VERSION ""

NS_ :

BS_:

BU_:

BO_ 2619670270 TIM21: 16 Vector__XXX
 SG_ RequestCounterAuxValve32 m32 : 8|4@1+ (1,0) [0|0] "" Vector__XXX
 SG_ RequestCounterAuxValve31 m31 : 8|4@1+ (1,0) [0|0] "" Vector__XXX
 SG_ RequestCounterAuxValve30 m30 : 8|4@1+ (1,0) [0|0] "" Vector__XXX
 SG_ RequestCounterAuxValve29 m29 : 8|4@1+ (1,0) [0|0] "" Vector__XXX
 SG_ RequestCounterAuxValve28 m28 : 8|4@1+ (1,0) [0|0] "" Vector__XXX
 SG_ RequestCounterAuxValve27 m27 : 8|4@1+ (1,0) [0|0] "" Vector__XXX
 SG_ RequestCounterAuxValve26 m26 : 8|4@1+ (1,0) [0|0] "" Vector__XXX
 SG_ RequestCounterAuxValve25 m25 : 8|4@1+ (1,0) [0|0] "" Vector__XXX
 SG_ RequestCounterAuxValve24 m24 : 8|4@1+ (1,0) [0|0] "" Vector__XXX
 SG_ RequestCounterAuxValve23 m23 : 8|4@1+ (1,0) [0|0] "" Vector__XXX
 SG_ RequestCounterAuxValve22 m22 : 8|4@1+ (1,0) [0|0] "" Vector__XXX
 SG_ RequestCounterAuxValve21 m21 : 8|4@1+ (1,0) [0|0] "" Vector__XXX
 SG_ RequestCounterAuxValve20 m20 : 8|4@1+ (1,0) [0|0] "" Vector__XXX
 SG_ RequestCounterAuxValve19 m19 : 8|4@1+ (1,0) [0|0] "" Vector__XXX
 SG_ RequestCounterAuxValve18 m18 : 8|4@1+ (1,0) [0|0] "" Vector__XXX
 SG_ RequestCounterAuxValve17 m17 : 8|4@1+ (1,0) [0|0] "" Vector__XXX
 SG_ RequestCounterAuxValve16 m16 : 8|4@1+ (1,0) [0|0] "" Vector__XXX
 SG_ RequestCounterAuxValve15 m15 : 8|4@1+ (1,0) [0|0] "" Vector__XXX
 SG_ RequestCounterAuxValve14 m14 : 8|4@1+ (1,0) [0|0] "" Vector__XXX
 SG_ RequestCounterAuxValve13 m13 : 8|4@1+ (1,0) [0|0] "" Vector__XXX
 SG_ RequestCounterAuxValve12 m12 : 8|4@1+ (1,0) [0|0] "" Vector__XXX
 SG_ RequestCounterAuxValve11 m11 : 8|4@1+ (1,0) [0|0] "" Vector__XXX
 SG_ RequestCounterAuxValve10 m10 : 8|4@1+ (1,0) [0|0] "" Vector__XXX
 SG_ RequestCounterAuxValve09 m9 : 8|4@1+ (1,0) [0|0] "" Vector__XXX
 SG_ RequestCounterAuxValve08 m8 : 8|4@1+ (1,0) [0|0] "" Vector__XXX
 SG_ RequestCounterAuxValve07 m7 : 8|4@1+ (1,0) [0|0] "" Vector__XXX
 SG_ RequestCounterAuxValve06 m6 : 8|4@1+ (1,0) [0|0] "" Vector__XXX
 SG_ RequestCounterAuxValve05 m5 : 8|4@1+ (1,0) [0|0] "" Vector__XXX
 SG_ RequestCounterAuxValve04 m4 : 8|4@1+ (1,0) [0|0] "" Vector__XXX
 SG_ RequestCounterAuxValve03 m3 : 8|4@1+ (1,0) [0|0] "" Vector__XXX
 SG_ RequestCounterAuxValve02 m2 : 8|4@1+ (1,0) [0|0] "" Vector__XXX
 SG_ RequestCounterAuxValve01 m1 : 8|4@1+ (1,0) [0|0] "" Vector__XXX
 SG_ RequestCounterVehicleSpeed m68 : 8|4@1+ (1,0) [0|0] "" Vector__XXX
 SG_ RequestCounterRearHitch m67 : 8|4@1+ (1,0) [0|0] "" Vector__XXX
 SG_ RequestCounterFrontHitch m66 : 8|4@1+ (1,0) [0|0] "" Vector__XXX
 SG_ RequestCounterRearPTO m65 : 8|4@1+ (1,0) [0|0] "" Vector__XXX
 SG_ RequestCounterFrontPTO m64 : 8|4@1+ (1,0) [0|0] "" Vector__XXX
 SG_ RequestCounterExternalGuidance m70 : 8|4@1+ (1,0) [0|0] "" Vector__XXX
 SG_ FlowRequest_AV32 m32 : 32|16@1+ (0.004,-128.512) [0|0] "%" Vector__XXX
 SG_ FlowRequest_AV31 m31 : 32|16@1+ (0.004,-128.512) [0|0] "%" Vector__XXX
 SG_ FlowRequest_AV30 m30 : 32|16@1+ (0.004,-128.512) [0|0] "%" Vector__XXX
 SG_ FlowRequest_AV29 m29 : 32|16@1+ (0.004,-128.512) [0|0] "%" Vector__XXX
 SG_ FlowRequest_AV28 m28 : 32|16@1+ (0.004,-128.512) [0|0] "%" Vector__XXX
 SG_ FlowRequest_AV27 m27 : 32|16@1+ (0.004,-128.512) [0|0] "%" Vector__XXX
 SG_ FlowRequest_AV26 m26 : 32|16@1+ (0.004,-128.512) [0|0] "%" Vector__XXX
 SG_ FlowRequest_AV25 m25 : 32|16@1+ (0.004,-128.512) [0|0] "%" Vector__XXX
 SG_ FlowRequest_AV24 m24 : 32|16@1+ (0.004,-128.512) [0|0] "%" Vector__XXX
 SG_ FlowRequest_AV23 m23 : 32|16@1+ (0.004,-128.512) [0|0] "%" Vector__XXX
 SG_ FlowRequest_AV22 m22 : 32|16@1+ (0.004,-128.512) [0|0] "%" Vector__XXX
 SG_ FlowRequest_AV21 m21 : 32|16@1+ (0.004,-128.512) [0|0] "%" Vector__XXX
 SG_ FlowRequest_AV20 m20 : 32|16@1+ (0.004,-128.512) [0|0] "%" Vector__XXX
 SG_ FlowRequest_AV19 m19 : 32|16@1+ (0.004,-128.512) [0|0] "%" Vector__XXX
 SG_ FlowRequest_AV18 m18 : 32|16@1+ (0.004,-128.512) [0|0] "%" Vector__XXX
 SG_ FlowRequest_AV17 m17 : 32|16@1+ (0.004,-128.512) [0|0] "%" Vector__XXX
 SG_ FlowRequest_AV16 m16 : 32|16@1+ (0.004,-128.512) [0|0] "%" Vector__XXX
 SG_ FlowRequest_AV15 m15 : 32|16@1+ (0.004,-128.512) [0|0] "%" Vector__XXX
 SG_ FlowRequest_AV14 m14 : 32|16@1+ (0.004,-128.512) [0|0] "%" Vector__XXX
 SG_ FlowRequest_AV13 m13 : 32|16@1+ (0.004,-128.512) [0|0] "%" Vector__XXX
 SG_ FlowRequest_AV12 m12 : 32|16@1+ (0.004,-128.512) [0|0] "%" Vector__XXX
 SG_ FlowRequest_AV11 m11 : 32|16@1+ (0.004,-128.512) [0|0] "%" Vector__XXX
 SG_ FlowRequest_AV10 m10 : 32|16@1+ (0.004,-128.512) [0|0] "%" Vector__XXX
 SG_ FlowRequest_AV09 m9 : 32|16@1+ (0.004,-128.512) [0|0] "%" Vector__XXX
 SG_ FlowRequest_AV08 m8 : 32|16@1+ (0.004,-128.512) [0|0] "%" Vector__XXX
 SG_ FlowRequest_AV07 m7 : 32|16@1+ (0.004,-128.512) [0|0] "%" Vector__XXX
 SG_ FlowRequest_AV06 m6 : 32|16@1+ (0.004,-128.512) [0|0] "%" Vector__XXX
 SG_ FlowRequest_AV05 m5 : 32|16@1+ (0.004,-128.512) [0|0] "%" Vector__XXX
 SG_ FlowRequest_AV04 m4 : 32|16@1+ (0.004,-128.512) [0|0] "%" Vector__XXX
 SG_ FlowRequest_AV03 m3 : 32|16@1+ (0.004,-128.512) [0|0] "%" Vector__XXX
 SG_ FlowRequest_AV02 m2 : 32|16@1+ (0.004,-128.512) [0|0] "%" Vector__XXX
 SG_ RearHitchPosRequest m67 : 32|16@1+ (0.01,0) [0|100] "%" Vector__XXX
 SG_ RearPTOSpeedRequest m65 : 32|16@1+ (0.125,-4016) [0|0] "1/min" Vector__XXX
 SG_ MinimumTIMVersion_Resp m247 : 24|8@1+ (1,0) [0|0] "" Vector__XXX
 SG_ ImplementedTIMVersion_Resp m247 : 16|8@1+ (1,0) [0|0] "" Vector__XXX
 SG_ CurvatureRequest m70 : 32|16@1+ (0.25,-8032) [-8032|8031.75] "1/km" Vector__XXX
 SG_ VehicleSpeedRequest m68 : 32|16@1+ (0.001,-32.128) [-32.127|32.127] "m/s" Vector__XXX
 SG_ FrontHitchPosRequest m66 : 32|16@1+ (0.01,0) [0|100] "%" Vector__XXX
 SG_ FrontPTOSpeedRequest m64 : 32|16@1+ (0.125,-4016) [0|0] "1/min" Vector__XXX
 SG_ FlowRequest_AV01 m1 : 32|16@1+ (0.004,-128.512) [0|0] "%" Vector__XXX
 SG_ TIMClientState m249 : 20|4@1+ (1,0) [0|0] "" Vector__XXX
 SG_ ClientHeartbeatCounter m249 : 8|8@1+ (1,0) [0|0] "" Vector__XXX
 SG_ TIMFunctionId_4 m245 : 64|8@1+ (1,0) [0|0] "" Vector__XXX
 SG_ TIMFunctionId_3 m245 : 48|8@1+ (1,0) [0|0] "" Vector__XXX
 SG_ TIMFunctionId_2 m245 : 32|8@1+ (1,0) [0|0] "" Vector__XXX
 SG_ TIMFunctionId_1 m245 : 16|8@1+ (1,0) [0|0] "" Vector__XXX
 SG_ NumOfTIMFunctions m245 : 8|8@1+ (1,0) [1|250] "" Vector__XXX
 SG_ RequestType_4 m245 : 77|3@1+ (1,0) [0|0] "" Vector__XXX
 SG_ RequestType_3 m245 : 61|3@1+ (1,0) [0|0] "" Vector__XXX
 SG_ RequestType_2 m245 : 45|3@1+ (1,0) [0|0] "" Vector__XXX
 SG_ RequestType_1 m245 : 29|3@1+ (1,0) [0|0] "" Vector__XXX
 SG_ MinimumTIMVersion_Req m246 : 24|8@1+ (1,0) [0|0] "" Vector__XXX
 SG_ ImplementedTIMVersion_Req m246 : 16|8@1+ (1,0) [0|0] "" Vector__XXX
 SG_ TIMMessageType m1 : 12|4@1+ (1,0) [0|0] "" Vector__XXX
 SG_ GroupFunctionValue M : 0|8@1+ (1,0) [0|0] "" Vector__XXX

BO_ 2619604734 TIM12: 16 Vector__XXX
 SG_ GroupFunctionValue M : 0|8@1+ (1,0) [0|0] "" Vector__XXX
 SG_ RearHitchPosition m67 : 32|16@1+ (0.01,0) [0|100] "%" Vector__XXX
 SG_ RearPTOSpeed m65 : 32|16@1+ (0.125,-4016) [0|0] "1/min" Vector__XXX
 SG_ FlowAuxValve32 m32 : 32|16@1+ (0.004,-128.512) [0|0] "%" Vector__XXX
 SG_ FlowAuxValve31 m31 : 32|16@1+ (0.004,-128.512) [0|0] "%" Vector__XXX
 SG_ FlowAuxValve30 m30 : 32|16@1+ (0.004,-128.512) [0|0] "%" Vector__XXX
 SG_ FlowAuxValve29 m29 : 32|16@1+ (0.004,-128.512) [0|0] "%" Vector__XXX
 SG_ FlowAuxValve28 m28 : 32|16@1+ (0.004,-128.512) [0|0] "%" Vector__XXX
 SG_ FlowAuxValve27 m27 : 32|16@1+ (0.004,-128.512) [0|0] "%" Vector__XXX
 SG_ FlowAuxValve26 m26 : 32|16@1+ (0.004,-128.512) [0|0] "%" Vector__XXX
 SG_ FlowAuxValve25 m25 : 32|16@1+ (0.004,-128.512) [0|0] "%" Vector__XXX
 SG_ FlowAuxValve24 m24 : 32|16@1+ (0.004,-128.512) [0|0] "%" Vector__XXX
 SG_ FlowAuxValve23 m23 : 32|16@1+ (0.004,-128.512) [0|0] "%" Vector__XXX
 SG_ FlowAuxValve22 m22 : 32|16@1+ (0.004,-128.512) [0|0] "%" Vector__XXX
 SG_ FlowAuxValve21 m21 : 32|16@1+ (0.004,-128.512) [0|0] "%" Vector__XXX
 SG_ FlowAuxValve20 m20 : 32|16@1+ (0.004,-128.512) [0|0] "%" Vector__XXX
 SG_ FlowAuxValve19 m19 : 32|16@1+ (0.004,-128.512) [0|0] "%" Vector__XXX
 SG_ FlowAuxValve18 m18 : 32|16@1+ (0.004,-128.512) [0|0] "%" Vector__XXX
 SG_ FlowAuxValve17 m17 : 32|16@1+ (0.004,-128.512) [0|0] "%" Vector__XXX
 SG_ FlowAuxValve16 m16 : 32|16@1+ (0.004,-128.512) [0|0] "%" Vector__XXX
 SG_ FlowAuxValve15 m15 : 32|16@1+ (0.004,-128.512) [0|0] "%" Vector__XXX
 SG_ FlowAuxValve14 m14 : 32|16@1+ (0.004,-128.512) [0|0] "%" Vector__XXX
 SG_ FlowAuxValve13 m13 : 32|16@1+ (0.004,-128.512) [0|0] "%" Vector__XXX
 SG_ FlowAuxValve12 m12 : 32|16@1+ (0.004,-128.512) [0|0] "%" Vector__XXX
 SG_ FlowAuxValve11 m11 : 32|16@1+ (0.004,-128.512) [0|0] "%" Vector__XXX
 SG_ FlowAuxValve10 m10 : 32|16@1+ (0.004,-128.512) [0|0] "%" Vector__XXX
 SG_ FlowAuxValve09 m9 : 32|16@1+ (0.004,-128.512) [0|0] "%" Vector__XXX
 SG_ FlowAuxValve08 m8 : 32|16@1+ (0.004,-128.512) [0|0] "%" Vector__XXX
 SG_ FlowAuxValve07 m7 : 32|16@1+ (0.004,-128.512) [0|0] "%" Vector__XXX
 SG_ FlowAuxValve06 m6 : 32|16@1+ (0.004,-128.512) [0|0] "%" Vector__XXX
 SG_ FlowAuxValve05 m5 : 32|16@1+ (0.004,-128.512) [0|0] "%" Vector__XXX
 SG_ FlowAuxValve04 m4 : 32|16@1+ (0.004,-128.512) [0|0] "%" Vector__XXX
 SG_ FlowAuxValve03 m3 : 32|16@1+ (0.004,-128.512) [0|0] "%" Vector__XXX
 SG_ FlowAuxValve02 m2 : 32|16@1+ (0.004,-128.512) [0|0] "%" Vector__XXX
 SG_ FlowTypeAuxValve32 m32 : 24|2@1+ (1,0) [0|0] "" Vector__XXX
 SG_ FlowTypeAuxValve31 m31 : 24|2@1+ (1,0) [0|0] "" Vector__XXX
 SG_ FlowTypeAuxValve30 m30 : 24|2@1+ (1,0) [0|0] "" Vector__XXX
 SG_ FlowTypeAuxValve29 m29 : 24|2@1+ (1,0) [0|0] "" Vector__XXX
 SG_ FlowTypeAuxValve28 m28 : 24|2@1+ (1,0) [0|0] "" Vector__XXX
 SG_ FlowTypeAuxValve27 m27 : 24|2@1+ (1,0) [0|0] "" Vector__XXX
 SG_ FlowTypeAuxValve26 m26 : 24|2@1+ (1,0) [0|0] "" Vector__XXX
 SG_ FlowTypeAuxValve25 m25 : 24|2@1+ (1,0) [0|0] "" Vector__XXX
 SG_ FlowTypeAuxValve24 m24 : 24|2@1+ (1,0) [0|0] "" Vector__XXX
 SG_ FlowTypeAuxValve23 m23 : 24|2@1+ (1,0) [0|0] "" Vector__XXX
 SG_ FlowTypeAuxValve22 m22 : 24|2@1+ (1,0) [0|0] "" Vector__XXX
 SG_ FlowTypeAuxValve21 m21 : 24|2@1+ (1,0) [0|0] "" Vector__XXX
 SG_ FlowTypeAuxValve20 m20 : 24|2@1+ (1,0) [0|0] "" Vector__XXX
 SG_ FlowTypeAuxValve19 m19 : 24|2@1+ (1,0) [0|0] "" Vector__XXX
 SG_ FlowTypeAuxValve18 m18 : 24|2@1+ (1,0) [0|0] "" Vector__XXX
 SG_ FlowTypeAuxValve17 m17 : 24|2@1+ (1,0) [0|0] "" Vector__XXX
 SG_ FlowTypeAuxValve16 m16 : 24|2@1+ (1,0) [0|0] "" Vector__XXX
 SG_ FlowTypeAuxValve15 m15 : 24|2@1+ (1,0) [0|0] "" Vector__XXX
 SG_ FlowTypeAuxValve14 m14 : 24|2@1+ (1,0) [0|0] "" Vector__XXX
 SG_ FlowTypeAuxValve13 m13 : 24|2@1+ (1,0) [0|0] "" Vector__XXX
 SG_ FlowTypeAuxValve12 m12 : 24|2@1+ (1,0) [0|0] "" Vector__XXX
 SG_ FlowTypeAuxValve11 m11 : 24|2@1+ (1,0) [0|0] "" Vector__XXX
 SG_ FlowTypeAuxValve10 m10 : 24|2@1+ (1,0) [0|0] "" Vector__XXX
 SG_ FlowTypeAuxValve09 m9 : 24|2@1+ (1,0) [0|0] "" Vector__XXX
 SG_ FlowTypeAuxValve08 m8 : 24|2@1+ (1,0) [0|0] "" Vector__XXX
 SG_ FlowTypeAuxValve07 m7 : 24|2@1+ (1,0) [0|0] "" Vector__XXX
 SG_ FlowTypeAuxValve06 m6 : 24|2@1+ (1,0) [0|0] "" Vector__XXX
 SG_ FlowTypeAuxValve05 m5 : 24|2@1+ (1,0) [0|0] "" Vector__XXX
 SG_ FlowTypeAuxValve04 m4 : 24|2@1+ (1,0) [0|0] "" Vector__XXX
 SG_ FlowTypeAuxValve03 m3 : 24|2@1+ (1,0) [0|0] "" Vector__XXX
 SG_ FlowTypeAuxValve02 m2 : 24|2@1+ (1,0) [0|0] "" Vector__XXX
 SG_ FlowTypeAuxValve01 m1 : 24|2@1+ (1,0) [0|0] "" Vector__XXX
 SG_ ExitReasonCodeRearPTO m65 : 27|5@1+ (1,0) [0|0] "" Vector__XXX
 SG_ ExitReasonCodeRearHitch m67 : 27|5@1+ (1,0) [0|0] "" Vector__XXX
 SG_ ExitReasonCodeAuxValve32 m32 : 27|5@1+ (1,0) [0|0] "" Vector__XXX
 SG_ ExitReasonCodeAuxValve31 m31 : 27|5@1+ (1,0) [0|0] "" Vector__XXX
 SG_ ExitReasonCodeAuxValve30 m30 : 27|5@1+ (1,0) [0|0] "" Vector__XXX
 SG_ ExitReasonCodeAuxValve29 m29 : 27|5@1+ (1,0) [0|0] "" Vector__XXX
 SG_ ExitReasonCodeAuxValve28 m28 : 27|5@1+ (1,0) [0|0] "" Vector__XXX
 SG_ ExitReasonCodeAuxValve27 m27 : 27|5@1+ (1,0) [0|0] "" Vector__XXX
 SG_ ExitReasonCodeAuxValve26 m26 : 27|5@1+ (1,0) [0|0] "" Vector__XXX
 SG_ ExitReasonCodeAuxValve25 m25 : 27|5@1+ (1,0) [0|0] "" Vector__XXX
 SG_ ExitReasonCodeAuxValve24 m24 : 27|5@1+ (1,0) [0|0] "" Vector__XXX
 SG_ ExitReasonCodeAuxValve23 m23 : 27|5@1+ (1,0) [0|0] "" Vector__XXX
 SG_ ExitReasonCodeAuxValve22 m22 : 27|5@1+ (1,0) [0|0] "" Vector__XXX
 SG_ ExitReasonCodeAuxValve21 m21 : 27|5@1+ (1,0) [0|0] "" Vector__XXX
 SG_ ExitReasonCodeAuxValve20 m20 : 27|5@1+ (1,0) [0|0] "" Vector__XXX
 SG_ ExitReasonCodeAuxValve19 m19 : 27|5@1+ (1,0) [0|0] "" Vector__XXX
 SG_ ExitReasonCodeAuxValve18 m18 : 27|5@1+ (1,0) [0|0] "" Vector__XXX
 SG_ ExitReasonCodeAuxValve17 m17 : 27|5@1+ (1,0) [0|0] "" Vector__XXX
 SG_ ExitReasonCodeAuxValve16 m16 : 27|5@1+ (1,0) [0|0] "" Vector__XXX
 SG_ ExitReasonCodeAuxValve15 m15 : 27|5@1+ (1,0) [0|0] "" Vector__XXX
 SG_ ExitReasonCodeAuxValve14 m14 : 27|5@1+ (1,0) [0|0] "" Vector__XXX
 SG_ ExitReasonCodeAuxValve13 m13 : 27|5@1+ (1,0) [0|0] "" Vector__XXX
 SG_ ExitReasonCodeAuxValve12 m12 : 27|5@1+ (1,0) [0|0] "" Vector__XXX
 SG_ ExitReasonCodeAuxValve11 m11 : 27|5@1+ (1,0) [0|0] "" Vector__XXX
 SG_ ExitReasonCodeAuxValve10 m10 : 27|5@1+ (1,0) [0|0] "" Vector__XXX
 SG_ ExitReasonCodeAuxValve09 m9 : 27|5@1+ (1,0) [0|0] "" Vector__XXX
 SG_ ExitReasonCodeAuxValve08 m8 : 27|5@1+ (1,0) [0|0] "" Vector__XXX
 SG_ ExitReasonCodeAuxValve07 m7 : 27|5@1+ (1,0) [0|0] "" Vector__XXX
 SG_ ExitReasonCodeAuxValve06 m6 : 27|5@1+ (1,0) [0|0] "" Vector__XXX
 SG_ ExitReasonCodeAuxValve05 m5 : 27|5@1+ (1,0) [0|0] "" Vector__XXX
 SG_ ExitReasonCodeAuxValve04 m4 : 27|5@1+ (1,0) [0|0] "" Vector__XXX
 SG_ ExitReasonCodeAuxValve03 m3 : 27|5@1+ (1,0) [0|0] "" Vector__XXX
 SG_ ExitReasonCodeAuxValve02 m2 : 27|5@1+ (1,0) [0|0] "" Vector__XXX
 SG_ AutomationStatusAuxValve04 m4 : 16|4@1+ (1,0) [0|0] "" Vector__XXX
 SG_ AutomationStatusAuxValve03 m3 : 16|4@1+ (1,0) [0|0] "" Vector__XXX
 SG_ AutomationStatusAuxValve02 m2 : 16|4@1+ (1,0) [0|0] "" Vector__XXX
 SG_ AutomationStatusAuxValve01 m1 : 16|4@1+ (1,0) [0|0] "" Vector__XXX
 SG_ AutomationStatusExternalGuidance m70 : 16|4@1+ (1,0) [0|0] "" Vector__XXX
 SG_ AutomationStatusVehicleSpeed m68 : 16|4@1+ (1,0) [0|0] "" Vector__XXX
 SG_ AutomationStatusRearHitch m67 : 16|4@1+ (1,0) [0|0] "" Vector__XXX
 SG_ AutomationStatusFrontHitch m66 : 16|4@1+ (1,0) [0|0] "" Vector__XXX
 SG_ AutomationStatusRearPTO m65 : 16|4@1+ (1,0) [0|0] "" Vector__XXX
 SG_ AutomationStatusFrontPTO m64 : 16|4@1+ (1,0) [0|0] "" Vector__XXX
 SG_ AutomationStatusAuxValve32 m32 : 16|4@1+ (1,0) [0|0] "" Vector__XXX
 SG_ AutomationStatusAuxValve31 m31 : 16|4@1+ (1,0) [0|0] "" Vector__XXX
 SG_ AutomationStatusAuxValve30 m30 : 16|4@1+ (1,0) [0|0] "" Vector__XXX
 SG_ AutomationStatusAuxValve29 m29 : 16|4@1+ (1,0) [0|0] "" Vector__XXX
 SG_ AutomationStatusAuxValve28 m28 : 16|4@1+ (1,0) [0|0] "" Vector__XXX
 SG_ AutomationStatusAuxValve27 m27 : 16|4@1+ (1,0) [0|0] "" Vector__XXX
 SG_ AutomationStatusAuxValve26 m26 : 16|4@1+ (1,0) [0|0] "" Vector__XXX
 SG_ AutomationStatusAuxValve25 m25 : 16|4@1+ (1,0) [0|0] "" Vector__XXX
 SG_ AutomationStatusAuxValve24 m24 : 16|4@1+ (1,0) [0|0] "" Vector__XXX
 SG_ AutomationStatusAuxValve23 m23 : 16|4@1+ (1,0) [0|0] "" Vector__XXX
 SG_ AutomationStatusAuxValve22 m22 : 16|4@1+ (1,0) [0|0] "" Vector__XXX
 SG_ AutomationStatusAuxValve21 m21 : 16|4@1+ (1,0) [0|0] "" Vector__XXX
 SG_ AutomationStatusAuxValve20 m20 : 16|4@1+ (1,0) [0|0] "" Vector__XXX
 SG_ AutomationStatusAuxValve19 m19 : 16|4@1+ (1,0) [0|0] "" Vector__XXX
 SG_ AutomationStatusAuxValve18 m18 : 16|4@1+ (1,0) [0|0] "" Vector__XXX
 SG_ AutomationStatusAuxValve17 m17 : 16|4@1+ (1,0) [0|0] "" Vector__XXX
 SG_ AutomationStatusAuxValve16 m16 : 16|4@1+ (1,0) [0|0] "" Vector__XXX
 SG_ AutomationStatusAuxValve15 m15 : 16|4@1+ (1,0) [0|0] "" Vector__XXX
 SG_ AutomationStatusAuxValve14 m14 : 16|4@1+ (1,0) [0|0] "" Vector__XXX
 SG_ AutomationStatusAuxValve13 m13 : 16|4@1+ (1,0) [0|0] "" Vector__XXX
 SG_ AutomationStatusAuxValve12 m12 : 16|4@1+ (1,0) [0|0] "" Vector__XXX
 SG_ AutomationStatusAuxValve11 m11 : 16|4@1+ (1,0) [0|0] "" Vector__XXX
 SG_ AutomationStatusAuxValve10 m10 : 16|4@1+ (1,0) [0|0] "" Vector__XXX
 SG_ AutomationStatusAuxValve09 m9 : 16|4@1+ (1,0) [0|0] "" Vector__XXX
 SG_ AutomationStatusAuxValve08 m8 : 16|4@1+ (1,0) [0|0] "" Vector__XXX
 SG_ AutomationStatusAuxValve07 m7 : 16|4@1+ (1,0) [0|0] "" Vector__XXX
 SG_ AutomationStatusAuxValve06 m6 : 16|4@1+ (1,0) [0|0] "" Vector__XXX
 SG_ AutomationStatusAuxValve05 m5 : 16|4@1+ (1,0) [0|0] "" Vector__XXX
 SG_ NumOfUnassignedServerFcts m243 : 8|8@1+ (1,0) [0|255] "" Vector__XXX
 SG_ Curvature m70 : 32|16@1+ (0.25,-8032) [-8032|8031.75] "1/km" Vector__XXX
 SG_ ExitReasonCodeExternalGuidance m70 : 27|5@1+ (1,0) [0|0] "" Vector__XXX
 SG_ VehicleSpeed m68 : 32|16@1+ (0.001,-32.128) [-32.127|32.127] "m/s" Vector__XXX
 SG_ ExitReasonCodeVehicleSpeed m68 : 27|5@1+ (1,0) [0|0] "" Vector__XXX
 SG_ FrontHitchPosition m66 : 32|16@1+ (0.01,0) [0|100] "%" Vector__XXX
 SG_ ExitReasonCodeFrontHitch m66 : 27|5@1+ (1,0) [0|0] "" Vector__XXX
 SG_ FrontPTOSpeed m64 : 32|16@1+ (0.125,-4016) [0|0] "1/min" Vector__XXX
 SG_ ExitReasonCodeFrontPTO m64 : 27|5@1+ (1,0) [0|0] "" Vector__XXX
 SG_ FlowAuxValve01 m1 : 32|16@1+ (0.004,-128.512) [0|0] "%" Vector__XXX
 SG_ ReflectedRequestCounter m1 : 8|4@1+ (1,0) [0|0] "" Vector__XXX
 SG_ ExitReasonCodeAuxValve01 m1 : 27|5@1+ (1,0) [0|0] "" Vector__XXX
 SG_ TIMSystemOperationState m250 : 24|4@1+ (1,0) [0|15] "" Vector__XXX
 SG_ TIMServerState m250 : 28|4@1+ (1,0) [0|0] "" Vector__XXX
 SG_ TIMSystemState m250 : 16|4@1+ (1,0) [0|0] "" Vector__XXX
 SG_ LeadTIMServerIndication m250 : 20|4@1+ (1,0) [0|0] "" Vector__XXX
 SG_ ServerHeartbeatCounter m250 : 8|8@1+ (1,0) [0|0] "" Vector__XXX
 SG_ AssignmentResult_4 m245 : 77|3@1+ (1,0) [0|0] "" Vector__XXX
 SG_ AssignmentResult_3 m245 : 61|3@1+ (1,0) [0|0] "" Vector__XXX
 SG_ AssignmentResult_2 m245 : 45|3@1+ (1,0) [0|0] "" Vector__XXX
 SG_ AssignmentErrorReason_4 m245 : 72|5@1+ (1,0) [0|0] "" Vector__XXX
 SG_ AssignmentErrorReason_3 m245 : 56|5@1+ (1,0) [0|0] "" Vector__XXX
 SG_ AssignmentErrorReason_2 m245 : 40|5@1+ (1,0) [0|0] "" Vector__XXX
 SG_ AssignmentErrorReason_1 m245 : 24|5@1+ (1,0) [0|0] "" Vector__XXX
 SG_ AssignmentResult_1 m245 : 29|3@1+ (1,0) [0|0] "" Vector__XXX
 SG_ TIMFunctionId_4 m245 : 64|8@1+ (1,0) [0|0] "" Vector__XXX
 SG_ TIMFunctionId_3 m245 : 48|8@1+ (1,0) [0|0] "" Vector__XXX
 SG_ TIMFunctionId_2 m245 : 32|8@1+ (1,0) [0|0] "" Vector__XXX
 SG_ TIMFunctionId_1 m245 : 16|8@1+ (1,0) [0|0] "" Vector__XXX
 SG_ NumOfTIMFunctions m245 : 8|8@1+ (1,0) [1|250] "" Vector__XXX
 SG_ NumOfSupportedTIMFunctions m244 : 8|8@1+ (1,0) [1|250] "" Vector__XXX
 SG_ TIMConnectionVersion m246 : 16|8@1+ (1,0) [0|0] "" Vector__XXX
 SG_ ErrorCode m246 : 8|8@1+ (1,0) [0|0] "" Vector__XXX
 SG_ MinimumTIMVersionNr m248 : 24|8@1+ (1,0) [0|0] "" Vector__XXX
 SG_ ImplementedTIMVersionNr m248 : 16|8@1+ (1,0) [0|0] "" Vector__XXX
 SG_ BootTime m248 : 8|8@1+ (1,0) [0|0] "" Vector__XXX
 SG_ TIMMessageType m1 : 12|4@1+ (1,0) [0|0] "" Vector__XXX

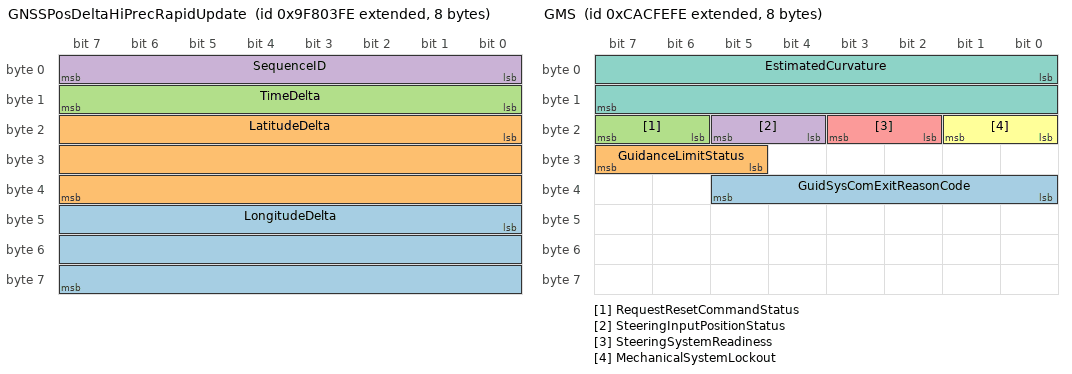
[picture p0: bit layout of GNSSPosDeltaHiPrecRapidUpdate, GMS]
BO_ 2314732542 GNSSPosDeltaHiPrecRapidUpdate: 8 Vector__XXX
 SG_ LongitudeDelta : 40|24@1- (10,0) [0|0] "µsec" Vector__XXX
 SG_ LatitudeDelta : 16|24@1- (10,0) [0|0] "µsec" Vector__XXX
 SG_ TimeDelta : 8|8@1+ (5,0) [0|0] "ms" Vector__XXX
 SG_ SequenceID : 0|8@1+ (1,0) [0|0] "" Vector__XXX

BO_ 2364597502 HRTBTM: 1 Vector__XXX
 SG_ HeartbeatSequenceNumber : 0|8@1+ (1,0) [0|0] "" Vector__XXX

BO_ 2360147710 GMS: 8 Vector__XXX
 SG_ GuidSysComExitReasonCode : 32|6@1+ (1,0) [0|63] "" Vector__XXX
 SG_ GuidanceLimitStatus : 29|3@1+ (1,0) [0|7] "" Vector__XXX
 SG_ RequestResetCommandStatus : 22|2@1+ (1,0) [0|3] "" Vector__XXX
 SG_ SteeringInputPositionStatus : 20|2@1+ (1,0) [0|3] "" Vector__XXX
 SG_ SteeringSystemReadiness : 18|2@1+ (1,0) [0|3] "" Vector__XXX
 SG_ MechanicalSystemLockout : 16|2@1+ (1,0) [0|3] "" Vector__XXX
 SG_ EstimatedCurvature : 0|16@1+ (0.25,-8032) [-8032|8031.75] "1/km" Vector__XXX

BO_ 2360213246 GSC: 8 Vector__XXX
 SG_ CurvatureCommandStatus : 16|2@1+ (1,0) [0|3] "" Vector__XXX
 SG_ CurvatureCommand : 0|16@1+ (0.25,-8032) [-8032|8031.75] "1/km" Vector__XXX

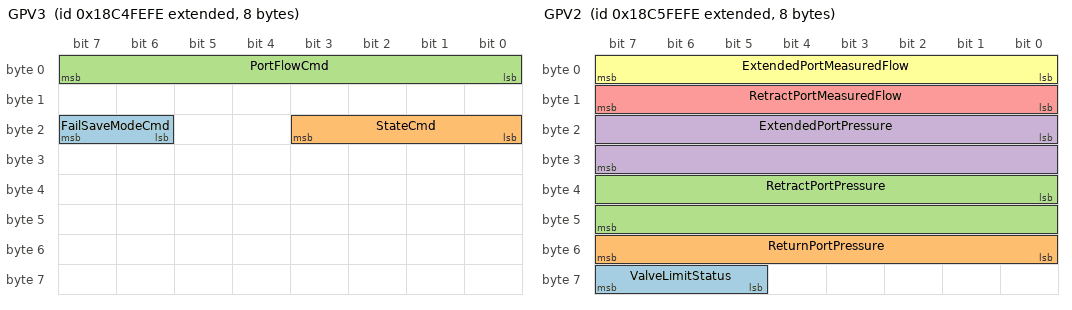
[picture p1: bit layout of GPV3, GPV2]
BO_ 2563047166 GPV3: 8 Vector__XXX
 SG_ FailSaveModeCmd : 22|2@1+ (1,0) [0|3] "" Vector__XXX
 SG_ StateCmd : 16|4@1+ (1,0) [0|15] "" Vector__XXX
 SG_ PortFlowCmd : 0|8@1+ (0.4,0) [0|100] "%" Vector__XXX

BO_ 2563112702 GPV2: 8 Vector__XXX
 SG_ ValveLimitStatus : 61|3@1+ (1,0) [0|7] "" Vector__XXX
 SG_ ReturnPortPressure : 48|8@1+ (16,0) [0|4000] "kPa" Vector__XXX
 SG_ RetractPortPressure : 32|16@1+ (5,0) [0|321275] "kPa" Vector__XXX
 SG_ ExtendedPortPressure : 16|16@1+ (5,0) [0|321275] "kPa" Vector__XXX
 SG_ RetractPortMeasuredFlow : 8|8@1+ (1,-125) [-125|125] "%" Vector__XXX
 SG_ ExtendedPortMeasuredFlow : 0|8@1+ (1,-125) [-125|125] "%" Vector__XXX

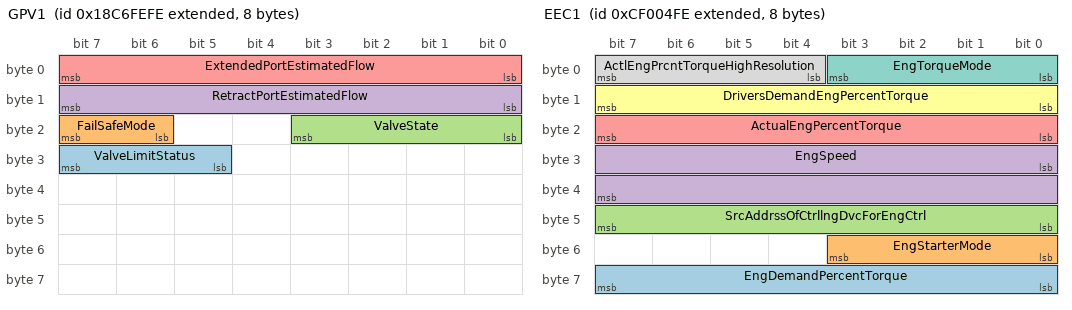
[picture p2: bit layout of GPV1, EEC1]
BO_ 2563178238 GPV1: 8 Vector__XXX
 SG_ ValveLimitStatus : 29|3@1+ (1,0) [0|7] "" Vector__XXX
 SG_ FailSafeMode : 22|2@1+ (1,0) [0|3] "" Vector__XXX
 SG_ ValveState : 16|4@1+ (1,0) [0|15] "" Vector__XXX
 SG_ RetractPortEstimatedFlow : 8|8@1+ (1,-125) [-125|125] "%" Vector__XXX
 SG_ ExtendedPortEstimatedFlow : 0|8@1+ (1,-125) [-125|125] "%" Vector__XXX

BO_ 2628452094 CFS: 9 Vector__XXX
 SG_ VI_VolumeName m64 : 56|16@1+ (1,0) [0|65535] "" Vector__XXX
 SG_ VI_Flag_OverwriteExisting m64 : 48|1@1+ (1,0) [0|1] "" Vector__XXX
 SG_ MF_DestinationPathNameLength m48 : 40|16@1+ (1,0) [0|65535] "" Vector__XXX
 SG_ RF_ReportHiddenFiles m34 : 40|8@1+ (1,0) [0|255] "" Vector__XXX
 SG_ SF_Offset m33 : 32|32@1- (1,0) [-2147483648|2147483647] "" Vector__XXX
 SG_ RF_Count m34 : 24|16@1+ (1,0) [0|65535] "" Vector__XXX
 SG_ SF_PositionMode m33 : 24|8@1+ (1,0) [0|255] "" Vector__XXX
 SG_ OF_PathName m32 : 24|16@1+ (1,0) [0|65535] "" Vector__XXX
 SG_ MF_SourcePathNameLength m48 : 24|16@1+ (1,0) [0|65535] "" Vector__XXX
 SG_ WF_Count m35 : 24|16@1+ (1,0) [0|65535] "" Vector__XXX
 SG_ DF_PathName m49 : 24|16@1+ (1,0) [0|65535] "" Vector__XXX
 SG_ SA_PathName m51 : 24|16@1+ (1,0) [0|65535] "" Vector__XXX
 SG_ VI_Space m64 : 16|32@1+ (1,0) [0|4294967295] "" Vector__XXX
 SG_ OF_FlagExclusiveAccess m32 : 20|1@1+ (1,0) [0|1] "" Vector__XXX
 SG_ OF_FlagAppend m32 : 19|1@1+ (1,0) [0|1] "" Vector__XXX
 SG_ SA_ATTR_Hidden m51 : 18|2@1+ (1,0) [0|3] "" Vector__XXX
 SG_ OF_FlagCreateNew m32 : 18|1@1+ (1,0) [0|1] "" Vector__XXX
 SG_ MF_MoveModeRecursive m48 : 18|1@1+ (1,0) [0|1] "" Vector__XXX
 SG_ DF_DeleteModeRecursive m49 : 18|1@1+ (1,0) [0|1] "" Vector__XXX
 SG_ MF_MoveModeForce m48 : 17|1@1+ (1,0) [0|1] "" Vector__XXX
 SG_ DF_DeleteModeForce m49 : 17|1@1+ (1,0) [0|1] "" Vector__XXX
 SG_ VI_Flag_UsingSpaceSpecified m64 : 49|1@1+ (1,0) [0|1] "" Vector__XXX
 SG_ SA_ATTR_ReadOnly m51 : 16|2@1+ (1,0) [0|3] "" Vector__XXX
 SG_ CF_Handle m36 : 16|8@1+ (1,0) [0|255] "" Vector__XXX
 SG_ WF_Handle m35 : 16|8@1+ (1,0) [0|255] "" Vector__XXX
 SG_ RF_Handle m34 : 16|8@1+ (1,0) [0|255] "" Vector__XXX
 SG_ SF_Handle m33 : 16|8@1+ (1,0) [0|255] "" Vector__XXX
 SG_ OF_FlagReadWrite m32 : 16|2@1+ (1,0) [0|3] "" Vector__XXX
 SG_ CCD_PathName m17 : 16|16@1+ (1,0) [0|65535] "" Vector__XXX
 SG_ MF_MoveModeCopy m48 : 16|1@1+ (1,0) [0|1] "" Vector__XXX
 SG_ DF_DeleteMode m49 : 16|1@1+ (1,0) [0|1] "" Vector__XXX
 SG_ GA_PathName m50 : 16|16@1+ (1,0) [0|65535] "" Vector__XXX
 SG_ FDT_PathName m52 : 16|16@1+ (1,0) [0|65535] "" Vector__XXX
 SG_ VS_VolumeName m2 : 16|16@1+ (1,0) [0|0] "" Vector__XXX
 SG_ VS_ReqVolumeToPrepareForRemoval m2 : 9|1@1- (1,0) [0|1] "" Vector__XXX
 SG_ CCD_TAN m17 : 8|8@1+ (1,0) [0|255] "" Vector__XXX
 SG_ GCD_TAN m16 : 8|8@1+ (1,0) [0|255] "" Vector__XXX
 SG_ FDT_TAN m52 : 8|8@1+ (1,0) [0|255] "" Vector__XXX
 SG_ SA_TAN m51 : 8|8@1+ (1,0) [0|255] "" Vector__XXX
 SG_ GA_TAN m50 : 8|8@1+ (1,0) [0|255] "" Vector__XXX
 SG_ RF_TAN m34 : 8|8@1+ (1,0) [0|255] "" Vector__XXX
 SG_ CF_TAN m36 : 8|8@1+ (1,0) [0|255] "" Vector__XXX
 SG_ WF_TAN m35 : 8|8@1+ (1,0) [0|255] "" Vector__XXX
 SG_ SF_TAN m33 : 8|8@1+ (1,0) [0|255] "" Vector__XXX
 SG_ OF_TAN m32 : 8|8@1+ (1,0) [0|255] "" Vector__XXX
 SG_ MF_TAN m48 : 8|8@1+ (1,0) [0|255] "" Vector__XXX
 SG_ DF_TAN m49 : 8|8@1+ (1,0) [0|255] "" Vector__XXX
 SG_ VI_TAN m64 : 8|8@1+ (1,0) [0|255] "" Vector__XXX
 SG_ VS_ReportVolumeUsedByClient m2 : 8|1@1+ (1,0) [0|1] "" Vector__XXX
 SG_ CM_VersionNumber m0 : 8|8@1+ (1,0) [0|255] "" Vector__XXX
 SG_ FSClientCommand M : 0|8@1+ (1,0) [0|255] "" Vector__XXX

BO_ 2628517630 FSC: 35 Vector__XXX
 SG_ OF_ATTR_VolumeSupportsHidden m32 : 34|1@1+ (1,0) [0|1] "" Vector__XXX
 SG_ GCD_PathName m16 : 88|16@1+ (1,0) [0|65535] "" Vector__XXX
 SG_ GCD_FreeSpace m16 : 56|32@1+ (512,0) [0|4294966744] "Bytes" Vector__XXX
 SG_ FDT_TimeHour m52 : 51|5@1+ (1,0) [0|23] "Hour" Vector__XXX
 SG_ FDT_TimeMinutes m52 : 45|6@1+ (1,0) [0|59] "Minutes" Vector__XXX
 SG_ FDT_TimeSeconds m52 : 40|5@1+ (2,0) [0|58] "Seconds" Vector__XXX
 SG_ OF_ATTR_VolumeIsCaseSensitive m32 : 39|1@1+ (1,0) [0|1] "" Vector__XXX
 SG_ OF_ATTR_VolumeIsRemovable m32 : 38|1@1+ (1,0) [0|1] "" Vector__XXX
 SG_ OF_ATTR_SupportsLongFilenames m32 : 37|1@1+ (1,0) [0|1] "" Vector__XXX
 SG_ OF_ATTR_IsDirectory m32 : 36|1@1+ (1,0) [0|1] "" Vector__XXX
 SG_ OF_ATTR_IsVolume m32 : 35|1@1+ (1,0) [0|1] "" Vector__XXX
 SG_ FDT_DateYear m52 : 33|7@1+ (1,1980) [1980|2107] "Year" Vector__XXX
 SG_ OF_ATTR_Hidden m32 : 33|1@1+ (1,0) [0|1] "" Vector__XXX
 SG_ SF_Position m33 : 32|32@1+ (1,0) [0|4294967295] "" Vector__XXX
 SG_ OF_ATTR_ReadOnly m32 : 32|1@1+ (1,0) [0|1] "" Vector__XXX
 SG_ GA_Size m50 : 32|32@1+ (1,0) [0|4294967295] "" Vector__XXX
 SG_ VS_VolumeName m2 : 32|16@1+ (1,0) [0|65535] "" Vector__XXX
 SG_ VI_VolumeIsCaseSensitive m64 : 31|1@1+ (1,0) [0|1] "" Vector__XXX
 SG_ GA_ATTR_VolumeIsCaseSensitive m50 : 31|1@1+ (1,0) [0|1] "" Vector__XXX
 SG_ VI_ATTR_VolumeRemovable m64 : 30|1@1+ (1,0) [0|1] "" Vector__XXX
 SG_ GA_ATTR_VolumeIsRemovable m50 : 30|1@1+ (1,0) [0|1] "" Vector__XXX
 SG_ VI_ATTR_SupportsLongFilenames m64 : 29|1@1+ (1,0) [0|1] "" Vector__XXX
 SG_ FDT_DateMonth m52 : 29|4@1+ (1,0) [0|12] "Month" Vector__XXX
 SG_ GA_ATTR_SupportsLongFilenames m50 : 29|1@1+ (1,0) [0|1] "" Vector__XXX
 SG_ GA_ATTR_IsDirectory m50 : 28|1@1+ (1,0) [0|1] "" Vector__XXX
 SG_ VI_ATTR_IsDirectory m64 : 28|1@1+ (1,0) [0|1] "" Vector__XXX
 SG_ VI_ATTR_IsVolume m64 : 27|1@1+ (1,0) [0|1] "" Vector__XXX
 SG_ GA_ATTR_IsVolume m50 : 27|1@1+ (1,0) [0|1] "" Vector__XXX
 SG_ VI_ATTR_VolumeSupportsHidden m64 : 26|1@1+ (1,0) [0|1] "" Vector__XXX
 SG_ GA_ATTR_VolumeSupportsHidden m50 : 26|1@1+ (1,0) [0|1] "" Vector__XXX
 SG_ VI_ATTR_Hidden m64 : 25|1@1+ (1,0) [0|1] "" Vector__XXX
 SG_ GA_ATTR_Hidden m50 : 25|1@1+ (1,0) [0|1] "" Vector__XXX
 SG_ VI_ATTR_ReadOnly m64 : 24|1@1+ (1,0) [0|1] "" Vector__XXX
 SG_ FDT_DateDay m52 : 24|5@1+ (1,0) [0|31] "Day" Vector__XXX
 SG_ GA_ATTR_ReadOnly m50 : 24|1@1+ (1,0) [0|1] "" Vector__XXX
 SG_ OF_Handle m32 : 24|8@1+ (1,0) [0|255] "" Vector__XXX
 SG_ GCD_TotalSpace m16 : 24|32@1+ (512,0) [0|4294966744] "Bytes" Vector__XXX
 SG_ RF_Count m34 : 24|16@1+ (1,0) [0|65535] "Bytes" Vector__XXX
 SG_ GSP_SupportMultipleVolumes m1 : 24|1@1+ (1,0) [0|255] "" Vector__XXX
 SG_ WF_Count m35 : 24|16@1+ (1,0) [0|65535] "" Vector__XXX
 SG_ VS_ErrorCode m2 : 24|8@1+ (1,0) [0|255] "" Vector__XXX
 SG_ FDT_ErrorCode m52 : 16|8@1+ (1,0) [0|255] "" Vector__XXX
 SG_ RF_ErrorCode m34 : 16|8@1+ (1,0) [0|255] "" Vector__XXX
 SG_ SF_ErrorCode m33 : 16|8@1+ (1,0) [0|255] "" Vector__XXX
 SG_ FSNumberOfOpenFiles m0 : 16|8@1- (1,0) [0|255] "" Vector__XXX
 SG_ OF_ErrorCode m32 : 16|8@1+ (1,0) [0|255] "" Vector__XXX
 SG_ WF_ErrorCode m35 : 16|8@1+ (1,0) [0|255] "" Vector__XXX
 SG_ CF_ErrorCode m36 : 16|8@1+ (1,0) [0|255] "" Vector__XXX
 SG_ MF_ErrorCode m48 : 16|8@1+ (1,0) [0|255] "" Vector__XXX
 SG_ GA_ErrorCode m50 : 16|8@1+ (1,0) [0|255] "" Vector__XXX
 SG_ SA_ErrorCode m51 : 16|8@1+ (1,0) [0|255] "" Vector__XXX
 SG_ GCD_ErrorCode m16 : 16|8@1+ (1,0) [0|255] "" Vector__XXX
 SG_ CCD_ErrorCode m17 : 16|8@1+ (1,0) [0|255] "" Vector__XXX
 SG_ GSP_MaxNrSimultaneousFilesOpen m1 : 16|8@1+ (1,0) [0|255] "" Vector__XXX
 SG_ DF_ErrorCode m49 : 16|8@1+ (1,0) [0|255] "" Vector__XXX
 SG_ VI_ErrorCode m64 : 16|8@1+ (1,0) [0|255] "" Vector__XXX
 SG_ VS_MaxTimeBeforeVolRemoval m2 : 16|8@1+ (1,0) [0|250] "min/bit" Vector__XXX
 SG_ FSBusyWriting m0 : 9|1@1+ (1,0) [0|1] "" Vector__XXX
 SG_ FSBusyReading m0 : 8|1@1+ (1,0) [0|1] "" Vector__XXX
 SG_ OF_TAN m32 : 8|8@1+ (1,0) [0|255] "" Vector__XXX
 SG_ SF_TAN m33 : 8|8@1+ (1,0) [0|255] "" Vector__XXX
 SG_ RF_TAN m34 : 8|8@1+ (1,0) [0|255] "" Vector__XXX
 SG_ WF_TAN m35 : 8|8@1+ (1,0) [0|255] "" Vector__XXX
 SG_ CF_TAN m36 : 8|8@1+ (1,0) [0|255] "" Vector__XXX
 SG_ MF_TAN m48 : 8|8@1+ (1,0) [0|255] "" Vector__XXX
 SG_ GA_TAN m50 : 8|8@1+ (1,0) [0|255] "" Vector__XXX
 SG_ SA_TAN m51 : 8|8@1+ (1,0) [0|255] "" Vector__XXX
 SG_ FDT_TAN m52 : 8|8@1+ (1,0) [0|255] "" Vector__XXX
 SG_ GCD_TAN m16 : 8|8@1+ (1,0) [0|255] "" Vector__XXX
 SG_ CCD_TAN m17 : 8|8@1+ (1,0) [0|255] "" Vector__XXX
 SG_ GSP_VersionNumber m1 : 8|8@1+ (1,0) [0|255] "" Vector__XXX
 SG_ DF_TAN m49 : 8|8@1+ (1,0) [0|255] "" Vector__XXX
 SG_ VI_TAN m64 : 8|8@1+ (1,0) [0|255] "" Vector__XXX
 SG_ VS_VolumeStatus m2 : 8|8@1+ (1,0) [0|3] "" Vector__XXX
 SG_ FSServerCommand M : 0|8@1+ (1,0) [0|255] "" Vector__XXX

BO_ 2364540158 EEC1: 8 Vector__XXX
 SG_ EngDemandPercentTorque : 56|8@1+ (1,-125) [-125|125] "%" Vector__XXX
 SG_ EngStarterMode : 48|4@1+ (1,0) [0|15] "" Vector__XXX
 SG_ SrcAddrssOfCtrllngDvcForEngCtrl : 40|8@1+ (1,0) [0|255] "" Vector__XXX
 SG_ EngSpeed : 24|16@1+ (0.125,0) [0|8031.875] "rpm" Vector__XXX
 SG_ ActualEngPercentTorque : 16|8@1+ (1,-125) [-125|125] "%" Vector__XXX
 SG_ DriversDemandEngPercentTorque : 8|8@1+ (1,-125) [-125|125] "%" Vector__XXX
 SG_ EngTorqueMode : 0|4@1+ (1,0) [0|15] "" Vector__XXX
 SG_ ActlEngPrcntTorqueHighResolution : 4|4@1+ (0.125,0) [0|0.875] "%" Vector__XXX

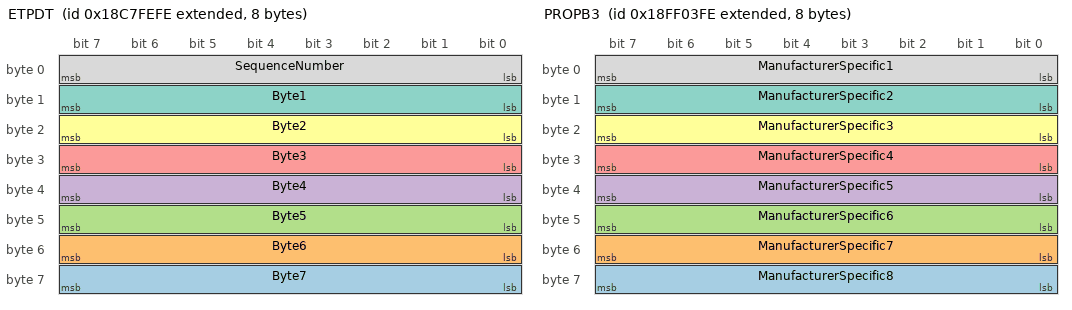
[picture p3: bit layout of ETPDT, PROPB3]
BO_ 2563243774 ETPDT: 8 Vector__XXX
 SG_ Byte7 : 56|8@1+ (1,0) [0|255] "" Vector__XXX
 SG_ Byte6 : 48|8@1+ (1,0) [0|255] "" Vector__XXX
 SG_ Byte5 : 40|8@1+ (1,0) [0|255] "" Vector__XXX
 SG_ Byte4 : 32|8@1+ (1,0) [0|255] "" Vector__XXX
 SG_ Byte3 : 24|8@1+ (1,0) [0|255] "" Vector__XXX
 SG_ Byte2 : 16|8@1+ (1,0) [0|255] "" Vector__XXX
 SG_ Byte1 : 8|8@1+ (1,0) [0|255] "" Vector__XXX
 SG_ SequenceNumber : 0|8@1+ (1,0) [1|255] "" Vector__XXX

BO_ 2563309310 ETPCM: 8 Vector__XXX
 SG_ PGNumber : 40|24@1+ (1,0) [0|16777200] "" Vector__XXX
 SG_ DataPacketOffset m22 : 16|24@1+ (1,0) [0|16777215] "" Vector__XXX
 SG_ NextPacketNumberToSend m21 : 16|24@1+ (1,0) [1|16777215] "" Vector__XXX
 SG_ NumberOfBytesTransfered m23 : 8|32@1+ (1,0) [1786|117440505] "" Vector__XXX
 SG_ NumberOfPacketsOffset m22 : 8|8@1+ (1,0) [1|255] "" Vector__XXX
 SG_ NumberOfPacketsToSend m21 : 8|8@1+ (1,0) [1|255] "" Vector__XXX
 SG_ NumberOfBytesToTransfer m20 : 8|32@1+ (1,0) [1786|117440505] "" Vector__XXX
 SG_ ControlByte M : 0|8@1+ (1,0) [0|255] "" Vector__XXX
 SG_ ConnectionAbortReason m255 : 8|8@1+ (1,0) [0|255] "" Vector__XXX

BO_ 2314732030 GNSSPositionRapidUpdate: 8 Vector__XXX
 SG_ Longitude : 32|32@1- (1E-07,0) [-180|180] "deg" Vector__XXX
 SG_ Latitude : 0|32@1- (1E-07,0) [-90|90] "deg" Vector__XXX

BO_ 2381841918 GNSSPositionData: 63 Vector__XXX
 SG_ Reserved : 258|6@1+ (1,0) [0|0] "" Vector__XXX
 SG_ RefrenceStationType5 : 472|4@1+ (1,0) [0|15] "" Vector__XXX
 SG_ ReferenceStationID5 : 476|12@1+ (1,0) [0|4095] "" Vector__XXX
 SG_ AgeOfDGNSSCorrections5 : 488|16@1+ (0.01,0) [0|655.32] "sec" Vector__XXX
 SG_ RefrenceStationType4 : 440|4@1+ (1,0) [0|15] "" Vector__XXX
 SG_ ReferenceStationID4 : 444|12@1+ (1,0) [0|4095] "" Vector__XXX
 SG_ AgeOfDGNSSCorrections4 : 456|16@1+ (0.01,0) [0|655.32] "sec" Vector__XXX
 SG_ RefrenceStationType3 : 408|4@1+ (1,0) [0|15] "" Vector__XXX
 SG_ ReferenceStationID3 : 412|12@1+ (1,0) [0|4095] "" Vector__XXX
 SG_ AgeOfDGNSSCorrections3 : 424|16@1+ (0.01,0) [0|655.32] "sec" Vector__XXX
 SG_ RefrenceStationType2 : 376|4@1+ (1,0) [0|15] "" Vector__XXX
 SG_ ReferenceStationID2 : 380|12@1+ (1,0) [0|4095] "" Vector__XXX
 SG_ AgeOfDGNSSCorrections2 : 392|16@1+ (0.01,0) [0|655.32] "sec" Vector__XXX
 SG_ AgeOfDGNSSCorrections1 : 360|16@1+ (0.01,0) [0|655.32] "sec" Vector__XXX
 SG_ ReferenceStationID1 : 348|12@1+ (1,0) [0|4095] "" Vector__XXX
 SG_ RefrenceStationType1 : 344|4@1+ (1,0) [0|15] "" Vector__XXX
 SG_ NumberOfReferenceStations : 336|8@1+ (1,0) [0|252] "" Vector__XXX
 SG_ GeoidalSeparation : 304|32@1- (0.01,0) [-21470000|21470000] "m" Vector__XXX
 SG_ PDOP : 288|16@1- (0.01,0) [-327.64|327.64] "" Vector__XXX
 SG_ HDOP : 272|16@1- (0.01,0) [-327.64|327.64] "" Vector__XXX
 SG_ NumberOfSVs : 264|8@1+ (1,0) [0|252] "" Vector__XXX
 SG_ GNSSIntegrity : 256|2@1+ (1,0) [0|3] "" Vector__XXX
 SG_ GNSSMethod : 252|4@1+ (1,0) [0|15] "" Vector__XXX
 SG_ TypeOfSystem : 248|4@1+ (1,0) [0|4] "" Vector__XXX
 SG_ Altitude : 184|64@1- (1E-06,0) [-9223372036854.78|9223372036854.78] "m" Vector__XXX
 SG_ Longitude : 120|64@1- (1E-16,0) [-180|180] "deg" Vector__XXX
 SG_ Latitude : 56|64@1- (1E-16,0) [-90|90] "deg" Vector__XXX
 SG_ PositionTime : 24|32@1+ (0.0001,0) [0|86401] "s" Vector__XXX
 SG_ PositionDate : 8|16@1+ (1,0) [0|65532] "day" Vector__XXX
 SG_ SequenceID : 0|8@1+ (1,0) [0|255] "" Vector__XXX

BO_ 2583299838 GNSSPseudoRangeNoiseStatistic: 15 Vector__XXX
 SG_ STDofAltError : 104|16@1+ (0.01,0) [0|655.32] "m" Vector__XXX
 SG_ STDofLonError : 88|16@1+ (0.01,0) [0|655.32] "m" Vector__XXX
 SG_ STDofLatError : 72|16@1+ (0.01,0) [0|655.32] "m" Vector__XXX
 SG_ OrientationOfMinorAxis : 56|16@1+ (0.0001,0) [0|6.2832] "rad" Vector__XXX
 SG_ STDofMinorAxis : 40|16@1+ (0.01,0) [0|655.32] "m" Vector__XXX
 SG_ STDofMajorAxis : 24|16@1+ (0.01,0) [0|655.32] "m" Vector__XXX
 SG_ RMSofPositionUncertainty : 8|16@1+ (0.01,0) [0|655.32] "m" Vector__XXX
 SG_ SequenceID : 0|8@1+ (1,0) [0|255] "" Vector__XXX

BO_ 2566849534 PROPB3: 8 Vector__XXX
 SG_ ManufacturerSpecific8 : 56|8@1+ (1,0) [0|255] "" Vector__XXX
 SG_ ManufacturerSpecific7 : 48|8@1+ (1,0) [0|255] "" Vector__XXX
 SG_ ManufacturerSpecific6 : 40|8@1+ (1,0) [0|255] "" Vector__XXX
 SG_ ManufacturerSpecific5 : 32|8@1+ (1,0) [0|255] "" Vector__XXX
 SG_ ManufacturerSpecific4 : 24|8@1+ (1,0) [0|255] "" Vector__XXX
 SG_ ManufacturerSpecific3 : 16|8@1+ (1,0) [0|255] "" Vector__XXX
 SG_ ManufacturerSpecific2 : 8|8@1+ (1,0) [0|255] "" Vector__XXX
 SG_ ManufacturerSpecific1 : 0|8@1+ (1,0) [0|255] "" Vector__XXX

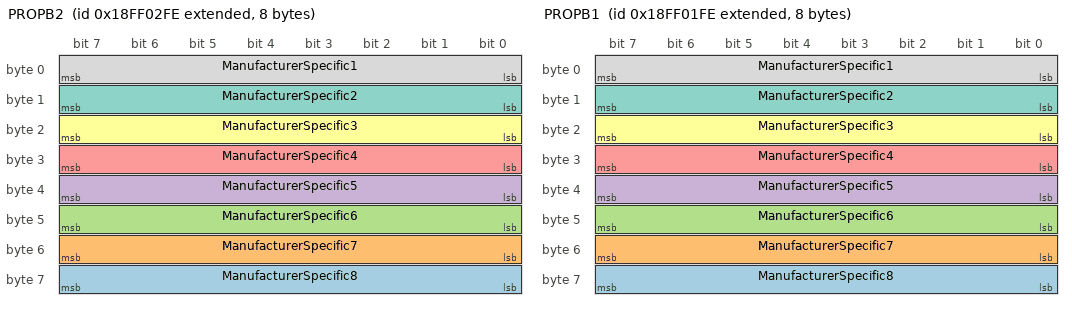
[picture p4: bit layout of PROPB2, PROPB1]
BO_ 2566849278 PROPB2: 8 Vector__XXX
 SG_ ManufacturerSpecific8 : 56|8@1+ (1,0) [0|255] "" Vector__XXX
 SG_ ManufacturerSpecific7 : 48|8@1+ (1,0) [0|255] "" Vector__XXX
 SG_ ManufacturerSpecific6 : 40|8@1+ (1,0) [0|255] "" Vector__XXX
 SG_ ManufacturerSpecific5 : 32|8@1+ (1,0) [0|255] "" Vector__XXX
 SG_ ManufacturerSpecific4 : 24|8@1+ (1,0) [0|255] "" Vector__XXX
 SG_ ManufacturerSpecific3 : 16|8@1+ (1,0) [0|255] "" Vector__XXX
 SG_ ManufacturerSpecific2 : 8|8@1+ (1,0) [0|255] "" Vector__XXX
 SG_ ManufacturerSpecific1 : 0|8@1+ (1,0) [0|255] "" Vector__XXX

BO_ 2566849022 PROPB1: 8 Vector__XXX
 SG_ ManufacturerSpecific8 : 56|8@1+ (1,0) [0|255] "" Vector__XXX
 SG_ ManufacturerSpecific7 : 48|8@1+ (1,0) [0|255] "" Vector__XXX
 SG_ ManufacturerSpecific6 : 40|8@1+ (1,0) [0|255] "" Vector__XXX
 SG_ ManufacturerSpecific5 : 32|8@1+ (1,0) [0|255] "" Vector__XXX
 SG_ ManufacturerSpecific4 : 24|8@1+ (1,0) [0|255] "" Vector__XXX
 SG_ ManufacturerSpecific3 : 16|8@1+ (1,0) [0|255] "" Vector__XXX
 SG_ ManufacturerSpecific2 : 8|8@1+ (1,0) [0|255] "" Vector__XXX
 SG_ ManufacturerSpecific1 : 0|8@1+ (1,0) [0|255] "" Vector__XXX

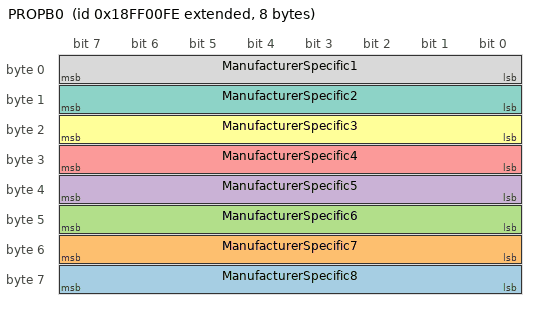
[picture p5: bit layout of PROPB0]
BO_ 2566848766 PROPB0: 8 Vector__XXX
 SG_ ManufacturerSpecific8 : 56|8@1+ (1,0) [0|255] "" Vector__XXX
 SG_ ManufacturerSpecific7 : 48|8@1+ (1,0) [0|255] "" Vector__XXX
 SG_ ManufacturerSpecific6 : 40|8@1+ (1,0) [0|255] "" Vector__XXX
 SG_ ManufacturerSpecific5 : 32|8@1+ (1,0) [0|255] "" Vector__XXX
 SG_ ManufacturerSpecific4 : 24|8@1+ (1,0) [0|255] "" Vector__XXX
 SG_ ManufacturerSpecific3 : 16|8@1+ (1,0) [0|255] "" Vector__XXX
 SG_ ManufacturerSpecific2 : 8|8@1+ (1,0) [0|255] "" Vector__XXX
 SG_ ManufacturerSpecific1 : 0|8@1+ (1,0) [0|255] "" Vector__XXX

CM_ BO_ 2619670270 "TIM message: TIM client to TIM server";
CM_ BO_ 2619604734 "TIM message: TIM server to TIM client";
CM_ BO_ 2314732542 "This PGN is intended for applications where very high precision and very fast update rates are needed for position data 
and only has meaning when it is associated (via the Sequence ID field) with another PGN.";
CM_ SG_ 2314732542 SequenceID "An upward counting number used to tie related information together between different PGNs.";
CM_ BO_ 2360147710 "Guidance Machine Status: It provides information and status from the steering control system to the guidance system.";
CM_ SG_ 2360147710 GuidSysComExitReasonCode "Parameter used to indicate why the guidance system cannot currently accept remote commands or has most 
recently stopped accepting remote commands. ";
CM_ SG_ 2360147710 GuidanceLimitStatus "Parameter used to report the Tractor ECU's present limit status associated with guidance commands that are 
persistent (i.e. not transient/temporary/one-shot). ";
CM_ SG_ 2360147710 RequestResetCommandStatus "The machine steering system request to the automatic guidance system to change Curvature Command Status state.";
CM_ SG_ 2360147710 SteeringInputPositionStatus "The machine steering system indicates if manual steering is in correct position for guidance to function.";
CM_ SG_ 2360147710 SteeringSystemReadiness "The machine steering system indicates that it is free from faults that would preclude guidance system operation.";
CM_ SG_ 2360147710 MechanicalSystemLockout "The state of a lockout switch that allows operators to disable automatic steering system functions.";
CM_ SG_ 2360147710 EstimatedCurvature "The machine steering system's estimate of the curvature of the current turn.";
CM_ BO_ 2360213246 "Guidance System Command";
CM_ SG_ 2360213246 CurvatureCommandStatus "This parameter indicates whether the guidance system is attempting to control steering with this command.";
CM_ SG_ 2360213246 CurvatureCommand "Desired course curvature over ground that a machine's steering system is required to achieve.";
CM_ BO_ 2563047166 "General Purpose valve command";
CM_ BO_ 2563112702 "General Purpose valve measured flow";
CM_ SG_ 2563112702 ValveLimitStatus "Parameter used to report the tractor ECUs present limit status associated with a parameter whose commands are persistent";
CM_ BO_ 2563178238 "General purpose valve estimated flow";
CM_ SG_ 2563178238 ValveLimitStatus "Parameter used to report the tractor ECUs present limit status associated with a parameter whose commands are persistent";
CM_ BO_ 2628452094 "Client (ECU) to File Server message";
CM_ SG_ 2628452094 VI_VolumeName "Length of path name string for Initailize Volume Request";
CM_ SG_ 2628452094 VI_Flag_OverwriteExisting "Create a new volume if not yet existing (fails if existing volume)";
CM_ SG_ 2628452094 MF_DestinationPathNameLength "Length of destination path name string for Move File";
CM_ SG_ 2628452094 RF_ReportHiddenFiles "Report Hidden Files";
CM_ SG_ 2628452094 SF_Offset "Offset for Seek File";
CM_ SG_ 2628452094 RF_Count "Number of bytes or number of directory entries to be read";
CM_ SG_ 2628452094 SF_PositionMode "Position Mode for Seek File";
CM_ SG_ 2628452094 OF_PathName "Length of path name string for Open File";
CM_ SG_ 2628452094 MF_SourcePathNameLength "Length of source path name string for Move File";
CM_ SG_ 2628452094 WF_Count "Byte count of data to be written to file";
CM_ SG_ 2628452094 DF_PathName "Length of path name string for Delete File";
CM_ SG_ 2628452094 SA_PathName "Length of path name string for Set File Attributes";
CM_ SG_ 2628452094 VI_Space "The space in units of 512";
CM_ SG_ 2628452094 OF_FlagExclusiveAccess "Open file with exclusive access (fails if already open)";
CM_ SG_ 2628452094 OF_FlagAppend "Open file for appending data to the end of the file";
CM_ SG_ 2628452094 SA_ATTR_Hidden "Attribute 'hidden'";
CM_ SG_ 2628452094 OF_FlagCreateNew "Create a new file if not yet existing";
CM_ SG_ 2628452094 MF_MoveModeRecursive "Recursive mode for Move File";
CM_ SG_ 2628452094 DF_DeleteModeRecursive "Recursive mode for Move File";
CM_ SG_ 2628452094 MF_MoveModeForce "Force mode for Move File";
CM_ SG_ 2628452094 DF_DeleteModeForce "Force mode for Move File";
CM_ SG_ 2628452094 VI_Flag_UsingSpaceSpecified "Create volume using space specified";
CM_ SG_ 2628452094 SA_ATTR_ReadOnly "Attribute 'read-only'";
CM_ SG_ 2628452094 CF_Handle "Handle for Close File";
CM_ SG_ 2628452094 WF_Handle "Handle for Write File";
CM_ SG_ 2628452094 RF_Handle "Handle for Read File";
CM_ SG_ 2628452094 SF_Handle "Handle for Seek File";
CM_ SG_ 2628452094 OF_FlagReadWrite "Read/Write/Both/Directory Flag for Open File";
CM_ SG_ 2628452094 CCD_PathName "Length of path name string for Change Current Directory";
CM_ SG_ 2628452094 MF_MoveModeCopy "Copy mode for Move File";
CM_ SG_ 2628452094 DF_DeleteMode "Copy mode for Move File";
CM_ SG_ 2628452094 GA_PathName "Length of path name string for Get File Attributes";
CM_ SG_ 2628452094 FDT_PathName "Length of path name string for Get File Date and Time";
CM_ SG_ 2628452094 CCD_TAN "Transaction Number for Change Default Directory";
CM_ SG_ 2628452094 GCD_TAN "Transaction Number for Get Default Directory";
CM_ SG_ 2628452094 FDT_TAN "Transaction Number for Get File Data & Time";
CM_ SG_ 2628452094 SA_TAN "Transaction Number for Set File Attribute";
CM_ SG_ 2628452094 GA_TAN "Transaction Number for Get File Attribute";
CM_ SG_ 2628452094 RF_TAN "Transaction Number for Read File";
CM_ SG_ 2628452094 CF_TAN "Transaction Number for Close File";
CM_ SG_ 2628452094 WF_TAN "Transaction Number for Write File";
CM_ SG_ 2628452094 SF_TAN "Transaction Number for Seek File";
CM_ SG_ 2628452094 OF_TAN "Transaction Number for Open File";
CM_ SG_ 2628452094 MF_TAN "Transaction Number for Move File";
CM_ SG_ 2628452094 DF_TAN "Transaction Number for Delete File";
CM_ SG_ 2628452094 VI_TAN "Transaction Number for Initailize Volume Request";
CM_ SG_ 2628452094 FSClientCommand "File Server - Client Command";
CM_ BO_ 2628517630 "File Server to Client (ECU) message";
CM_ SG_ 2628517630 GCD_PathName "Length of path name string for Get Current Directory";
CM_ SG_ 2628517630 GCD_FreeSpace "Free Volume Space for Get Current Directory";
CM_ SG_ 2628517630 FDT_TimeHour "Hour of File Time";
CM_ SG_ 2628517630 FDT_TimeMinutes "Minutes of File Time";
CM_ SG_ 2628517630 FDT_TimeSeconds "Day of File Time";
CM_ SG_ 2628517630 FDT_DateYear "Year of File Date";
CM_ SG_ 2628517630 SF_Position "Position of Seek File response";
CM_ SG_ 2628517630 GA_Size "The number of bytes in a file.";
CM_ SG_ 2628517630 GA_ATTR_VolumeIsCaseSensitive "GetFileAttribute attribute 'Volume is case-sensitive'";
CM_ SG_ 2628517630 GA_ATTR_VolumeIsRemovable "GetFileAttribute attribute 'Volume is not removable'";
CM_ SG_ 2628517630 FDT_DateMonth "Month of File Date";
CM_ SG_ 2628517630 GA_ATTR_SupportsLongFilenames "GetFileAttribute attribute 'Volume supports long filenames'";
CM_ SG_ 2628517630 GA_ATTR_IsDirectory "GetFileAttribute attribute 'Handle specifies a directory'";
CM_ SG_ 2628517630 VI_ATTR_IsDirectory "File Attribute DirectoryFile Attribute DirectoryFile Attribute DirectoryFile Attribute Directory";
CM_ SG_ 2628517630 GA_ATTR_IsVolume "GetFileAttribute attribute 'Handle specifies a volume'";
CM_ SG_ 2628517630 GA_ATTR_VolumeSupportsHidden "GetFileAttribute attribute 'Volume supports hidden attribute'";
CM_ SG_ 2628517630 GA_ATTR_Hidden "GetFileAttribute attribute 'Hidden'";
CM_ SG_ 2628517630 FDT_DateDay "Day of File Date";
CM_ SG_ 2628517630 GA_ATTR_ReadOnly "GetFileAttribute attribute 'Read-Only'";
CM_ SG_ 2628517630 OF_Handle "Handle for Open File";
CM_ SG_ 2628517630 GCD_TotalSpace "Total Volume Space for Get Current Directory";
CM_ SG_ 2628517630 RF_Count "Number of read bytes or number of read directory entries";
CM_ SG_ 2628517630 GSP_SupportMultipleVolumes "File Server Capabilities for Get File Server Properties";
CM_ SG_ 2628517630 WF_Count "Number of written bytes";
CM_ SG_ 2628517630 FDT_ErrorCode "Error Code for Get File Data & Time";
CM_ SG_ 2628517630 RF_ErrorCode "Error Code for Read File";
CM_ SG_ 2628517630 SF_ErrorCode "ErrorCode for Seek File";
CM_ SG_ 2628517630 FSNumberOfOpenFiles "Number of open files";
CM_ SG_ 2628517630 OF_ErrorCode "Error Code for Open File";
CM_ SG_ 2628517630 WF_ErrorCode "Error Code for Write File";
CM_ SG_ 2628517630 CF_ErrorCode "Error Code for Close File";
CM_ SG_ 2628517630 MF_ErrorCode "Error Code for Move File";
CM_ SG_ 2628517630 GA_ErrorCode "Error Code for Get File Attribute";
CM_ SG_ 2628517630 SA_ErrorCode "Error Code for Set File Attribute";
CM_ SG_ 2628517630 GCD_ErrorCode "ErrorCode for Get Current Directory";
CM_ SG_ 2628517630 CCD_ErrorCode "Error Code for Change Current Directory";
CM_ SG_ 2628517630 GSP_MaxNrSimultaneousFilesOpen "The number of files that can maximally be opened simultaneous at the File Server.";
CM_ SG_ 2628517630 DF_ErrorCode "Error Code for Delete File";
CM_ SG_ 2628517630 VI_ErrorCode "Error Code for Volume Initialization";
CM_ SG_ 2628517630 FSBusyWriting "Busy writing";
CM_ SG_ 2628517630 FSBusyReading "Busy reading";
CM_ SG_ 2628517630 OF_TAN "Transaction Number for Open File";
CM_ SG_ 2628517630 SF_TAN "Transaction Number for Seek File";
CM_ SG_ 2628517630 RF_TAN "Transaction Number for Read File";
CM_ SG_ 2628517630 WF_TAN "Transaction Number for Write File";
CM_ SG_ 2628517630 CF_TAN "Transaction Number for Close File";
CM_ SG_ 2628517630 MF_TAN "Transaction Number for Move File";
CM_ SG_ 2628517630 GA_TAN "Transaction Number for Get File Attributes";
CM_ SG_ 2628517630 SA_TAN "Transaction Number for Set File Attributes";
CM_ SG_ 2628517630 FDT_TAN "Transaction Number for Get File Data & Time";
CM_ SG_ 2628517630 GCD_TAN "Transaction Number for Get Current Directory";
CM_ SG_ 2628517630 CCD_TAN "Transaction Number for Change Current Directory";
CM_ SG_ 2628517630 GSP_VersionNumber "The version of ISO11783-13 that this File Server meets.";
CM_ SG_ 2628517630 DF_TAN "Transaction Number for Delete File";
CM_ SG_ 2628517630 VI_TAN "Transaction Number for Volume Initialization";
CM_ SG_ 2628517630 FSServerCommand "File Server Command";
CM_ BO_ 2364540158 "Electronic Engine Controller #1";
CM_ SG_ 2364540158 EngStarterMode "There are several phases in a starting action and different reasons why a start cannot take place.";
CM_ SG_ 2364540158 SrcAddrssOfCtrllngDvcForEngCtrl "The source address of the SAE J1939 device currently controlling the engine.";
CM_ SG_ 2364540158 ActualEngPercentTorque "The calculated output torque of the engine.";
CM_ SG_ 2364540158 DriversDemandEngPercentTorque "The requested torque output of the engine by the driver.";
CM_ SG_ 2364540158 EngTorqueMode "State signal which indicates which engine torque mode is currently generating, limiting, or controlling the torque.";
CM_ SG_ 2364540158 ActlEngPrcntTorqueHighResolution "This parameter displays an additional torque in percent of the reference engine torque.";
CM_ BO_ 2563243774 "Extended TP (Data)";
CM_ BO_ 2563309310 "Extended TP (Command)";
CM_ BO_ 2314732030 "This PGN provides latitude and longitude referenced to WGS84";
CM_ BO_ 2381841918 "This PGN conveys a comprehensive set of Global Navigation Satellite System (GNSS) parameters, including position 
information
";
CM_ SG_ 2381841918 ReferenceStationID5 "Reference Station ID";
CM_ SG_ 2381841918 AgeOfDGNSSCorrections5 "Age of Differential corrections";
CM_ SG_ 2381841918 ReferenceStationID4 "Reference Station ID";
CM_ SG_ 2381841918 AgeOfDGNSSCorrections4 "Age of Differential corrections";
CM_ SG_ 2381841918 ReferenceStationID3 "Reference Station ID";
CM_ SG_ 2381841918 AgeOfDGNSSCorrections3 "Age of Differential corrections";
CM_ SG_ 2381841918 ReferenceStationID2 "Reference Station ID";
CM_ SG_ 2381841918 AgeOfDGNSSCorrections2 "Age of Differential corrections";
CM_ SG_ 2381841918 AgeOfDGNSSCorrections1 "Age of Differential corrections";
CM_ SG_ 2381841918 ReferenceStationID1 "Reference Station ID";
CM_ SG_ 2381841918 NumberOfReferenceStations "Numeric count, event counter, sequence counter";
CM_ SG_ 2381841918 GeoidalSeparation "The difference between the earth ellipsoid and mean-sea-level (geoid) defined by the reference datum used in the position solution ' -' = mean-sea-level below ellipsoid
";
CM_ SG_ 2381841918 PDOP "Dilution of Precision (DOP) indicates the contribution of satellite configuration geometry to positioning error
";
CM_ SG_ 2381841918 HDOP "Dilution of Precision (DOP) indicates the contribution of satellite configuration geometry to positioning error
";
CM_ SG_ 2381841918 NumberOfSVs "Numeric count, event counter, sequence counter";
CM_ SG_ 2381841918 Altitude "Altitude referenced to WGS-84";
CM_ SG_ 2381841918 Longitude "Longitude referenced to WGS-84";
CM_ SG_ 2381841918 Latitude "Latitude referenced to WGS-84";
CM_ SG_ 2381841918 PositionTime "24 hour clock, 0 =  midnight,  time is in UTC";
CM_ SG_ 2381841918 PositionDate "Days since January 1, 1970,  Date is relative to UTC Time";
CM_ SG_ 2381841918 SequenceID "An upward counting number used to tie related information together between different PGNs.
";
CM_ BO_ 2583299838 "GNSS pseudorange measurement noise statistics can be translated in the position domain in order to give statistical measures 
of the quality of the position solution. Intended for use with a Receiver Autonomous Integrity Monitoring (RAIM) application.
";
CM_ SG_ 2583299838 STDofAltError "Error distances expressed in meters";
CM_ SG_ 2583299838 STDofLonError "Error distances expressed in meters";
CM_ SG_ 2583299838 STDofLatError "Error distances expressed in meters.";
CM_ SG_ 2583299838 OrientationOfMinorAxis "Degrees clockwise relative to True North.";
CM_ SG_ 2583299838 STDofMinorAxis "Error distances expressed in meters.";
CM_ SG_ 2583299838 STDofMajorAxis "Error distances expressed in meters.";
CM_ SG_ 2583299838 RMSofPositionUncertainty "Error distances expressed in meters.";
CM_ SG_ 2583299838 SequenceID "An upward counting number used to tie related information together between different PGNs.
";
CM_ BO_ 2566849534 "Proprietary B3";
CM_ BO_ 2566849278 "Proprietary B2";
CM_ BO_ 2566849022 "Proprietary B1";
CM_ BO_ 2566848766 "Proprietary B0";
BA_DEF_ SG_  "DDI" INT 0 65535;
BA_DEF_ BO_  "SingleFrame" INT 0 1;
BA_DEF_ BO_  "VFrameFormat" ENUM  "StandardCAN","ExtendedCAN","reserved","J1939PG","vector_leerstring";
BA_DEF_ BO_  "GenMsgSendType" ENUM  "cyclic","NotUsed","IfActive","NotUsed","NotUsed","NotUsed","NotUsed","NotUsed","noMsgSendType","vector_leerstring";
BA_DEF_ BO_  "GenMsgCycleTime" INT 0 3600000;
BA_DEF_ BO_  "GenMsgRequestable" INT 0 1;
BA_DEF_ BO_  "GenMsgNrOfRepetition" INT 0 1000000;
BA_DEF_ BO_  "GenMsgCycleTimeFast" INT 0 3600000;
BA_DEF_ SG_  "GenSigInactiveValue" INT 0 0;
BA_DEF_ BO_  "GenMsgFastOnStart" INT 0 100000;
BA_DEF_ BO_  "GenMsgStartDelayTime" INT 0 100000;
BA_DEF_ BO_  "GenMsgILSupport" ENUM  "No","Yes";
BA_DEF_ BO_  "GenMsgDelayTime" INT 0 1000;
BA_DEF_ SG_  "SPN" INT 0 524287;
BA_DEF_ SG_  "GenSigSendType" ENUM  "Cyclic","OnWrite","OnWriteWithRepetition","OnChange","OnChangeWithRepetition","IfActive","IfActiveWithRepetition","NoSigSendType";
BA_DEF_ SG_  "SigType" ENUM  "Default","Range","RangeSigned","ASCII","Discrete","Control","ReferencePGN","DTC","StringDelimiter","StringLength","StringLengthControl","MessageCounter","MessageChecksum";
BA_DEF_ SG_  "GenSigStartValue" INT -2147483648 2147483647;
BA_DEF_ SG_  "GenSigILSupport" ENUM  "No","Yes";
BA_DEF_DEF_  "DDI" 0;
BA_DEF_DEF_  "SingleFrame" 1;
BA_DEF_DEF_  "VFrameFormat" "J1939PG";
BA_DEF_DEF_  "GenMsgSendType" "noMsgSendType";
BA_DEF_DEF_  "GenMsgCycleTime" 0;
BA_DEF_DEF_  "GenMsgRequestable" 1;
BA_DEF_DEF_  "GenMsgNrOfRepetition" 0;
BA_DEF_DEF_  "GenMsgCycleTimeFast" 0;
BA_DEF_DEF_  "GenSigInactiveValue" 0;
BA_DEF_DEF_  "GenMsgFastOnStart" 0;
BA_DEF_DEF_  "GenMsgStartDelayTime" 0;
BA_DEF_DEF_  "GenMsgILSupport" "Yes";
BA_DEF_DEF_  "GenMsgDelayTime" 0;
BA_DEF_DEF_  "SPN" 0;
BA_DEF_DEF_  "GenSigSendType" "NoSigSendType";
BA_DEF_DEF_  "SigType" "Default";
BA_DEF_DEF_  "GenSigStartValue" 0;
BA_DEF_DEF_  "GenSigILSupport" "Yes";
BA_ "GenMsgCycleTime" BO_ 2314732542 100;
BA_ "GenMsgSendType" BO_ 2314732542 0;
BA_ "GenMsgSendType" BO_ 2364597502 0;
BA_ "GenMsgCycleTime" BO_ 2364597502 100;
BA_ "GenMsgSendType" BO_ 2360147710 8.48332452797837E-317;
BA_ "GenMsgCycleTime" BO_ 2360147710 100;
BA_ "GenMsgSendType" BO_ 2360213246 8.48390950170305E-317;
BA_ "GenMsgCycleTime" BO_ 2360213246 100;
BA_ "GenMsgSendType" BO_ 2563047166 8.48466048148473E-317;
BA_ "GenMsgCycleTime" BO_ 2563047166 1000;
BA_ "GenMsgSendType" BO_ 2563112702 8.48555770469758E-317;
BA_ "GenMsgCycleTime" BO_ 2563112702 100;
BA_ "GenMsgSendType" BO_ 2563178238 8.48652212083826E-317;
BA_ "GenMsgCycleTime" BO_ 2563178238 100;
BA_ "GenMsgSendType" BO_ 2314732030 8.51951780093012E-317;
BA_ "GenMsgCycleTime" BO_ 2314732030 100;
BA_ "GenMsgSendType" BO_ 2381841918 8.52390115134002E-317;
BA_ "GenMsgCycleTime" BO_ 2381841918 1000;
BA_ "SingleFrame" BO_ 2381841918 0;
BA_ "GenMsgSendType" BO_ 2583299838 8.52558097453588E-317;
BA_ "GenMsgCycleTime" BO_ 2583299838 1000;
BA_ "SingleFrame" BO_ 2583299838 0;
BA_ "GenMsgSendType" BO_ 2566849534 8.52715012702708E-317;
BA_ "GenMsgCycleTime" BO_ 2566849534 100;
BA_ "GenMsgSendType" BO_ 2566849278 8.52871927951827E-317;
BA_ "GenMsgCycleTime" BO_ 2566849278 100;
BA_ "GenMsgSendType" BO_ 2566849022 8.53028843200946E-317;
BA_ "GenMsgCycleTime" BO_ 2566849022 100;
BA_ "GenMsgSendType" BO_ 2566848766 8.53185758450065E-317;
BA_ "GenMsgCycleTime" BO_ 2566848766 100;
BA_ "SPN" SG_ 2619670270 RequestCounterAuxValve32 13360;
BA_ "SPN" SG_ 2619670270 RequestCounterAuxValve31 13359;
BA_ "SPN" SG_ 2619670270 RequestCounterAuxValve30 13358;
BA_ "SPN" SG_ 2619670270 RequestCounterAuxValve29 13357;
BA_ "SPN" SG_ 2619670270 RequestCounterAuxValve28 13356;
BA_ "SPN" SG_ 2619670270 RequestCounterAuxValve27 13355;
BA_ "SPN" SG_ 2619670270 RequestCounterAuxValve26 13354;
BA_ "SPN" SG_ 2619670270 RequestCounterAuxValve25 13353;
BA_ "SPN" SG_ 2619670270 RequestCounterAuxValve24 13352;
BA_ "SPN" SG_ 2619670270 RequestCounterAuxValve23 13351;
BA_ "SPN" SG_ 2619670270 RequestCounterAuxValve22 13350;
BA_ "SPN" SG_ 2619670270 RequestCounterAuxValve21 13349;
BA_ "SPN" SG_ 2619670270 RequestCounterAuxValve20 13348;
BA_ "SPN" SG_ 2619670270 RequestCounterAuxValve19 13347;
BA_ "SPN" SG_ 2619670270 RequestCounterAuxValve18 13346;
BA_ "SPN" SG_ 2619670270 RequestCounterAuxValve17 13345;
BA_ "SPN" SG_ 2619670270 RequestCounterAuxValve16 13344;
BA_ "SPN" SG_ 2619670270 RequestCounterAuxValve15 13343;
BA_ "SPN" SG_ 2619670270 RequestCounterAuxValve14 13342;
BA_ "SPN" SG_ 2619670270 RequestCounterAuxValve13 13341;
BA_ "SPN" SG_ 2619670270 RequestCounterAuxValve12 13340;
BA_ "SPN" SG_ 2619670270 RequestCounterAuxValve11 13339;
BA_ "SPN" SG_ 2619670270 RequestCounterAuxValve10 13338;
BA_ "SPN" SG_ 2619670270 RequestCounterAuxValve09 13337;
BA_ "SPN" SG_ 2619670270 RequestCounterAuxValve08 13336;
BA_ "SPN" SG_ 2619670270 RequestCounterAuxValve07 13335;
BA_ "SPN" SG_ 2619670270 RequestCounterAuxValve06 13334;
BA_ "SPN" SG_ 2619670270 RequestCounterAuxValve05 13333;
BA_ "SPN" SG_ 2619670270 RequestCounterAuxValve04 13332;
BA_ "SPN" SG_ 2619670270 RequestCounterAuxValve03 13331;
BA_ "SPN" SG_ 2619670270 RequestCounterAuxValve02 13330;
BA_ "SPN" SG_ 2619670270 RequestCounterAuxValve01 13329;
BA_ "SPN" SG_ 2619670270 RequestCounterVehicleSpeed 13328;
BA_ "SPN" SG_ 2619670270 RequestCounterRearHitch 13327;
BA_ "SPN" SG_ 2619670270 RequestCounterFrontHitch 13326;
BA_ "SPN" SG_ 2619670270 RequestCounterRearPTO 13325;
BA_ "SPN" SG_ 2619670270 RequestCounterFrontPTO 13324;
BA_ "SPN" SG_ 2619670270 RequestCounterExternalGuidance 13323;
BA_ "SPN" SG_ 2619670270 FlowRequest_AV32 8810;
BA_ "SigType" SG_ 2619670270 FlowRequest_AV32 1;
BA_ "GenSigStartValue" SG_ 2619670270 FlowRequest_AV32 32128;
BA_ "SigType" SG_ 2619670270 FlowRequest_AV31 1;
BA_ "GenSigStartValue" SG_ 2619670270 FlowRequest_AV31 32128;
BA_ "SPN" SG_ 2619670270 FlowRequest_AV31 8809;
BA_ "SigType" SG_ 2619670270 FlowRequest_AV30 1;
BA_ "GenSigStartValue" SG_ 2619670270 FlowRequest_AV30 32128;
BA_ "SPN" SG_ 2619670270 FlowRequest_AV30 8808;
BA_ "SigType" SG_ 2619670270 FlowRequest_AV29 1;
BA_ "GenSigStartValue" SG_ 2619670270 FlowRequest_AV29 32128;
BA_ "SPN" SG_ 2619670270 FlowRequest_AV29 8807;
BA_ "SigType" SG_ 2619670270 FlowRequest_AV28 1;
BA_ "GenSigStartValue" SG_ 2619670270 FlowRequest_AV28 32128;
BA_ "SPN" SG_ 2619670270 FlowRequest_AV28 8806;
BA_ "SigType" SG_ 2619670270 FlowRequest_AV27 1;
BA_ "GenSigStartValue" SG_ 2619670270 FlowRequest_AV27 32128;
BA_ "SPN" SG_ 2619670270 FlowRequest_AV27 8805;
BA_ "SigType" SG_ 2619670270 FlowRequest_AV26 1;
BA_ "GenSigStartValue" SG_ 2619670270 FlowRequest_AV26 32128;
BA_ "SPN" SG_ 2619670270 FlowRequest_AV26 8804;
BA_ "SigType" SG_ 2619670270 FlowRequest_AV25 1;
BA_ "GenSigStartValue" SG_ 2619670270 FlowRequest_AV25 32128;
BA_ "SPN" SG_ 2619670270 FlowRequest_AV25 8803;
BA_ "SigType" SG_ 2619670270 FlowRequest_AV24 1;
BA_ "GenSigStartValue" SG_ 2619670270 FlowRequest_AV24 32128;
BA_ "SPN" SG_ 2619670270 FlowRequest_AV24 8802;
BA_ "SigType" SG_ 2619670270 FlowRequest_AV23 1;
BA_ "GenSigStartValue" SG_ 2619670270 FlowRequest_AV23 32128;
BA_ "SPN" SG_ 2619670270 FlowRequest_AV23 8801;
BA_ "SigType" SG_ 2619670270 FlowRequest_AV22 1;
BA_ "GenSigStartValue" SG_ 2619670270 FlowRequest_AV22 32128;
BA_ "SPN" SG_ 2619670270 FlowRequest_AV22 8800;
BA_ "SigType" SG_ 2619670270 FlowRequest_AV21 1;
BA_ "GenSigStartValue" SG_ 2619670270 FlowRequest_AV21 32128;
BA_ "SPN" SG_ 2619670270 FlowRequest_AV21 8799;
BA_ "SigType" SG_ 2619670270 FlowRequest_AV20 1;
BA_ "GenSigStartValue" SG_ 2619670270 FlowRequest_AV20 32128;
BA_ "SPN" SG_ 2619670270 FlowRequest_AV20 8798;
BA_ "SigType" SG_ 2619670270 FlowRequest_AV19 1;
BA_ "GenSigStartValue" SG_ 2619670270 FlowRequest_AV19 32128;
BA_ "SPN" SG_ 2619670270 FlowRequest_AV19 8797;
BA_ "SigType" SG_ 2619670270 FlowRequest_AV18 1;
BA_ "GenSigStartValue" SG_ 2619670270 FlowRequest_AV18 32128;
BA_ "SPN" SG_ 2619670270 FlowRequest_AV18 8796;
BA_ "SigType" SG_ 2619670270 FlowRequest_AV17 1;
BA_ "GenSigStartValue" SG_ 2619670270 FlowRequest_AV17 32128;
BA_ "SPN" SG_ 2619670270 FlowRequest_AV17 8795;
BA_ "SigType" SG_ 2619670270 FlowRequest_AV16 1;
BA_ "GenSigStartValue" SG_ 2619670270 FlowRequest_AV16 32128;
BA_ "SPN" SG_ 2619670270 FlowRequest_AV16 8794;
BA_ "SigType" SG_ 2619670270 FlowRequest_AV15 1;
BA_ "GenSigStartValue" SG_ 2619670270 FlowRequest_AV15 32128;
BA_ "SPN" SG_ 2619670270 FlowRequest_AV15 8793;
BA_ "SigType" SG_ 2619670270 FlowRequest_AV14 1;
BA_ "GenSigStartValue" SG_ 2619670270 FlowRequest_AV14 32128;
BA_ "SPN" SG_ 2619670270 FlowRequest_AV14 8792;
BA_ "SigType" SG_ 2619670270 FlowRequest_AV13 1;
BA_ "GenSigStartValue" SG_ 2619670270 FlowRequest_AV13 32128;
BA_ "SPN" SG_ 2619670270 FlowRequest_AV13 8791;
BA_ "SigType" SG_ 2619670270 FlowRequest_AV12 1;
BA_ "GenSigStartValue" SG_ 2619670270 FlowRequest_AV12 32128;
BA_ "SPN" SG_ 2619670270 FlowRequest_AV12 8790;
BA_ "SigType" SG_ 2619670270 FlowRequest_AV11 1;
BA_ "GenSigStartValue" SG_ 2619670270 FlowRequest_AV11 32128;
BA_ "SPN" SG_ 2619670270 FlowRequest_AV11 8789;
BA_ "SigType" SG_ 2619670270 FlowRequest_AV10 1;
BA_ "GenSigStartValue" SG_ 2619670270 FlowRequest_AV10 32128;
BA_ "SPN" SG_ 2619670270 FlowRequest_AV10 8788;
BA_ "SigType" SG_ 2619670270 FlowRequest_AV09 1;
BA_ "GenSigStartValue" SG_ 2619670270 FlowRequest_AV09 32128;
BA_ "SPN" SG_ 2619670270 FlowRequest_AV09 8787;
BA_ "SigType" SG_ 2619670270 FlowRequest_AV08 1;
BA_ "GenSigStartValue" SG_ 2619670270 FlowRequest_AV08 32128;
BA_ "SPN" SG_ 2619670270 FlowRequest_AV08 8786;
BA_ "SigType" SG_ 2619670270 FlowRequest_AV07 1;
BA_ "GenSigStartValue" SG_ 2619670270 FlowRequest_AV07 32128;
BA_ "SPN" SG_ 2619670270 FlowRequest_AV07 8785;
BA_ "SigType" SG_ 2619670270 FlowRequest_AV06 1;
BA_ "GenSigStartValue" SG_ 2619670270 FlowRequest_AV06 32128;
BA_ "SPN" SG_ 2619670270 FlowRequest_AV06 8784;
BA_ "SigType" SG_ 2619670270 FlowRequest_AV05 1;
BA_ "GenSigStartValue" SG_ 2619670270 FlowRequest_AV05 32128;
BA_ "SPN" SG_ 2619670270 FlowRequest_AV05 8783;
BA_ "SigType" SG_ 2619670270 FlowRequest_AV04 1;
BA_ "GenSigStartValue" SG_ 2619670270 FlowRequest_AV04 32128;
BA_ "SPN" SG_ 2619670270 FlowRequest_AV04 8782;
BA_ "SigType" SG_ 2619670270 FlowRequest_AV03 1;
BA_ "GenSigStartValue" SG_ 2619670270 FlowRequest_AV03 32128;
BA_ "SPN" SG_ 2619670270 FlowRequest_AV03 8781;
BA_ "SigType" SG_ 2619670270 FlowRequest_AV02 1;
BA_ "GenSigStartValue" SG_ 2619670270 FlowRequest_AV02 32128;
BA_ "SPN" SG_ 2619670270 FlowRequest_AV02 8780;
BA_ "SigType" SG_ 2619670270 RearHitchPosRequest 1;
BA_ "SPN" SG_ 2619670270 RearHitchPosRequest 8814;
BA_ "SigType" SG_ 2619670270 RearPTOSpeedRequest 1;
BA_ "GenSigStartValue" SG_ 2619670270 RearPTOSpeedRequest 32128;
BA_ "SPN" SG_ 2619670270 RearPTOSpeedRequest 8812;
BA_ "SPN" SG_ 2619670270 MinimumTIMVersion_Resp 13288;
BA_ "SPN" SG_ 2619670270 ImplementedTIMVersion_Resp 13287;
BA_ "SigType" SG_ 2619670270 CurvatureRequest 1;
BA_ "GenSigStartValue" SG_ 2619670270 CurvatureRequest 32128;
BA_ "SPN" SG_ 2619670270 CurvatureRequest 8816;
BA_ "SigType" SG_ 2619670270 VehicleSpeedRequest 1;
BA_ "GenSigStartValue" SG_ 2619670270 VehicleSpeedRequest 32128;
BA_ "SPN" SG_ 2619670270 VehicleSpeedRequest 8815;
BA_ "SigType" SG_ 2619670270 FrontHitchPosRequest 1;
BA_ "SPN" SG_ 2619670270 FrontHitchPosRequest 8813;
BA_ "SigType" SG_ 2619670270 FrontPTOSpeedRequest 1;
BA_ "GenSigStartValue" SG_ 2619670270 FrontPTOSpeedRequest 32128;
BA_ "SPN" SG_ 2619670270 FrontPTOSpeedRequest 8811;
BA_ "SigType" SG_ 2619670270 FlowRequest_AV01 1;
BA_ "GenSigStartValue" SG_ 2619670270 FlowRequest_AV01 32128;
BA_ "SPN" SG_ 2619670270 FlowRequest_AV01 8779;
BA_ "SPN" SG_ 2619670270 TIMClientState 13286;
BA_ "SPN" SG_ 2619670270 ClientHeartbeatCounter 13285;
BA_ "SPN" SG_ 2619670270 NumOfTIMFunctions 23881;
BA_ "GenSigStartValue" SG_ 2619670270 NumOfTIMFunctions 1;
BA_ "SPN" SG_ 2619670270 RequestType_1 23882;
BA_ "SPN" SG_ 2619670270 MinimumTIMVersion_Req 13290;
BA_ "SPN" SG_ 2619670270 ImplementedTIMVersion_Req 13289;
BA_ "SPN" SG_ 2619670270 TIMMessageType 23576;
BA_ "SPN" SG_ 2619670270 GroupFunctionValue 23575;
BA_ "SPN" SG_ 2619604734 GroupFunctionValue 23573;
BA_ "SPN" SG_ 2619604734 RearHitchPosition 8768;
BA_ "SigType" SG_ 2619604734 RearHitchPosition 1;
BA_ "SPN" SG_ 2619604734 RearPTOSpeed 8762;
BA_ "GenSigStartValue" SG_ 2619604734 RearPTOSpeed 32128;
BA_ "SigType" SG_ 2619604734 RearPTOSpeed 1;
BA_ "GenSigStartValue" SG_ 2619604734 FlowAuxValve32 32128;
BA_ "SigType" SG_ 2619604734 FlowAuxValve32 1;
BA_ "SPN" SG_ 2619604734 FlowAuxValve32 8696;
BA_ "GenSigStartValue" SG_ 2619604734 FlowAuxValve31 32128;
BA_ "SigType" SG_ 2619604734 FlowAuxValve31 1;
BA_ "SPN" SG_ 2619604734 FlowAuxValve31 8695;
BA_ "GenSigStartValue" SG_ 2619604734 FlowAuxValve30 32128;
BA_ "SigType" SG_ 2619604734 FlowAuxValve30 1;
BA_ "SPN" SG_ 2619604734 FlowAuxValve30 8694;
BA_ "GenSigStartValue" SG_ 2619604734 FlowAuxValve29 32128;
BA_ "SigType" SG_ 2619604734 FlowAuxValve29 1;
BA_ "SPN" SG_ 2619604734 FlowAuxValve29 8693;
BA_ "GenSigStartValue" SG_ 2619604734 FlowAuxValve28 32128;
BA_ "SigType" SG_ 2619604734 FlowAuxValve28 1;
BA_ "SPN" SG_ 2619604734 FlowAuxValve28 8692;
BA_ "GenSigStartValue" SG_ 2619604734 FlowAuxValve27 32128;
BA_ "SigType" SG_ 2619604734 FlowAuxValve27 1;
BA_ "SPN" SG_ 2619604734 FlowAuxValve27 8691;
BA_ "GenSigStartValue" SG_ 2619604734 FlowAuxValve26 32128;
BA_ "SigType" SG_ 2619604734 FlowAuxValve26 1;
BA_ "SPN" SG_ 2619604734 FlowAuxValve26 8690;
BA_ "GenSigStartValue" SG_ 2619604734 FlowAuxValve25 32128;
BA_ "SigType" SG_ 2619604734 FlowAuxValve25 1;
BA_ "SPN" SG_ 2619604734 FlowAuxValve25 8689;
BA_ "GenSigStartValue" SG_ 2619604734 FlowAuxValve24 32128;
BA_ "SigType" SG_ 2619604734 FlowAuxValve24 1;
BA_ "SPN" SG_ 2619604734 FlowAuxValve24 8688;
BA_ "GenSigStartValue" SG_ 2619604734 FlowAuxValve23 32128;
BA_ "SigType" SG_ 2619604734 FlowAuxValve23 1;
BA_ "SPN" SG_ 2619604734 FlowAuxValve23 8687;
BA_ "GenSigStartValue" SG_ 2619604734 FlowAuxValve22 32128;
BA_ "SigType" SG_ 2619604734 FlowAuxValve22 1;
BA_ "SPN" SG_ 2619604734 FlowAuxValve22 8686;
BA_ "GenSigStartValue" SG_ 2619604734 FlowAuxValve21 32128;
BA_ "SigType" SG_ 2619604734 FlowAuxValve21 1;
BA_ "SPN" SG_ 2619604734 FlowAuxValve21 8685;
BA_ "GenSigStartValue" SG_ 2619604734 FlowAuxValve20 32128;
BA_ "SigType" SG_ 2619604734 FlowAuxValve20 1;
BA_ "SPN" SG_ 2619604734 FlowAuxValve20 8684;
BA_ "GenSigStartValue" SG_ 2619604734 FlowAuxValve19 32128;
BA_ "SigType" SG_ 2619604734 FlowAuxValve19 1;
BA_ "SPN" SG_ 2619604734 FlowAuxValve19 8683;
BA_ "GenSigStartValue" SG_ 2619604734 FlowAuxValve18 32128;
BA_ "SigType" SG_ 2619604734 FlowAuxValve18 1;
BA_ "SPN" SG_ 2619604734 FlowAuxValve18 8682;
BA_ "GenSigStartValue" SG_ 2619604734 FlowAuxValve17 32128;
BA_ "SigType" SG_ 2619604734 FlowAuxValve17 1;
BA_ "SPN" SG_ 2619604734 FlowAuxValve17 8681;
BA_ "GenSigStartValue" SG_ 2619604734 FlowAuxValve16 32128;
BA_ "SigType" SG_ 2619604734 FlowAuxValve16 1;
BA_ "SPN" SG_ 2619604734 FlowAuxValve16 8680;
BA_ "GenSigStartValue" SG_ 2619604734 FlowAuxValve15 32128;
BA_ "SigType" SG_ 2619604734 FlowAuxValve15 1;
BA_ "SPN" SG_ 2619604734 FlowAuxValve15 8679;
BA_ "GenSigStartValue" SG_ 2619604734 FlowAuxValve14 32128;
BA_ "SigType" SG_ 2619604734 FlowAuxValve14 1;
BA_ "SPN" SG_ 2619604734 FlowAuxValve14 8678;
BA_ "GenSigStartValue" SG_ 2619604734 FlowAuxValve13 32128;
BA_ "SigType" SG_ 2619604734 FlowAuxValve13 1;
BA_ "SPN" SG_ 2619604734 FlowAuxValve13 8677;
BA_ "GenSigStartValue" SG_ 2619604734 FlowAuxValve12 32128;
BA_ "SigType" SG_ 2619604734 FlowAuxValve12 1;
BA_ "SPN" SG_ 2619604734 FlowAuxValve12 8676;
BA_ "GenSigStartValue" SG_ 2619604734 FlowAuxValve11 32128;
BA_ "SigType" SG_ 2619604734 FlowAuxValve11 1;
BA_ "SPN" SG_ 2619604734 FlowAuxValve11 8675;
BA_ "GenSigStartValue" SG_ 2619604734 FlowAuxValve10 32128;
BA_ "SigType" SG_ 2619604734 FlowAuxValve10 1;
BA_ "SPN" SG_ 2619604734 FlowAuxValve10 8674;
BA_ "GenSigStartValue" SG_ 2619604734 FlowAuxValve09 32128;
BA_ "SigType" SG_ 2619604734 FlowAuxValve09 1;
BA_ "SPN" SG_ 2619604734 FlowAuxValve09 8673;
BA_ "GenSigStartValue" SG_ 2619604734 FlowAuxValve08 32128;
BA_ "SigType" SG_ 2619604734 FlowAuxValve08 1;
BA_ "SPN" SG_ 2619604734 FlowAuxValve08 8672;
BA_ "GenSigStartValue" SG_ 2619604734 FlowAuxValve07 32128;
BA_ "SigType" SG_ 2619604734 FlowAuxValve07 1;
BA_ "SPN" SG_ 2619604734 FlowAuxValve07 8671;
BA_ "GenSigStartValue" SG_ 2619604734 FlowAuxValve06 32128;
BA_ "SigType" SG_ 2619604734 FlowAuxValve06 1;
BA_ "SPN" SG_ 2619604734 FlowAuxValve06 8670;
BA_ "GenSigStartValue" SG_ 2619604734 FlowAuxValve05 32128;
BA_ "SigType" SG_ 2619604734 FlowAuxValve05 1;
BA_ "SPN" SG_ 2619604734 FlowAuxValve05 8669;
BA_ "GenSigStartValue" SG_ 2619604734 FlowAuxValve04 32128;
BA_ "SigType" SG_ 2619604734 FlowAuxValve04 1;
BA_ "SPN" SG_ 2619604734 FlowAuxValve04 8668;
BA_ "GenSigStartValue" SG_ 2619604734 FlowAuxValve03 32128;
BA_ "SigType" SG_ 2619604734 FlowAuxValve03 1;
BA_ "SPN" SG_ 2619604734 FlowAuxValve03 8667;
BA_ "GenSigStartValue" SG_ 2619604734 FlowAuxValve02 32128;
BA_ "SigType" SG_ 2619604734 FlowAuxValve02 1;
BA_ "SPN" SG_ 2619604734 FlowAuxValve02 8666;
BA_ "SPN" SG_ 2619604734 FlowTypeAuxValve32 13282;
BA_ "SPN" SG_ 2619604734 FlowTypeAuxValve31 13281;
BA_ "SPN" SG_ 2619604734 FlowTypeAuxValve30 13280;
BA_ "SPN" SG_ 2619604734 FlowTypeAuxValve29 13279;
BA_ "SPN" SG_ 2619604734 FlowTypeAuxValve28 13278;
BA_ "SPN" SG_ 2619604734 FlowTypeAuxValve27 13277;
BA_ "SPN" SG_ 2619604734 FlowTypeAuxValve26 13276;
BA_ "SPN" SG_ 2619604734 FlowTypeAuxValve25 13275;
BA_ "SPN" SG_ 2619604734 FlowTypeAuxValve24 13274;
BA_ "SPN" SG_ 2619604734 FlowTypeAuxValve23 13273;
BA_ "SPN" SG_ 2619604734 FlowTypeAuxValve22 13272;
BA_ "SPN" SG_ 2619604734 FlowTypeAuxValve21 13271;
BA_ "SPN" SG_ 2619604734 FlowTypeAuxValve20 13270;
BA_ "SPN" SG_ 2619604734 FlowTypeAuxValve19 13269;
BA_ "SPN" SG_ 2619604734 FlowTypeAuxValve18 13268;
BA_ "SPN" SG_ 2619604734 FlowTypeAuxValve17 13267;
BA_ "SPN" SG_ 2619604734 FlowTypeAuxValve16 13266;
BA_ "SPN" SG_ 2619604734 FlowTypeAuxValve15 13265;
BA_ "SPN" SG_ 2619604734 FlowTypeAuxValve14 13264;
BA_ "SPN" SG_ 2619604734 FlowTypeAuxValve13 13263;
BA_ "SPN" SG_ 2619604734 FlowTypeAuxValve12 13262;
BA_ "SPN" SG_ 2619604734 FlowTypeAuxValve11 13261;
BA_ "SPN" SG_ 2619604734 FlowTypeAuxValve10 13260;
BA_ "SPN" SG_ 2619604734 FlowTypeAuxValve09 13259;
BA_ "SPN" SG_ 2619604734 FlowTypeAuxValve08 13258;
BA_ "SPN" SG_ 2619604734 FlowTypeAuxValve07 13257;
BA_ "SPN" SG_ 2619604734 FlowTypeAuxValve06 13256;
BA_ "SPN" SG_ 2619604734 FlowTypeAuxValve05 13255;
BA_ "SPN" SG_ 2619604734 FlowTypeAuxValve04 13254;
BA_ "SPN" SG_ 2619604734 FlowTypeAuxValve03 13253;
BA_ "SPN" SG_ 2619604734 FlowTypeAuxValve02 13252;
BA_ "SPN" SG_ 2619604734 FlowTypeAuxValve01 13251;
BA_ "SPN" SG_ 2619604734 ExitReasonCodeRearPTO 8766;
BA_ "SPN" SG_ 2619604734 ExitReasonCodeRearHitch 8772;
BA_ "SPN" SG_ 2619604734 ExitReasonCodeAuxValve32 8760;
BA_ "SPN" SG_ 2619604734 ExitReasonCodeAuxValve31 8769;
BA_ "SPN" SG_ 2619604734 ExitReasonCodeAuxValve30 8758;
BA_ "SPN" SG_ 2619604734 ExitReasonCodeAuxValve29 8757;
BA_ "SPN" SG_ 2619604734 ExitReasonCodeAuxValve28 8756;
BA_ "SPN" SG_ 2619604734 ExitReasonCodeAuxValve27 8755;
BA_ "SPN" SG_ 2619604734 ExitReasonCodeAuxValve26 8754;
BA_ "SPN" SG_ 2619604734 ExitReasonCodeAuxValve25 8753;
BA_ "SPN" SG_ 2619604734 ExitReasonCodeAuxValve24 8752;
BA_ "SPN" SG_ 2619604734 ExitReasonCodeAuxValve23 8751;
BA_ "SPN" SG_ 2619604734 ExitReasonCodeAuxValve22 8750;
BA_ "SPN" SG_ 2619604734 ExitReasonCodeAuxValve21 8749;
BA_ "SPN" SG_ 2619604734 ExitReasonCodeAuxValve20 8748;
BA_ "SPN" SG_ 2619604734 ExitReasonCodeAuxValve19 8747;
BA_ "SPN" SG_ 2619604734 ExitReasonCodeAuxValve18 8746;
BA_ "SPN" SG_ 2619604734 ExitReasonCodeAuxValve17 8745;
BA_ "SPN" SG_ 2619604734 ExitReasonCodeAuxValve16 8744;
BA_ "SPN" SG_ 2619604734 ExitReasonCodeAuxValve15 8743;
BA_ "SPN" SG_ 2619604734 ExitReasonCodeAuxValve14 8742;
BA_ "SPN" SG_ 2619604734 ExitReasonCodeAuxValve13 8741;
BA_ "SPN" SG_ 2619604734 ExitReasonCodeAuxValve12 8740;
BA_ "SPN" SG_ 2619604734 ExitReasonCodeAuxValve11 8739;
BA_ "SPN" SG_ 2619604734 ExitReasonCodeAuxValve10 8738;
BA_ "SPN" SG_ 2619604734 ExitReasonCodeAuxValve09 8737;
BA_ "SPN" SG_ 2619604734 ExitReasonCodeAuxValve08 8736;
BA_ "SPN" SG_ 2619604734 ExitReasonCodeAuxValve07 8735;
BA_ "SPN" SG_ 2619604734 ExitReasonCodeAuxValve06 8734;
BA_ "SPN" SG_ 2619604734 ExitReasonCodeAuxValve05 8733;
BA_ "SPN" SG_ 2619604734 ExitReasonCodeAuxValve04 8732;
BA_ "SPN" SG_ 2619604734 ExitReasonCodeAuxValve03 8731;
BA_ "SPN" SG_ 2619604734 ExitReasonCodeAuxValve02 8730;
BA_ "SPN" SG_ 2619604734 AutomationStatusAuxValve04 8700;
BA_ "SPN" SG_ 2619604734 AutomationStatusAuxValve03 8699;
BA_ "SPN" SG_ 2619604734 AutomationStatusAuxValve02 8698;
BA_ "SPN" SG_ 2619604734 AutomationStatusAuxValve01 8697;
BA_ "SPN" SG_ 2619604734 AutomationStatusExternalGuidance 8777;
BA_ "SPN" SG_ 2619604734 AutomationStatusVehicleSpeed 8774;
BA_ "SPN" SG_ 2619604734 AutomationStatusRearHitch 8770;
BA_ "SPN" SG_ 2619604734 AutomationStatusFrontHitch 8769;
BA_ "SPN" SG_ 2619604734 AutomationStatusRearPTO 8764;
BA_ "SPN" SG_ 2619604734 AutomationStatusFrontPTO 8763;
BA_ "SPN" SG_ 2619604734 AutomationStatusAuxValve32 8728;
BA_ "SPN" SG_ 2619604734 AutomationStatusAuxValve31 8727;
BA_ "SPN" SG_ 2619604734 AutomationStatusAuxValve30 8726;
BA_ "SPN" SG_ 2619604734 AutomationStatusAuxValve29 8725;
BA_ "SPN" SG_ 2619604734 AutomationStatusAuxValve28 8724;
BA_ "SPN" SG_ 2619604734 AutomationStatusAuxValve27 8723;
BA_ "SPN" SG_ 2619604734 AutomationStatusAuxValve26 8722;
BA_ "SPN" SG_ 2619604734 AutomationStatusAuxValve25 8721;
BA_ "SPN" SG_ 2619604734 AutomationStatusAuxValve24 8720;
BA_ "SPN" SG_ 2619604734 AutomationStatusAuxValve23 8719;
BA_ "SPN" SG_ 2619604734 AutomationStatusAuxValve22 8718;
BA_ "SPN" SG_ 2619604734 AutomationStatusAuxValve21 8717;
BA_ "SPN" SG_ 2619604734 AutomationStatusAuxValve20 8716;
BA_ "SPN" SG_ 2619604734 AutomationStatusAuxValve19 8715;
BA_ "SPN" SG_ 2619604734 AutomationStatusAuxValve18 8714;
BA_ "SPN" SG_ 2619604734 AutomationStatusAuxValve17 8713;
BA_ "SPN" SG_ 2619604734 AutomationStatusAuxValve16 8712;
BA_ "SPN" SG_ 2619604734 AutomationStatusAuxValve15 8711;
BA_ "SPN" SG_ 2619604734 AutomationStatusAuxValve14 8710;
BA_ "SPN" SG_ 2619604734 AutomationStatusAuxValve13 8709;
BA_ "SPN" SG_ 2619604734 AutomationStatusAuxValve12 8708;
BA_ "SPN" SG_ 2619604734 AutomationStatusAuxValve11 8707;
BA_ "SPN" SG_ 2619604734 AutomationStatusAuxValve10 8706;
BA_ "SPN" SG_ 2619604734 AutomationStatusAuxValve09 8705;
BA_ "SPN" SG_ 2619604734 AutomationStatusAuxValve08 8704;
BA_ "SPN" SG_ 2619604734 AutomationStatusAuxValve07 8703;
BA_ "SPN" SG_ 2619604734 AutomationStatusAuxValve06 8702;
BA_ "SPN" SG_ 2619604734 AutomationStatusAuxValve05 8701;
BA_ "SPN" SG_ 2619604734 NumOfUnassignedServerFcts 23886;
BA_ "SPN" SG_ 2619604734 Curvature 8776;
BA_ "SigType" SG_ 2619604734 Curvature 1;
BA_ "GenSigStartValue" SG_ 2619604734 Curvature 32128;
BA_ "SPN" SG_ 2619604734 ExitReasonCodeExternalGuidance 8778;
BA_ "SPN" SG_ 2619604734 VehicleSpeed 8773;
BA_ "SigType" SG_ 2619604734 VehicleSpeed 1;
BA_ "GenSigStartValue" SG_ 2619604734 VehicleSpeed 32128;
BA_ "SPN" SG_ 2619604734 ExitReasonCodeVehicleSpeed 8775;
BA_ "SPN" SG_ 2619604734 FrontHitchPosition 8767;
BA_ "SigType" SG_ 2619604734 FrontHitchPosition 1;
BA_ "SPN" SG_ 2619604734 ExitReasonCodeFrontHitch 8771;
BA_ "SPN" SG_ 2619604734 FrontPTOSpeed 8761;
BA_ "SigType" SG_ 2619604734 FrontPTOSpeed 1;
BA_ "GenSigStartValue" SG_ 2619604734 FrontPTOSpeed 32128;
BA_ "SPN" SG_ 2619604734 ExitReasonCodeFrontPTO 8765;
BA_ "SPN" SG_ 2619604734 FlowAuxValve01 8665;
BA_ "SigType" SG_ 2619604734 FlowAuxValve01 1;
BA_ "GenSigStartValue" SG_ 2619604734 FlowAuxValve01 32128;
BA_ "SPN" SG_ 2619604734 ReflectedRequestCounter 13250;
BA_ "SPN" SG_ 2619604734 ExitReasonCodeAuxValve01 8729;
BA_ "SPN" SG_ 2619604734 TIMSystemOperationState 13215;
BA_ "SPN" SG_ 2619604734 TIMServerState 13211;
BA_ "SPN" SG_ 2619604734 TIMSystemState 13214;
BA_ "SPN" SG_ 2619604734 LeadTIMServerIndication 23592;
BA_ "SPN" SG_ 2619604734 ServerHeartbeatCounter 13212;
BA_ "SPN" SG_ 2619604734 AssignmentErrorReason_1 23885;
BA_ "SPN" SG_ 2619604734 AssignmentResult_1 23884;
BA_ "SPN" SG_ 2619604734 NumOfTIMFunctions 23883;
BA_ "GenSigStartValue" SG_ 2619604734 NumOfTIMFunctions 1;
BA_ "GenSigStartValue" SG_ 2619604734 NumOfSupportedTIMFunctions 1;
BA_ "SPN" SG_ 2619604734 NumOfSupportedTIMFunctions 23878;
BA_ "SPN" SG_ 2619604734 TIMConnectionVersion 13220;
BA_ "SPN" SG_ 2619604734 ErrorCode 13219;
BA_ "SPN" SG_ 2619604734 MinimumTIMVersionNr 13218;
BA_ "SPN" SG_ 2619604734 ImplementedTIMVersionNr 13217;
BA_ "SPN" SG_ 2619604734 BootTime 13216;
BA_ "SPN" SG_ 2619604734 TIMMessageType 23574;
BA_ "SPN" SG_ 2364597502 HeartbeatSequenceNumber 7345;
BA_ "SigType" SG_ 2364597502 HeartbeatSequenceNumber 1;
BA_ "SPN" SG_ 2360147710 GuidSysComExitReasonCode 5725;
BA_ "SPN" SG_ 2360147710 GuidanceLimitStatus 5726;
BA_ "SigType" SG_ 2360147710 RequestResetCommandStatus 4;
BA_ "SPN" SG_ 2360147710 RequestResetCommandStatus 5240;
BA_ "SigType" SG_ 2360147710 SteeringInputPositionStatus 4;
BA_ "SPN" SG_ 2360147710 SteeringInputPositionStatus 5241;
BA_ "SigType" SG_ 2360147710 SteeringSystemReadiness 4;
BA_ "SPN" SG_ 2360147710 SteeringSystemReadiness 5242;
BA_ "SigType" SG_ 2360147710 MechanicalSystemLockout 4;
BA_ "SPN" SG_ 2360147710 MechanicalSystemLockout 5243;
BA_ "SigType" SG_ 2360147710 EstimatedCurvature 1;
BA_ "SPN" SG_ 2360147710 EstimatedCurvature 5238;
BA_ "SigType" SG_ 2360213246 CurvatureCommandStatus 4;
BA_ "SPN" SG_ 2360213246 CurvatureCommandStatus 5239;
BA_ "SigType" SG_ 2360213246 CurvatureCommand 1;
BA_ "SPN" SG_ 2360213246 CurvatureCommand 5237;
BA_ "SigType" SG_ 2563047166 FailSaveModeCmd 4;
BA_ "SPN" SG_ 2563047166 StateCmd 2933;
BA_ "SPN" SG_ 2563047166 PortFlowCmd 2944;
BA_ "SigType" SG_ 2563047166 PortFlowCmd 1;
BA_ "SPN" SG_ 2563112702 ValveLimitStatus 5192;
BA_ "SPN" SG_ 2563112702 ReturnPortPressure 2943;
BA_ "SigType" SG_ 2563112702 ReturnPortPressure 1;
BA_ "SPN" SG_ 2563112702 RetractPortPressure 2942;
BA_ "SigType" SG_ 2563112702 RetractPortPressure 1;
BA_ "SPN" SG_ 2563112702 ExtendedPortPressure 2941;
BA_ "SigType" SG_ 2563112702 ExtendedPortPressure 1;
BA_ "SPN" SG_ 2563112702 RetractPortMeasuredFlow 2938;
BA_ "SigType" SG_ 2563112702 RetractPortMeasuredFlow 1;
BA_ "SPN" SG_ 2563112702 ExtendedPortMeasuredFlow 2937;
BA_ "SigType" SG_ 2563112702 ExtendedPortMeasuredFlow 1;
BA_ "SPN" SG_ 2563178238 ValveLimitStatus 5193;
BA_ "SPN" SG_ 2563178238 FailSafeMode 2934;
BA_ "SigType" SG_ 2563178238 FailSafeMode 4;
BA_ "SPN" SG_ 2563178238 ValveState 2932;
BA_ "SPN" SG_ 2563178238 RetractPortEstimatedFlow 2940;
BA_ "SigType" SG_ 2563178238 RetractPortEstimatedFlow 1;
BA_ "SPN" SG_ 2563178238 ExtendedPortEstimatedFlow 2939;
BA_ "SigType" SG_ 2563178238 ExtendedPortEstimatedFlow 1;
BA_ "SigType" SG_ 2628452094 VI_VolumeName 9;
BA_ "SigType" SG_ 2628452094 OF_PathName 9;
BA_ "SigType" SG_ 2628452094 DF_PathName 9;
BA_ "SigType" SG_ 2628452094 SA_PathName 9;
BA_ "SigType" SG_ 2628452094 CCD_PathName 9;
BA_ "SigType" SG_ 2628452094 GA_PathName 9;
BA_ "SigType" SG_ 2628452094 FDT_PathName 9;
BA_ "SigType" SG_ 2628452094 VS_VolumeName 8;
BA_ "SigType" SG_ 2628517630 GCD_PathName 9;
BA_ "SigType" SG_ 2628517630 VS_VolumeName 9;
BA_ "SPN" SG_ 2364540158 EngDemandPercentTorque 2432;
BA_ "SigType" SG_ 2364540158 EngDemandPercentTorque 1;
BA_ "SPN" SG_ 2364540158 EngStarterMode 1675;
BA_ "SPN" SG_ 2364540158 SrcAddrssOfCtrllngDvcForEngCtrl 1483;
BA_ "SPN" SG_ 2364540158 EngSpeed 190;
BA_ "SigType" SG_ 2364540158 EngSpeed 1;
BA_ "SPN" SG_ 2364540158 ActualEngPercentTorque 513;
BA_ "SigType" SG_ 2364540158 ActualEngPercentTorque 1;
BA_ "SPN" SG_ 2364540158 DriversDemandEngPercentTorque 512;
BA_ "SigType" SG_ 2364540158 DriversDemandEngPercentTorque 1;
BA_ "SPN" SG_ 2364540158 EngTorqueMode 899;
BA_ "SPN" SG_ 2364540158 ActlEngPrcntTorqueHighResolution 4154;
BA_ "SigType" SG_ 2563243774 Byte7 1;
BA_ "SigType" SG_ 2563243774 Byte6 1;
BA_ "SigType" SG_ 2563243774 Byte5 1;
BA_ "SigType" SG_ 2563243774 Byte4 1;
BA_ "SigType" SG_ 2563243774 Byte3 1;
BA_ "SigType" SG_ 2563243774 Byte2 1;
BA_ "SigType" SG_ 2563243774 Byte1 1;
BA_ "SigType" SG_ 2563243774 SequenceNumber 1;
BA_ "GenSigStartValue" SG_ 2563243774 SequenceNumber 1;
BA_ "SigType" SG_ 2563309310 PGNumber 6;
BA_ "SigType" SG_ 2563309310 DataPacketOffset 1;
BA_ "SigType" SG_ 2563309310 NextPacketNumberToSend 1;
BA_ "GenSigStartValue" SG_ 2563309310 NextPacketNumberToSend 1;
BA_ "SigType" SG_ 2563309310 NumberOfBytesTransfered 1;
BA_ "GenSigStartValue" SG_ 2563309310 NumberOfBytesTransfered 1786;
BA_ "SigType" SG_ 2563309310 NumberOfPacketsOffset 1;
BA_ "GenSigStartValue" SG_ 2563309310 NumberOfPacketsOffset 1;
BA_ "SigType" SG_ 2563309310 NumberOfPacketsToSend 1;
BA_ "GenSigStartValue" SG_ 2563309310 NumberOfPacketsToSend 1;
BA_ "SigType" SG_ 2563309310 NumberOfBytesToTransfer 1;
BA_ "GenSigStartValue" SG_ 2563309310 NumberOfBytesToTransfer 1786;
BA_ "SigType" SG_ 2563309310 ControlByte 1;
BA_ "GenSigStartValue" SG_ 2381841918 Reserved 63;
BA_ "SigType" SG_ 2381841918 ReferenceStationID5 1;
BA_ "SigType" SG_ 2381841918 AgeOfDGNSSCorrections5 1;
BA_ "SigType" SG_ 2381841918 ReferenceStationID4 1;
BA_ "SigType" SG_ 2381841918 AgeOfDGNSSCorrections4 1;
BA_ "SigType" SG_ 2381841918 ReferenceStationID3 1;
BA_ "SigType" SG_ 2381841918 AgeOfDGNSSCorrections3 1;
BA_ "SigType" SG_ 2381841918 ReferenceStationID2 1;
BA_ "SigType" SG_ 2381841918 AgeOfDGNSSCorrections2 1;
BA_ "SigType" SG_ 2381841918 AgeOfDGNSSCorrections1 1;
BA_ "SigType" SG_ 2381841918 ReferenceStationID1 1;
BA_ "SigType" SG_ 2381841918 NumberOfReferenceStations 1;
BA_ "SigType" SG_ 2381841918 GeoidalSeparation 2;
BA_ "SigType" SG_ 2381841918 PDOP 2;
BA_ "SigType" SG_ 2381841918 HDOP 2;
BA_ "SigType" SG_ 2381841918 NumberOfSVs 1;
BA_ "SigType" SG_ 2381841918 GNSSIntegrity 4;
BA_ "SigType" SG_ 2381841918 PositionTime 1;
BA_ "SigType" SG_ 2381841918 PositionDate 1;
BA_ "SigType" SG_ 2381841918 SequenceID 1;
BA_ "SigType" SG_ 2583299838 STDofAltError 1;
BA_ "SigType" SG_ 2583299838 STDofLonError 1;
BA_ "SigType" SG_ 2583299838 STDofLatError 1;
BA_ "SigType" SG_ 2583299838 OrientationOfMinorAxis 1;
BA_ "SigType" SG_ 2583299838 STDofMinorAxis 1;
BA_ "SigType" SG_ 2583299838 STDofMajorAxis 1;
BA_ "SigType" SG_ 2583299838 RMSofPositionUncertainty 1;
BA_ "SigType" SG_ 2583299838 SequenceID 1;
BA_ "SigType" SG_ 2566849534 ManufacturerSpecific8 1;
BA_ "SigType" SG_ 2566849534 ManufacturerSpecific7 1;
BA_ "SigType" SG_ 2566849534 ManufacturerSpecific6 1;
BA_ "SigType" SG_ 2566849534 ManufacturerSpecific5 1;
BA_ "SigType" SG_ 2566849534 ManufacturerSpecific4 1;
BA_ "SigType" SG_ 2566849534 ManufacturerSpecific3 1;
BA_ "SigType" SG_ 2566849534 ManufacturerSpecific2 1;
BA_ "SigType" SG_ 2566849534 ManufacturerSpecific1 1;
BA_ "SigType" SG_ 2566849278 ManufacturerSpecific8 1;
BA_ "SigType" SG_ 2566849278 ManufacturerSpecific7 1;
BA_ "SigType" SG_ 2566849278 ManufacturerSpecific6 1;
BA_ "SigType" SG_ 2566849278 ManufacturerSpecific5 1;
BA_ "SigType" SG_ 2566849278 ManufacturerSpecific4 1;
BA_ "SigType" SG_ 2566849278 ManufacturerSpecific3 1;
BA_ "SigType" SG_ 2566849278 ManufacturerSpecific2 1;
BA_ "SigType" SG_ 2566849278 ManufacturerSpecific1 1;
BA_ "SigType" SG_ 2566849022 ManufacturerSpecific8 1;
BA_ "SigType" SG_ 2566849022 ManufacturerSpecific7 1;
BA_ "SigType" SG_ 2566849022 ManufacturerSpecific6 1;
BA_ "SigType" SG_ 2566849022 ManufacturerSpecific5 1;
BA_ "SigType" SG_ 2566849022 ManufacturerSpecific4 1;
BA_ "SigType" SG_ 2566849022 ManufacturerSpecific3 1;
BA_ "SigType" SG_ 2566849022 ManufacturerSpecific2 1;
BA_ "SigType" SG_ 2566849022 ManufacturerSpecific1 1;
BA_ "SigType" SG_ 2566848766 ManufacturerSpecific8 1;
BA_ "SigType" SG_ 2566848766 ManufacturerSpecific7 1;
BA_ "SigType" SG_ 2566848766 ManufacturerSpecific6 1;
BA_ "SigType" SG_ 2566848766 ManufacturerSpecific5 1;
BA_ "SigType" SG_ 2566848766 ManufacturerSpecific4 1;
BA_ "SigType" SG_ 2566848766 ManufacturerSpecific3 1;
BA_ "SigType" SG_ 2566848766 ManufacturerSpecific2 1;
BA_ "SigType" SG_ 2566848766 ManufacturerSpecific1 1;
VAL_ 2619670270 RequestCounterAuxValve32 15 "NotAvailable_DontCare " 14 "Reserved" ;
VAL_ 2619670270 RequestCounterAuxValve31 15 "NotAvailable_DontCare " 14 "Reserved" ;
VAL_ 2619670270 RequestCounterAuxValve30 15 "NotAvailable_DontCare " 14 "Reserved" ;
VAL_ 2619670270 RequestCounterAuxValve29 15 "NotAvailable_DontCare " 14 "Reserved" ;
VAL_ 2619670270 RequestCounterAuxValve28 15 "NotAvailable_DontCare " 14 "Reserved" ;
VAL_ 2619670270 RequestCounterAuxValve27 15 "NotAvailable_DontCare " 14 "Reserved" ;
VAL_ 2619670270 RequestCounterAuxValve26 15 "NotAvailable_DontCare " 14 "Reserved" ;
VAL_ 2619670270 RequestCounterAuxValve25 15 "NotAvailable_DontCare " 14 "Reserved" ;
VAL_ 2619670270 RequestCounterAuxValve24 15 "NotAvailable_DontCare " 14 "Reserved" ;
VAL_ 2619670270 RequestCounterAuxValve23 15 "NotAvailable_DontCare " 14 "Reserved" ;
VAL_ 2619670270 RequestCounterAuxValve22 15 "NotAvailable_DontCare " 14 "Reserved" ;
VAL_ 2619670270 RequestCounterAuxValve21 15 "NotAvailable_DontCare " 14 "Reserved" ;
VAL_ 2619670270 RequestCounterAuxValve20 15 "NotAvailable_DontCare " 14 "Reserved" ;
VAL_ 2619670270 RequestCounterAuxValve19 15 "NotAvailable_DontCare " 14 "Reserved" ;
VAL_ 2619670270 RequestCounterAuxValve18 15 "NotAvailable_DontCare " 14 "Reserved" ;
VAL_ 2619670270 RequestCounterAuxValve17 15 "NotAvailable_DontCare " 14 "Reserved" ;
VAL_ 2619670270 RequestCounterAuxValve16 15 "NotAvailable_DontCare " 14 "Reserved" ;
VAL_ 2619670270 RequestCounterAuxValve15 15 "NotAvailable_DontCare " 14 "Reserved" ;
VAL_ 2619670270 RequestCounterAuxValve14 15 "NotAvailable_DontCare " 14 "Reserved" ;
VAL_ 2619670270 RequestCounterAuxValve13 15 "NotAvailable_DontCare " 14 "Reserved" ;
VAL_ 2619670270 RequestCounterAuxValve12 15 "NotAvailable_DontCare " 14 "Reserved" ;
VAL_ 2619670270 RequestCounterAuxValve11 15 "NotAvailable_DontCare " 14 "Reserved" ;
VAL_ 2619670270 RequestCounterAuxValve10 15 "NotAvailable_DontCare " 14 "Reserved" ;
VAL_ 2619670270 RequestCounterAuxValve09 15 "NotAvailable_DontCare " 14 "Reserved" ;
VAL_ 2619670270 RequestCounterAuxValve08 15 "NotAvailable_DontCare " 14 "Reserved" ;
VAL_ 2619670270 RequestCounterAuxValve07 15 "NotAvailable_DontCare " 14 "Reserved" ;
VAL_ 2619670270 RequestCounterAuxValve06 15 "NotAvailable_DontCare " 14 "Reserved" ;
VAL_ 2619670270 RequestCounterAuxValve05 15 "NotAvailable_DontCare " 14 "Reserved" ;
VAL_ 2619670270 RequestCounterAuxValve04 15 "NotAvailable_DontCare " 14 "Reserved" ;
VAL_ 2619670270 RequestCounterAuxValve03 15 "NotAvailable_DontCare " 14 "Reserved" ;
VAL_ 2619670270 RequestCounterAuxValve02 15 "NotAvailable_DontCare " 14 "Reserved" ;
VAL_ 2619670270 RequestCounterAuxValve01 15 "NotAvailable_DontCare " 14 "Reserved" ;
VAL_ 2619670270 RequestCounterVehicleSpeed 15 "NotAvailable_DontCare " 14 "Reserved" ;
VAL_ 2619670270 RequestCounterRearHitch 15 "NotAvailable_DontCare " 14 "Reserved" ;
VAL_ 2619670270 RequestCounterFrontHitch 15 "NotAvailable_DontCare " 14 "Reserved" ;
VAL_ 2619670270 RequestCounterRearPTO 15 "NotAvailable_DontCare " 14 "Reserved" ;
VAL_ 2619670270 RequestCounterFrontPTO 15 "NotAvailable_DontCare " 14 "Reserved" ;
VAL_ 2619670270 RequestCounterExternalGuidance 15 "NotAvailable_DontCare " 14 "Reserved" ;
VAL_ 2619670270 FlowRequest_AV32 64511 "ReadyToControl" 64509 "ReleasedControlRequestingOperatorActionBeforeFunctionValueIncreases" 64257 "Float" 64256 "ValveFullyOpened_Retract" 32128 "Block" 0 "ValveFullyOpened_Extend" ;
VAL_ 2619670270 FlowRequest_AV31 64511 "ReadyToControl" 64509 "ReleasedControlRequestingOperatorActionBeforeFunctionValueIncreases" 64257 "Float" 64256 "ValveFullyOpened_Retract" 32128 "Block" 0 "ValveFullyOpened_Extend" ;
VAL_ 2619670270 FlowRequest_AV30 64511 "ReadyToControl" 64509 "ReleasedControlRequestingOperatorActionBeforeFunctionValueIncreases" 64257 "Float" 64256 "ValveFullyOpened_Retract" 32128 "Block" 0 "ValveFullyOpened_Extend" ;
VAL_ 2619670270 FlowRequest_AV29 64511 "ReadyToControl" 64509 "ReleasedControlRequestingOperatorActionBeforeFunctionValueIncreases" 64257 "Float" 64256 "ValveFullyOpened_Retract" 32128 "Block" 0 "ValveFullyOpened_Extend" ;
VAL_ 2619670270 FlowRequest_AV28 64511 "ReadyToControl" 64509 "ReleasedControlRequestingOperatorActionBeforeFunctionValueIncreases" 64257 "Float" 64256 "ValveFullyOpened_Retract" 32128 "Block" 0 "ValveFullyOpened_Extend" ;
VAL_ 2619670270 FlowRequest_AV27 64511 "ReadyToControl" 64509 "ReleasedControlRequestingOperatorActionBeforeFunctionValueIncreases" 64257 "Float" 64256 "ValveFullyOpened_Retract" 32128 "Block" 0 "ValveFullyOpened_Extend" ;
VAL_ 2619670270 FlowRequest_AV26 64511 "ReadyToControl" 64509 "ReleasedControlRequestingOperatorActionBeforeFunctionValueIncreases" 64257 "Float" 64256 "ValveFullyOpened_Retract" 32128 "Block" 0 "ValveFullyOpened_Extend" ;
VAL_ 2619670270 FlowRequest_AV25 64511 "ReadyToControl" 64509 "ReleasedControlRequestingOperatorActionBeforeFunctionValueIncreases" 64257 "Float" 64256 "ValveFullyOpened_Retract" 32128 "Block" 0 "ValveFullyOpened_Extend" ;
VAL_ 2619670270 FlowRequest_AV24 64511 "ReadyToControl" 64509 "ReleasedControlRequestingOperatorActionBeforeFunctionValueIncreases" 64257 "Float" 64256 "ValveFullyOpened_Retract" 32128 "Block" 0 "ValveFullyOpened_Extend" ;
VAL_ 2619670270 FlowRequest_AV23 64511 "ReadyToControl" 64509 "ReleasedControlRequestingOperatorActionBeforeFunctionValueIncreases" 64257 "Float" 64256 "ValveFullyOpened_Retract" 32128 "Block" 0 "ValveFullyOpened_Extend" ;
VAL_ 2619670270 FlowRequest_AV22 64511 "ReadyToControl" 64509 "ReleasedControlRequestingOperatorActionBeforeFunctionValueIncreases" 64257 "Float" 64256 "ValveFullyOpened_Retract" 32128 "Block" 0 "ValveFullyOpened_Extend" ;
VAL_ 2619670270 FlowRequest_AV21 64511 "ReadyToControl" 64509 "ReleasedControlRequestingOperatorActionBeforeFunctionValueIncreases" 64257 "Float" 64256 "ValveFullyOpened_Retract" 32128 "Block" 0 "ValveFullyOpened_Extend" ;
VAL_ 2619670270 FlowRequest_AV20 64511 "ReadyToControl" 64509 "ReleasedControlRequestingOperatorActionBeforeFunctionValueIncreases" 64257 "Float" 64256 "ValveFullyOpened_Retract" 32128 "Block" 0 "ValveFullyOpened_Extend" ;
VAL_ 2619670270 FlowRequest_AV19 64511 "ReadyToControl" 64509 "ReleasedControlRequestingOperatorActionBeforeFunctionValueIncreases" 64257 "Float" 64256 "ValveFullyOpened_Retract" 32128 "Block" 0 "ValveFullyOpened_Extend" ;
VAL_ 2619670270 FlowRequest_AV18 64511 "ReadyToControl" 64509 "ReleasedControlRequestingOperatorActionBeforeFunctionValueIncreases" 64257 "Float" 64256 "ValveFullyOpened_Retract" 32128 "Block" 0 "ValveFullyOpened_Extend" ;
VAL_ 2619670270 FlowRequest_AV17 64511 "ReadyToControl" 64509 "ReleasedControlRequestingOperatorActionBeforeFunctionValueIncreases" 64257 "Float" 64256 "ValveFullyOpened_Retract" 32128 "Block" 0 "ValveFullyOpened_Extend" ;
VAL_ 2619670270 FlowRequest_AV16 64511 "ReadyToControl" 64509 "ReleasedControlRequestingOperatorActionBeforeFunctionValueIncreases" 64257 "Float" 64256 "ValveFullyOpened_Retract" 32128 "Block" 0 "ValveFullyOpened_Extend" ;
VAL_ 2619670270 FlowRequest_AV15 64511 "ReadyToControl" 64509 "ReleasedControlRequestingOperatorActionBeforeFunctionValueIncreases" 64257 "Float" 64256 "ValveFullyOpened_Retract" 32128 "Block" 0 "ValveFullyOpened_Extend" ;
VAL_ 2619670270 FlowRequest_AV14 64511 "ReadyToControl" 64509 "ReleasedControlRequestingOperatorActionBeforeFunctionValueIncreases" 64257 "Float" 64256 "ValveFullyOpened_Retract" 32128 "Block" 0 "ValveFullyOpened_Extend" ;
VAL_ 2619670270 FlowRequest_AV13 64511 "ReadyToControl" 64509 "ReleasedControlRequestingOperatorActionBeforeFunctionValueIncreases" 64257 "Float" 64256 "ValveFullyOpened_Retract" 32128 "Block" 0 "ValveFullyOpened_Extend" ;
VAL_ 2619670270 FlowRequest_AV12 64511 "ReadyToControl" 64509 "ReleasedControlRequestingOperatorActionBeforeFunctionValueIncreases" 64257 "Float" 64256 "ValveFullyOpened_Retract" 32128 "Block" 0 "ValveFullyOpened_Extend" ;
VAL_ 2619670270 FlowRequest_AV11 64511 "ReadyToControl" 64509 "ReleasedControlRequestingOperatorActionBeforeFunctionValueIncreases" 64257 "Float" 64256 "ValveFullyOpened_Retract" 32128 "Block" 0 "ValveFullyOpened_Extend" ;
VAL_ 2619670270 FlowRequest_AV10 64511 "ReadyToControl" 64509 "ReleasedControlRequestingOperatorActionBeforeFunctionValueIncreases" 64257 "Float" 64256 "ValveFullyOpened_Retract" 32128 "Block" 0 "ValveFullyOpened_Extend" ;
VAL_ 2619670270 FlowRequest_AV09 64511 "ReadyToControl" 64509 "ReleasedControlRequestingOperatorActionBeforeFunctionValueIncreases" 64257 "Float" 64256 "ValveFullyOpened_Retract" 32128 "Block" 0 "ValveFullyOpened_Extend" ;
VAL_ 2619670270 FlowRequest_AV08 64511 "ReadyToControl" 64509 "ReleasedControlRequestingOperatorActionBeforeFunctionValueIncreases" 64257 "Float" 64256 "ValveFullyOpened_Retract" 32128 "Block" 0 "ValveFullyOpened_Extend" ;
VAL_ 2619670270 FlowRequest_AV07 64511 "ReadyToControl" 64509 "ReleasedControlRequestingOperatorActionBeforeFunctionValueIncreases" 64257 "Float" 64256 "ValveFullyOpened_Retract" 32128 "Block" 0 "ValveFullyOpened_Extend" ;
VAL_ 2619670270 FlowRequest_AV06 64511 "ReadyToControl" 64509 "ReleasedControlRequestingOperatorActionBeforeFunctionValueIncreases" 64257 "Float" 64256 "ValveFullyOpened_Retract" 32128 "Block" 0 "ValveFullyOpened_Extend" ;
VAL_ 2619670270 FlowRequest_AV05 64511 "ReadyToControl" 64509 "ReleasedControlRequestingOperatorActionBeforeFunctionValueIncreases" 64257 "Float" 64256 "ValveFullyOpened_Retract" 32128 "Block" 0 "ValveFullyOpened_Extend" ;
VAL_ 2619670270 FlowRequest_AV04 64511 "ReadyToControl" 64509 "ReleasedControlRequestingOperatorActionBeforeFunctionValueIncreases" 64257 "Float" 64256 "ValveFullyOpened_Retract" 32128 "Block" 0 "ValveFullyOpened_Extend" ;
VAL_ 2619670270 FlowRequest_AV03 64511 "ReadyToControl" 64509 "ReleasedControlRequestingOperatorActionBeforeFunctionValueIncreases" 64257 "Float" 64256 "ValveFullyOpened_Retract" 32128 "Block" 0 "ValveFullyOpened_Extend" ;
VAL_ 2619670270 FlowRequest_AV02 64511 "ReadyToControl" 64509 "ReleasedControlRequestingOperatorActionBeforeFunctionValueIncreases" 64257 "Float" 64256 "ValveFullyOpened_Retract" 32128 "Block" 0 "ValveFullyOpened_Extend" ;
VAL_ 2619670270 RearHitchPosRequest 10000 "FullRaise" 64259 "RaiseUntilStopRequest" 64258 "LowerUntilStopRequest" 0 "FullLower" 64511 "ReadyToControl" 64509 "ReleaseControlRequestingOperatorAction" 64257 "Stop" 64256 "Float" ;
VAL_ 2619670270 RearPTOSpeedRequest 64511 "ReadyToControl" 64509 "RequestingOperatorAction" 64256 "On_SpeedClockwiseSetByTimServer" 32128 "Off" 0 "On_SpeedCounterClockwiseSetByTimServer" ;
VAL_ 2619670270 CurvatureRequest 64511 "ReadyToControl" 64509 "RequestingOperatorAwareness" 32128 "Straight" ;
VAL_ 2619670270 VehicleSpeedRequest 64511 "ReadyToControl" 64510 "AcceptFunctionWithoutOperatorAwareness" 64509 "RequestingOperatorAwareness" 64256 "ForwardSpeedSetByTimServer" 32128 "Stop" 0 "ReverseSpeedSetByTimServer" ;
VAL_ 2619670270 FrontHitchPosRequest 10000 "FullRaise" 64259 "RaiseUntilStopRequest" 64258 "LowerUntilStopRequest" 0 "FullLower" 64511 "ReadyToControl" 64509 "ReleaseControlRequestingOperatorAction" 64257 "Stop" 64256 "Float" ;
VAL_ 2619670270 FrontPTOSpeedRequest 64511 "ReadyToControl" 64509 "RequestingOperatorAction" 64256 "On_SpeedClockwiseSetByTimServer" 32128 "Off" 0 "On_SpeedCounterClockwiseSetByTimServer" ;
VAL_ 2619670270 FlowRequest_AV01 65535 "NotAvailable" 65534 "Error" 64511 "ReadyToControl" 64509 "ReleasedControlRequestingOperatorActionBeforeFunctionValueIncreases" 64257 "Float" 64256 "ValveFullyOpened_Retract" 32128 "Block" 0 "ValveFullyOpened_Extend" ;
VAL_ 2619670270 TIMClientState 13 "AutomationFault" 5 "AutomationActive" 15 "NotAvailable" 14 "Error" 3 "AutomationEnabled" 2 "AutomationReadyToEnable" 1 "AutomationNotReady" 0 "AutomationUnavailable" ;
VAL_ 2619670270 ClientHeartbeatCounter 255 "GracefulShutdown" 254 "ErrorConditionOnSender" 251 "ResetOfHeartbeatCounter" ;
VAL_ 2619670270 TIMFunctionId_4 72 "RearTopLinkage" 71 "FrontTopLinkage" 32 "AuxValve32" 70 "ExternalGuidance" 68 "VehicleSpeed" 67 "RearHitch" 66 "FrontHitch" 65 "RearPTO" 64 "FrontPTO" 31 "AuxValve31" 30 "AuxValve30" 29 "AuxValve29" 28 "AuxValve28" 27 "AuxValve27" 26 "AuxValve26" 25 "AuxValve25" 24 "AuxValve24" 23 "AuxValve23" 22 "AuxValve22" 21 "AuxValve21" 20 "AuxValve20" 19 "AuxValve19" 18 "AuxValve18" 17 "AuxValve17" 16 "AuxValve16" 15 "AuxValve15" 14 "AuxValve14" 13 "AuxValve13" 12 "AuxValve12" 11 "AuxValve11" 10 "AuxValve10" 9 "AuxValve9" 8 "AuxValve8" 7 "AuxValve7" 6 "AuxValve6" 5 "AuxValve5" 4 "AuxValve4" 3 "AuxValve3" 2 "AuxValve2" 1 "AuxValve1" ;
VAL_ 2619670270 TIMFunctionId_3 72 "RearTopLinkage" 71 "FrontTopLinkage" 32 "AuxValve32" 70 "ExternalGuidance" 68 "VehicleSpeed" 67 "RearHitch" 66 "FrontHitch" 65 "RearPTO" 64 "FrontPTO" 31 "AuxValve31" 30 "AuxValve30" 29 "AuxValve29" 28 "AuxValve28" 27 "AuxValve27" 26 "AuxValve26" 25 "AuxValve25" 24 "AuxValve24" 23 "AuxValve23" 22 "AuxValve22" 21 "AuxValve21" 20 "AuxValve20" 19 "AuxValve19" 18 "AuxValve18" 17 "AuxValve17" 16 "AuxValve16" 15 "AuxValve15" 14 "AuxValve14" 13 "AuxValve13" 12 "AuxValve12" 11 "AuxValve11" 10 "AuxValve10" 9 "AuxValve9" 8 "AuxValve8" 7 "AuxValve7" 6 "AuxValve6" 5 "AuxValve5" 4 "AuxValve4" 3 "AuxValve3" 2 "AuxValve2" 1 "AuxValve1" ;
VAL_ 2619670270 TIMFunctionId_2 72 "RearTopLinkage" 71 "FrontTopLinkage" 32 "AuxValve32" 70 "ExternalGuidance" 68 "VehicleSpeed" 67 "RearHitch" 66 "FrontHitch" 65 "RearPTO" 64 "FrontPTO" 31 "AuxValve31" 30 "AuxValve30" 29 "AuxValve29" 28 "AuxValve28" 27 "AuxValve27" 26 "AuxValve26" 25 "AuxValve25" 24 "AuxValve24" 23 "AuxValve23" 22 "AuxValve22" 21 "AuxValve21" 20 "AuxValve20" 19 "AuxValve19" 18 "AuxValve18" 17 "AuxValve17" 16 "AuxValve16" 15 "AuxValve15" 14 "AuxValve14" 13 "AuxValve13" 12 "AuxValve12" 11 "AuxValve11" 10 "AuxValve10" 9 "AuxValve9" 8 "AuxValve8" 7 "AuxValve7" 6 "AuxValve6" 5 "AuxValve5" 4 "AuxValve4" 3 "AuxValve3" 2 "AuxValve2" 1 "AuxValve1" ;
VAL_ 2619670270 TIMFunctionId_1 72 "RearTopLinkage" 71 "FrontTopLinkage" 32 "AuxValve32" 70 "ExternalGuidance" 68 "VehicleSpeed" 67 "RearHitch" 66 "FrontHitch" 65 "RearPTO" 64 "FrontPTO" 31 "AuxValve31" 30 "AuxValve30" 29 "AuxValve29" 28 "AuxValve28" 27 "AuxValve27" 26 "AuxValve26" 25 "AuxValve25" 24 "AuxValve24" 23 "AuxValve23" 22 "AuxValve22" 21 "AuxValve21" 20 "AuxValve20" 19 "AuxValve19" 18 "AuxValve18" 17 "AuxValve17" 16 "AuxValve16" 15 "AuxValve15" 14 "AuxValve14" 13 "AuxValve13" 12 "AuxValve12" 11 "AuxValve11" 10 "AuxValve10" 9 "AuxValve9" 8 "AuxValve8" 7 "AuxValve7" 6 "AuxValve6" 5 "AuxValve5" 4 "AuxValve4" 3 "AuxValve3" 2 "AuxValve2" 1 "AuxValve1" ;
VAL_ 2619670270 RequestType_4 7 "DontCare" 6 "Error" 1 "AssignToRequestingClient" 0 "ReleaseAssignmentOfRequestingClient" ;
VAL_ 2619670270 RequestType_3 7 "DontCare" 6 "Error" 1 "AssignToRequestingClient" 0 "ReleaseAssignmentOfRequestingClient" ;
VAL_ 2619670270 RequestType_2 7 "DontCare" 6 "Error" 1 "AssignToRequestingClient" 0 "ReleaseAssignmentOfRequestingClient" ;
VAL_ 2619670270 RequestType_1 7 "DontCare" 6 "Error" 1 "AssignToRequestingClient" 0 "ReleaseAssignmentOfRequestingClient" ;
VAL_ 2619670270 TIMMessageType 1 "TIMFunctionStatus" 0 "TIMFunctionRequest" ;
VAL_ 2619670270 GroupFunctionValue 32 "TIM_AuxValve32Request" 249 "ClientStatus" 248 "ServerVersionRequest" 247 "ClientVersionResponse" 246 "ConnectionVersionRequest" 245 "FunctionsAssignmentRequest" 244 "FunctionsSupportRequest" 243 "FunctionsAssignmentStatusRequest" 70 "ExternalGuidanceRequest" 68 "VehicleSpeedRequest" 67 "RearHitchRequest" 66 "FrontHitchRequest" 65 "RearPTORequest" 64 "FrontPTORequest" 31 "TIM_AuxValve31Request" 30 "TIM_AuxValve30Request" 29 "TIM_AuxValve29Request" 28 "TIM_AuxValve28Request" 27 "TIM_AuxValve27Request" 26 "TIM_AuxValve26Request" 25 "TIM_AuxValve25Request" 24 "TIM_AuxValve24Request" 23 "TIM_AuxValve23Request" 22 "TIM_AuxValve22Request" 21 "TIM_AuxValve21Request" 20 "TIM_AuxValve20Request" 19 "TIM_AuxValve19Request" 18 "TIM_AuxValve18Request" 17 "TIM_AuxValve17Request" 16 "TIM_AuxValve16Request" 15 "TIM_AuxValve15Request" 14 "TIM_AuxValve14Request" 13 "TIM_AuxValve13Request" 12 "TIM_AuxValve12Request" 11 "TIM_AuxValve11Request" 10 "TIM_AuxValve10Request" 9 "TIM_AuxValve9Request" 8 "TIM_AuxValve8Request" 7 "TIM_AuxValve7Request" 6 "TIM_AuxValve6Request" 5 "TIM_AuxValve5Request" 4 "TIM_AuxValve4Request" 3 "TIM_AuxValve3Request" 2 "TIM_AuxValve2Request" 1 "TIM_AuxValve1Request" ;
VAL_ 2619604734 GroupFunctionValue 32 "TIM_AuxValve32Status" 243 "FunctionsAssignmentStatusResponse" 250 "ServerStatus" 248 "ServerVersionResponse" 247 "ClientVersionRequest" 246 "ConnectionVersionResponse" 245 "FunctionsAssignmentResponse" 244 "FunctionsSupportResponse" 70 "ExternalGuidanceStatus" 68 "VehicleSpeedStatus" 67 "RearHitchStatus" 66 "FrontHitchStatus" 65 "RearPTOStatus" 64 "FrontPTOStatus" 31 "TIM_AuxValve31Status" 30 "TIM_AuxValve30Status" 29 "TIM_AuxValve29Status" 28 "TIM_AuxValve28Status" 27 "TIM_AuxValve27Status" 26 "TIM_AuxValve26Status" 25 "TIM_AuxValve25Status" 24 "TIM_AuxValve24Status" 23 "TIM_AuxValve23Status" 22 "TIM_AuxValve22Status" 21 "TIM_AuxValve21Status" 20 "TIM_AuxValve20Status" 19 "TIM_AuxValve19Status" 18 "TIM_AuxValve18Status" 17 "TIM_AuxValve17Status" 16 "TIM_AuxValve16Status" 15 "TIM_AuxValve15Status" 14 "TIM_AuxValve14Status" 13 "TIM_AuxValve13Status" 12 "TIM_AuxValve12Status" 11 "TIM_AuxValve11Status" 10 "TIM_AuxValve10Status" 9 "TIM_AuxValve9Status" 8 "TIM_AuxValve8Status" 7 "TIM_AuxValve7Status" 6 "TIM_AuxValve6Status" 5 "TIM_AuxValve5Status" 4 "TIM_AuxValve4Status" 3 "TIM_AuxValve3Status" 2 "TIM_AuxValve2Status" 1 "TIM_AuxValve1Status" ;
VAL_ 2619604734 RearHitchPosition 65535 "NotAvailable" 65534 "Error" 64259 "Raising" 64258 "Lowering" 64257 "Stop" 10000 "FullRaise" 0 "FullLower" 64256 "Float" ;
VAL_ 2619604734 RearPTOSpeed 65535 "NotAvailable" 65534 "Error" ;
VAL_ 2619604734 FlowAuxValve32 65535 "NotAvailable" 65534 "Error" 64257 "Float" 64256 "ValveFullyOpened_Retract" 32128 "NoFlow_Block" 0 "ValveFullyOpened_Extend" ;
VAL_ 2619604734 FlowAuxValve31 65535 "NotAvailable" 65534 "Error" 64257 "Float" 64256 "ValveFullyOpened_Retract" 32128 "NoFlow_Block" 0 "ValveFullyOpened_Extend" ;
VAL_ 2619604734 FlowAuxValve30 65535 "NotAvailable" 65534 "Error" 64257 "Float" 64256 "ValveFullyOpened_Retract" 32128 "NoFlow_Block" 0 "ValveFullyOpened_Extend" ;
VAL_ 2619604734 FlowAuxValve29 65535 "NotAvailable" 65534 "Error" 64257 "Float" 64256 "ValveFullyOpened_Retract" 32128 "NoFlow_Block" 0 "ValveFullyOpened_Extend" ;
VAL_ 2619604734 FlowAuxValve28 65535 "NotAvailable" 65534 "Error" 64257 "Float" 64256 "ValveFullyOpened_Retract" 32128 "NoFlow_Block" 0 "ValveFullyOpened_Extend" ;
VAL_ 2619604734 FlowAuxValve27 65535 "NotAvailable" 65534 "Error" 64257 "Float" 64256 "ValveFullyOpened_Retract" 32128 "NoFlow_Block" 0 "ValveFullyOpened_Extend" ;
VAL_ 2619604734 FlowAuxValve26 65535 "NotAvailable" 65534 "Error" 64257 "Float" 64256 "ValveFullyOpened_Retract" 32128 "NoFlow_Block" 0 "ValveFullyOpened_Extend" ;
VAL_ 2619604734 FlowAuxValve25 65535 "NotAvailable" 65534 "Error" 64257 "Float" 64256 "ValveFullyOpened_Retract" 32128 "NoFlow_Block" 0 "ValveFullyOpened_Extend" ;
VAL_ 2619604734 FlowAuxValve24 65535 "NotAvailable" 65534 "Error" 64257 "Float" 64256 "ValveFullyOpened_Retract" 32128 "NoFlow_Block" 0 "ValveFullyOpened_Extend" ;
VAL_ 2619604734 FlowAuxValve23 65535 "NotAvailable" 65534 "Error" 64257 "Float" 64256 "ValveFullyOpened_Retract" 32128 "NoFlow_Block" 0 "ValveFullyOpened_Extend" ;
VAL_ 2619604734 FlowAuxValve22 65535 "NotAvailable" 65534 "Error" 64257 "Float" 64256 "ValveFullyOpened_Retract" 32128 "NoFlow_Block" 0 "ValveFullyOpened_Extend" ;
VAL_ 2619604734 FlowAuxValve21 65535 "NotAvailable" 65534 "Error" 64257 "Float" 64256 "ValveFullyOpened_Retract" 32128 "NoFlow_Block" 0 "ValveFullyOpened_Extend" ;
VAL_ 2619604734 FlowAuxValve20 65535 "NotAvailable" 65534 "Error" 64257 "Float" 64256 "ValveFullyOpened_Retract" 32128 "NoFlow_Block" 0 "ValveFullyOpened_Extend" ;
VAL_ 2619604734 FlowAuxValve19 65535 "NotAvailable" 65534 "Error" 64257 "Float" 64256 "ValveFullyOpened_Retract" 32128 "NoFlow_Block" 0 "ValveFullyOpened_Extend" ;
VAL_ 2619604734 FlowAuxValve18 65535 "NotAvailable" 65534 "Error" 64257 "Float" 64256 "ValveFullyOpened_Retract" 32128 "NoFlow_Block" 0 "ValveFullyOpened_Extend" ;
VAL_ 2619604734 FlowAuxValve17 65535 "NotAvailable" 65534 "Error" 64257 "Float" 64256 "ValveFullyOpened_Retract" 32128 "NoFlow_Block" 0 "ValveFullyOpened_Extend" ;
VAL_ 2619604734 FlowAuxValve16 65535 "NotAvailable" 65534 "Error" 64257 "Float" 64256 "ValveFullyOpened_Retract" 32128 "NoFlow_Block" 0 "ValveFullyOpened_Extend" ;
VAL_ 2619604734 FlowAuxValve15 65535 "NotAvailable" 65534 "Error" 64257 "Float" 64256 "ValveFullyOpened_Retract" 32128 "NoFlow_Block" 0 "ValveFullyOpened_Extend" ;
VAL_ 2619604734 FlowAuxValve14 65535 "NotAvailable" 65534 "Error" 64257 "Float" 64256 "ValveFullyOpened_Retract" 32128 "NoFlow_Block" 0 "ValveFullyOpened_Extend" ;
VAL_ 2619604734 FlowAuxValve13 65535 "NotAvailable" 65534 "Error" 64257 "Float" 64256 "ValveFullyOpened_Retract" 32128 "NoFlow_Block" 0 "ValveFullyOpened_Extend" ;
VAL_ 2619604734 FlowAuxValve12 65535 "NotAvailable" 65534 "Error" 64257 "Float" 64256 "ValveFullyOpened_Retract" 32128 "NoFlow_Block" 0 "ValveFullyOpened_Extend" ;
VAL_ 2619604734 FlowAuxValve11 65535 "NotAvailable" 65534 "Error" 64257 "Float" 64256 "ValveFullyOpened_Retract" 32128 "NoFlow_Block" 0 "ValveFullyOpened_Extend" ;
VAL_ 2619604734 FlowAuxValve10 65535 "NotAvailable" 65534 "Error" 64257 "Float" 64256 "ValveFullyOpened_Retract" 32128 "NoFlow_Block" 0 "ValveFullyOpened_Extend" ;
VAL_ 2619604734 FlowAuxValve09 65535 "NotAvailable" 65534 "Error" 64257 "Float" 64256 "ValveFullyOpened_Retract" 32128 "NoFlow_Block" 0 "ValveFullyOpened_Extend" ;
VAL_ 2619604734 FlowAuxValve08 65535 "NotAvailable" 65534 "Error" 64257 "Float" 64256 "ValveFullyOpened_Retract" 32128 "NoFlow_Block" 0 "ValveFullyOpened_Extend" ;
VAL_ 2619604734 FlowAuxValve07 65535 "NotAvailable" 65534 "Error" 64257 "Float" 64256 "ValveFullyOpened_Retract" 32128 "NoFlow_Block" 0 "ValveFullyOpened_Extend" ;
VAL_ 2619604734 FlowAuxValve06 65535 "NotAvailable" 65534 "Error" 64257 "Float" 64256 "ValveFullyOpened_Retract" 32128 "NoFlow_Block" 0 "ValveFullyOpened_Extend" ;
VAL_ 2619604734 FlowAuxValve05 65535 "NotAvailable" 65534 "Error" 64257 "Float" 64256 "ValveFullyOpened_Retract" 32128 "NoFlow_Block" 0 "ValveFullyOpened_Extend" ;
VAL_ 2619604734 FlowAuxValve04 65535 "NotAvailable" 65534 "Error" 64257 "Float" 64256 "ValveFullyOpened_Retract" 32128 "NoFlow_Block" 0 "ValveFullyOpened_Extend" ;
VAL_ 2619604734 FlowAuxValve03 65535 "NotAvailable" 65534 "Error" 64257 "Float" 64256 "ValveFullyOpened_Retract" 32128 "NoFlow_Block" 0 "ValveFullyOpened_Extend" ;
VAL_ 2619604734 FlowAuxValve02 65535 "NotAvailable" 65534 "Error" 64257 "Float" 64256 "ValveFullyOpened_Retract" 32128 "NoFlow_Block" 0 "ValveFullyOpened_Extend" ;
VAL_ 2619604734 FlowTypeAuxValve32 3 "NotAvailable" 2 "Error" 1 "Measured" 0 "Estimated" ;
VAL_ 2619604734 FlowTypeAuxValve31 3 "NotAvailable" 2 "Error" 1 "Measured" 0 "Estimated" ;
VAL_ 2619604734 FlowTypeAuxValve30 3 "NotAvailable" 2 "Error" 1 "Measured" 0 "Estimated" ;
VAL_ 2619604734 FlowTypeAuxValve29 3 "NotAvailable" 2 "Error" 1 "Measured" 0 "Estimated" ;
VAL_ 2619604734 FlowTypeAuxValve28 3 "NotAvailable" 2 "Error" 1 "Measured" 0 "Estimated" ;
VAL_ 2619604734 FlowTypeAuxValve27 3 "NotAvailable" 2 "Error" 1 "Measured" 0 "Estimated" ;
VAL_ 2619604734 FlowTypeAuxValve26 3 "NotAvailable" 2 "Error" 1 "Measured" 0 "Estimated" ;
VAL_ 2619604734 FlowTypeAuxValve25 3 "NotAvailable" 2 "Error" 1 "Measured" 0 "Estimated" ;
VAL_ 2619604734 FlowTypeAuxValve24 3 "NotAvailable" 2 "Error" 1 "Measured" 0 "Estimated" ;
VAL_ 2619604734 FlowTypeAuxValve23 3 "NotAvailable" 2 "Error" 1 "Measured" 0 "Estimated" ;
VAL_ 2619604734 FlowTypeAuxValve22 3 "NotAvailable" 2 "Error" 1 "Measured" 0 "Estimated" ;
VAL_ 2619604734 FlowTypeAuxValve21 3 "NotAvailable" 2 "Error" 1 "Measured" 0 "Estimated" ;
VAL_ 2619604734 FlowTypeAuxValve20 3 "NotAvailable" 2 "Error" 1 "Measured" 0 "Estimated" ;
VAL_ 2619604734 FlowTypeAuxValve19 3 "NotAvailable" 2 "Error" 1 "Measured" 0 "Estimated" ;
VAL_ 2619604734 FlowTypeAuxValve18 3 "NotAvailable" 2 "Error" 1 "Measured" 0 "Estimated" ;
VAL_ 2619604734 FlowTypeAuxValve17 3 "NotAvailable" 2 "Error" 1 "Measured" 0 "Estimated" ;
VAL_ 2619604734 FlowTypeAuxValve16 3 "NotAvailable" 2 "Error" 1 "Measured" 0 "Estimated" ;
VAL_ 2619604734 FlowTypeAuxValve15 3 "NotAvailable" 2 "Error" 1 "Measured" 0 "Estimated" ;
VAL_ 2619604734 FlowTypeAuxValve14 3 "NotAvailable" 2 "Error" 1 "Measured" 0 "Estimated" ;
VAL_ 2619604734 FlowTypeAuxValve13 3 "NotAvailable" 2 "Error" 1 "Measured" 0 "Estimated" ;
VAL_ 2619604734 FlowTypeAuxValve12 3 "NotAvailable" 2 "Error" 1 "Measured" 0 "Estimated" ;
VAL_ 2619604734 FlowTypeAuxValve11 3 "NotAvailable" 2 "Error" 1 "Measured" 0 "Estimated" ;
VAL_ 2619604734 FlowTypeAuxValve10 3 "NotAvailable" 2 "Error" 1 "Measured" 0 "Estimated" ;
VAL_ 2619604734 FlowTypeAuxValve09 3 "NotAvailable" 2 "Error" 1 "Measured" 0 "Estimated" ;
VAL_ 2619604734 FlowTypeAuxValve08 3 "NotAvailable" 2 "Error" 1 "Measured" 0 "Estimated" ;
VAL_ 2619604734 FlowTypeAuxValve07 3 "NotAvailable" 2 "Error" 1 "Measured" 0 "Estimated" ;
VAL_ 2619604734 FlowTypeAuxValve06 3 "NotAvailable" 2 "Error" 1 "Measured" 0 "Estimated" ;
VAL_ 2619604734 FlowTypeAuxValve05 3 "NotAvailable" 2 "Error" 1 "Measured" 0 "Estimated" ;
VAL_ 2619604734 FlowTypeAuxValve04 3 "NotAvailable" 2 "Error" 1 "Measured" 0 "Estimated" ;
VAL_ 2619604734 FlowTypeAuxValve03 3 "NotAvailable" 2 "Error" 1 "Measured" 0 "Estimated" ;
VAL_ 2619604734 FlowTypeAuxValve02 3 "NotAvailable" 2 "Error" 1 "Measured" 0 "Estimated" ;
VAL_ 2619604734 FlowTypeAuxValve01 3 "NotAvailable" 2 "Error" 1 "Measured" 0 "Estimated" ;
VAL_ 2619604734 ExitReasonCodeRearPTO 31 "NotAvailable" 30 "Error" 15 "InvalidPtoGear" 9 "FunctionFault" 8 "OperatorControlFault" 5 "RemoteCommandTimeout" 4 "OperatorControlNotInValidPosition" 3 "OperatorOverrideOfFunction" 2 "ImplementReleasedControlOfFunction" 7 "FunctionNotCalibrated" 6 "RemoteCommandOutOfRange_Invalid" 1 "RequiredLevelOfOperatorPresence_AwarenessNotDetected" 0 "NoReason_AllClear" ;
VAL_ 2619604734 ExitReasonCodeRearHitch 16 "HitchLockedOut" 31 "NotAvailable" 30 "Error" 15 "HydraulicOilLevelLow" 9 "FunctionFault" 8 "OperatorControlFault" 5 "RemoteCommandTimeout" 4 "OperatorControlNotInValidPosition" 3 "OperatorOverrideOfFunction" 2 "ImplementReleasedControlOfFunction" 7 "FunctionNotCalibrated" 6 "RemoteCommandOutOfRangeOrInvalid" 1 "RequiredLevelOfOperatorPresence_AwarenessNotDetected" 0 "NoReason_AllClear" ;
VAL_ 2619604734 ExitReasonCodeAuxValve32 31 "NotAvailable" 30 "Error" 16 "ValveLockedOut_TransportLock" 15 "HydraulicOilLevelLow" 9 "FunctionFault" 8 "OperatorControlFault" 5 "RemoteCommandTimeout" 4 "OperatorControlNotInValidPosition" 3 "OperatorOverrideOfFunction" 2 "ImplementReleasedControlOfFunction" 7 "FunctionNotCalibrated" 6 "RemoteCommandOutOfRange_Invalid" 1 "RequiredLevelOfOperatorPresence_AwarenessNotDetected" 0 "NoReason_AllClear" ;
VAL_ 2619604734 ExitReasonCodeAuxValve31 31 "NotAvailable" 30 "Error" 16 "ValveLockedOut_TransportLock" 15 "HydraulicOilLevelLow" 9 "FunctionFault" 8 "OperatorControlFault" 5 "RemoteCommandTimeout" 4 "OperatorControlNotInValidPosition" 3 "OperatorOverrideOfFunction" 2 "ImplementReleasedControlOfFunction" 7 "FunctionNotCalibrated" 6 "RemoteCommandOutOfRange_Invalid" 1 "RequiredLevelOfOperatorPresence_AwarenessNotDetected" 0 "NoReason_AllClear" ;
VAL_ 2619604734 ExitReasonCodeAuxValve30 31 "NotAvailable" 30 "Error" 16 "ValveLockedOut_TransportLock" 15 "HydraulicOilLevelLow" 9 "FunctionFault" 8 "OperatorControlFault" 5 "RemoteCommandTimeout" 4 "OperatorControlNotInValidPosition" 3 "OperatorOverrideOfFunction" 2 "ImplementReleasedControlOfFunction" 7 "FunctionNotCalibrated" 6 "RemoteCommandOutOfRange_Invalid" 1 "RequiredLevelOfOperatorPresence_AwarenessNotDetected" 0 "NoReason_AllClear" ;
VAL_ 2619604734 ExitReasonCodeAuxValve29 31 "NotAvailable" 30 "Error" 16 "ValveLockedOut_TransportLock" 15 "HydraulicOilLevelLow" 9 "FunctionFault" 8 "OperatorControlFault" 5 "RemoteCommandTimeout" 4 "OperatorControlNotInValidPosition" 3 "OperatorOverrideOfFunction" 2 "ImplementReleasedControlOfFunction" 7 "FunctionNotCalibrated" 6 "RemoteCommandOutOfRange_Invalid" 1 "RequiredLevelOfOperatorPresence_AwarenessNotDetected" 0 "NoReason_AllClear" ;
VAL_ 2619604734 ExitReasonCodeAuxValve28 31 "NotAvailable" 30 "Error" 16 "ValveLockedOut_TransportLock" 15 "HydraulicOilLevelLow" 9 "FunctionFault" 8 "OperatorControlFault" 5 "RemoteCommandTimeout" 4 "OperatorControlNotInValidPosition" 3 "OperatorOverrideOfFunction" 2 "ImplementReleasedControlOfFunction" 7 "FunctionNotCalibrated" 6 "RemoteCommandOutOfRange_Invalid" 1 "RequiredLevelOfOperatorPresence_AwarenessNotDetected" 0 "NoReason_AllClear" ;
VAL_ 2619604734 ExitReasonCodeAuxValve27 31 "NotAvailable" 30 "Error" 16 "ValveLockedOut_TransportLock" 15 "HydraulicOilLevelLow" 9 "FunctionFault" 8 "OperatorControlFault" 5 "RemoteCommandTimeout" 4 "OperatorControlNotInValidPosition" 3 "OperatorOverrideOfFunction" 2 "ImplementReleasedControlOfFunction" 7 "FunctionNotCalibrated" 6 "RemoteCommandOutOfRange_Invalid" 1 "RequiredLevelOfOperatorPresence_AwarenessNotDetected" 0 "NoReason_AllClear" ;
VAL_ 2619604734 ExitReasonCodeAuxValve26 31 "NotAvailable" 30 "Error" 16 "ValveLockedOut_TransportLock" 15 "HydraulicOilLevelLow" 9 "FunctionFault" 8 "OperatorControlFault" 5 "RemoteCommandTimeout" 4 "OperatorControlNotInValidPosition" 3 "OperatorOverrideOfFunction" 2 "ImplementReleasedControlOfFunction" 7 "FunctionNotCalibrated" 6 "RemoteCommandOutOfRange_Invalid" 1 "RequiredLevelOfOperatorPresence_AwarenessNotDetected" 0 "NoReason_AllClear" ;
VAL_ 2619604734 ExitReasonCodeAuxValve25 31 "NotAvailable" 30 "Error" 16 "ValveLockedOut_TransportLock" 15 "HydraulicOilLevelLow" 9 "FunctionFault" 8 "OperatorControlFault" 5 "RemoteCommandTimeout" 4 "OperatorControlNotInValidPosition" 3 "OperatorOverrideOfFunction" 2 "ImplementReleasedControlOfFunction" 7 "FunctionNotCalibrated" 6 "RemoteCommandOutOfRange_Invalid" 1 "RequiredLevelOfOperatorPresence_AwarenessNotDetected" 0 "NoReason_AllClear" ;
VAL_ 2619604734 ExitReasonCodeAuxValve24 31 "NotAvailable" 30 "Error" 16 "ValveLockedOut_TransportLock" 15 "HydraulicOilLevelLow" 9 "FunctionFault" 8 "OperatorControlFault" 5 "RemoteCommandTimeout" 4 "OperatorControlNotInValidPosition" 3 "OperatorOverrideOfFunction" 2 "ImplementReleasedControlOfFunction" 7 "FunctionNotCalibrated" 6 "RemoteCommandOutOfRange_Invalid" 1 "RequiredLevelOfOperatorPresence_AwarenessNotDetected" 0 "NoReason_AllClear" ;
VAL_ 2619604734 ExitReasonCodeAuxValve23 31 "NotAvailable" 30 "Error" 16 "ValveLockedOut_TransportLock" 15 "HydraulicOilLevelLow" 9 "FunctionFault" 8 "OperatorControlFault" 5 "RemoteCommandTimeout" 4 "OperatorControlNotInValidPosition" 3 "OperatorOverrideOfFunction" 2 "ImplementReleasedControlOfFunction" 7 "FunctionNotCalibrated" 6 "RemoteCommandOutOfRange_Invalid" 1 "RequiredLevelOfOperatorPresence_AwarenessNotDetected" 0 "NoReason_AllClear" ;
VAL_ 2619604734 ExitReasonCodeAuxValve22 31 "NotAvailable" 30 "Error" 16 "ValveLockedOut_TransportLock" 15 "HydraulicOilLevelLow" 9 "FunctionFault" 8 "OperatorControlFault" 5 "RemoteCommandTimeout" 4 "OperatorControlNotInValidPosition" 3 "OperatorOverrideOfFunction" 2 "ImplementReleasedControlOfFunction" 7 "FunctionNotCalibrated" 6 "RemoteCommandOutOfRange_Invalid" 1 "RequiredLevelOfOperatorPresence_AwarenessNotDetected" 0 "NoReason_AllClear" ;
VAL_ 2619604734 ExitReasonCodeAuxValve21 31 "NotAvailable" 30 "Error" 16 "ValveLockedOut_TransportLock" 15 "HydraulicOilLevelLow" 9 "FunctionFault" 8 "OperatorControlFault" 5 "RemoteCommandTimeout" 4 "OperatorControlNotInValidPosition" 3 "OperatorOverrideOfFunction" 2 "ImplementReleasedControlOfFunction" 7 "FunctionNotCalibrated" 6 "RemoteCommandOutOfRange_Invalid" 1 "RequiredLevelOfOperatorPresence_AwarenessNotDetected" 0 "NoReason_AllClear" ;
VAL_ 2619604734 ExitReasonCodeAuxValve20 31 "NotAvailable" 30 "Error" 16 "ValveLockedOut_TransportLock" 15 "HydraulicOilLevelLow" 9 "FunctionFault" 8 "OperatorControlFault" 5 "RemoteCommandTimeout" 4 "OperatorControlNotInValidPosition" 3 "OperatorOverrideOfFunction" 2 "ImplementReleasedControlOfFunction" 7 "FunctionNotCalibrated" 6 "RemoteCommandOutOfRange_Invalid" 1 "RequiredLevelOfOperatorPresence_AwarenessNotDetected" 0 "NoReason_AllClear" ;
VAL_ 2619604734 ExitReasonCodeAuxValve19 31 "NotAvailable" 30 "Error" 16 "ValveLockedOut_TransportLock" 15 "HydraulicOilLevelLow" 9 "FunctionFault" 8 "OperatorControlFault" 5 "RemoteCommandTimeout" 4 "OperatorControlNotInValidPosition" 3 "OperatorOverrideOfFunction" 2 "ImplementReleasedControlOfFunction" 7 "FunctionNotCalibrated" 6 "RemoteCommandOutOfRange_Invalid" 1 "RequiredLevelOfOperatorPresence_AwarenessNotDetected" 0 "NoReason_AllClear" ;
VAL_ 2619604734 ExitReasonCodeAuxValve18 31 "NotAvailable" 30 "Error" 16 "ValveLockedOut_TransportLock" 15 "HydraulicOilLevelLow" 9 "FunctionFault" 8 "OperatorControlFault" 5 "RemoteCommandTimeout" 4 "OperatorControlNotInValidPosition" 3 "OperatorOverrideOfFunction" 2 "ImplementReleasedControlOfFunction" 7 "FunctionNotCalibrated" 6 "RemoteCommandOutOfRange_Invalid" 1 "RequiredLevelOfOperatorPresence_AwarenessNotDetected" 0 "NoReason_AllClear" ;
VAL_ 2619604734 ExitReasonCodeAuxValve17 31 "NotAvailable" 30 "Error" 16 "ValveLockedOut_TransportLock" 15 "HydraulicOilLevelLow" 9 "FunctionFault" 8 "OperatorControlFault" 5 "RemoteCommandTimeout" 4 "OperatorControlNotInValidPosition" 3 "OperatorOverrideOfFunction" 2 "ImplementReleasedControlOfFunction" 7 "FunctionNotCalibrated" 6 "RemoteCommandOutOfRange_Invalid" 1 "RequiredLevelOfOperatorPresence_AwarenessNotDetected" 0 "NoReason_AllClear" ;
VAL_ 2619604734 ExitReasonCodeAuxValve16 31 "NotAvailable" 30 "Error" 16 "ValveLockedOut_TransportLock" 15 "HydraulicOilLevelLow" 9 "FunctionFault" 8 "OperatorControlFault" 5 "RemoteCommandTimeout" 4 "OperatorControlNotInValidPosition" 3 "OperatorOverrideOfFunction" 2 "ImplementReleasedControlOfFunction" 7 "FunctionNotCalibrated" 6 "RemoteCommandOutOfRange_Invalid" 1 "RequiredLevelOfOperatorPresence_AwarenessNotDetected" 0 "NoReason_AllClear" ;
VAL_ 2619604734 ExitReasonCodeAuxValve15 31 "NotAvailable" 30 "Error" 16 "ValveLockedOut_TransportLock" 15 "HydraulicOilLevelLow" 9 "FunctionFault" 8 "OperatorControlFault" 5 "RemoteCommandTimeout" 4 "OperatorControlNotInValidPosition" 3 "OperatorOverrideOfFunction" 2 "ImplementReleasedControlOfFunction" 7 "FunctionNotCalibrated" 6 "RemoteCommandOutOfRange_Invalid" 1 "RequiredLevelOfOperatorPresence_AwarenessNotDetected" 0 "NoReason_AllClear" ;
VAL_ 2619604734 ExitReasonCodeAuxValve14 31 "NotAvailable" 30 "Error" 16 "ValveLockedOut_TransportLock" 15 "HydraulicOilLevelLow" 9 "FunctionFault" 8 "OperatorControlFault" 5 "RemoteCommandTimeout" 4 "OperatorControlNotInValidPosition" 3 "OperatorOverrideOfFunction" 2 "ImplementReleasedControlOfFunction" 7 "FunctionNotCalibrated" 6 "RemoteCommandOutOfRange_Invalid" 1 "RequiredLevelOfOperatorPresence_AwarenessNotDetected" 0 "NoReason_AllClear" ;
VAL_ 2619604734 ExitReasonCodeAuxValve13 31 "NotAvailable" 30 "Error" 16 "ValveLockedOut_TransportLock" 15 "HydraulicOilLevelLow" 9 "FunctionFault" 8 "OperatorControlFault" 5 "RemoteCommandTimeout" 4 "OperatorControlNotInValidPosition" 3 "OperatorOverrideOfFunction" 2 "ImplementReleasedControlOfFunction" 7 "FunctionNotCalibrated" 6 "RemoteCommandOutOfRange_Invalid" 1 "RequiredLevelOfOperatorPresence_AwarenessNotDetected" 0 "NoReason_AllClear" ;
VAL_ 2619604734 ExitReasonCodeAuxValve12 31 "NotAvailable" 30 "Error" 16 "ValveLockedOut_TransportLock" 15 "HydraulicOilLevelLow" 9 "FunctionFault" 8 "OperatorControlFault" 5 "RemoteCommandTimeout" 4 "OperatorControlNotInValidPosition" 3 "OperatorOverrideOfFunction" 2 "ImplementReleasedControlOfFunction" 7 "FunctionNotCalibrated" 6 "RemoteCommandOutOfRange_Invalid" 1 "RequiredLevelOfOperatorPresence_AwarenessNotDetected" 0 "NoReason_AllClear" ;
VAL_ 2619604734 ExitReasonCodeAuxValve11 31 "NotAvailable" 30 "Error" 16 "ValveLockedOut_TransportLock" 15 "HydraulicOilLevelLow" 9 "FunctionFault" 8 "OperatorControlFault" 5 "RemoteCommandTimeout" 4 "OperatorControlNotInValidPosition" 3 "OperatorOverrideOfFunction" 2 "ImplementReleasedControlOfFunction" 7 "FunctionNotCalibrated" 6 "RemoteCommandOutOfRange_Invalid" 1 "RequiredLevelOfOperatorPresence_AwarenessNotDetected" 0 "NoReason_AllClear" ;
VAL_ 2619604734 ExitReasonCodeAuxValve10 31 "NotAvailable" 30 "Error" 16 "ValveLockedOut_TransportLock" 15 "HydraulicOilLevelLow" 9 "FunctionFault" 8 "OperatorControlFault" 5 "RemoteCommandTimeout" 4 "OperatorControlNotInValidPosition" 3 "OperatorOverrideOfFunction" 2 "ImplementReleasedControlOfFunction" 7 "FunctionNotCalibrated" 6 "RemoteCommandOutOfRange_Invalid" 1 "RequiredLevelOfOperatorPresence_AwarenessNotDetected" 0 "NoReason_AllClear" ;
VAL_ 2619604734 ExitReasonCodeAuxValve09 31 "NotAvailable" 30 "Error" 16 "ValveLockedOut_TransportLock" 15 "HydraulicOilLevelLow" 9 "FunctionFault" 8 "OperatorControlFault" 5 "RemoteCommandTimeout" 4 "OperatorControlNotInValidPosition" 3 "OperatorOverrideOfFunction" 2 "ImplementReleasedControlOfFunction" 7 "FunctionNotCalibrated" 6 "RemoteCommandOutOfRange_Invalid" 1 "RequiredLevelOfOperatorPresence_AwarenessNotDetected" 0 "NoReason_AllClear" ;
VAL_ 2619604734 ExitReasonCodeAuxValve08 31 "NotAvailable" 30 "Error" 16 "ValveLockedOut_TransportLock" 15 "HydraulicOilLevelLow" 9 "FunctionFault" 8 "OperatorControlFault" 5 "RemoteCommandTimeout" 4 "OperatorControlNotInValidPosition" 3 "OperatorOverrideOfFunction" 2 "ImplementReleasedControlOfFunction" 7 "FunctionNotCalibrated" 6 "RemoteCommandOutOfRange_Invalid" 1 "RequiredLevelOfOperatorPresence_AwarenessNotDetected" 0 "NoReason_AllClear" ;
VAL_ 2619604734 ExitReasonCodeAuxValve07 31 "NotAvailable" 30 "Error" 16 "ValveLockedOut_TransportLock" 15 "HydraulicOilLevelLow" 9 "FunctionFault" 8 "OperatorControlFault" 5 "RemoteCommandTimeout" 4 "OperatorControlNotInValidPosition" 3 "OperatorOverrideOfFunction" 2 "ImplementReleasedControlOfFunction" 7 "FunctionNotCalibrated" 6 "RemoteCommandOutOfRange_Invalid" 1 "RequiredLevelOfOperatorPresence_AwarenessNotDetected" 0 "NoReason_AllClear" ;
VAL_ 2619604734 ExitReasonCodeAuxValve06 31 "NotAvailable" 30 "Error" 16 "ValveLockedOut_TransportLock" 15 "HydraulicOilLevelLow" 9 "FunctionFault" 8 "OperatorControlFault" 5 "RemoteCommandTimeout" 4 "OperatorControlNotInValidPosition" 3 "OperatorOverrideOfFunction" 2 "ImplementReleasedControlOfFunction" 7 "FunctionNotCalibrated" 6 "RemoteCommandOutOfRange_Invalid" 1 "RequiredLevelOfOperatorPresence_AwarenessNotDetected" 0 "NoReason_AllClear" ;
VAL_ 2619604734 ExitReasonCodeAuxValve05 31 "NotAvailable" 30 "Error" 16 "ValveLockedOut_TransportLock" 15 "HydraulicOilLevelLow" 9 "FunctionFault" 8 "OperatorControlFault" 5 "RemoteCommandTimeout" 4 "OperatorControlNotInValidPosition" 3 "OperatorOverrideOfFunction" 2 "ImplementReleasedControlOfFunction" 7 "FunctionNotCalibrated" 6 "RemoteCommandOutOfRange_Invalid" 1 "RequiredLevelOfOperatorPresence_AwarenessNotDetected" 0 "NoReason_AllClear" ;
VAL_ 2619604734 ExitReasonCodeAuxValve04 31 "NotAvailable" 30 "Error" 16 "ValveLockedOut_TransportLock" 15 "HydraulicOilLevelLow" 9 "FunctionFault" 8 "OperatorControlFault" 5 "RemoteCommandTimeout" 4 "OperatorControlNotInValidPosition" 3 "OperatorOverrideOfFunction" 2 "ImplementReleasedControlOfFunction" 7 "FunctionNotCalibrated" 6 "RemoteCommandOutOfRange_Invalid" 1 "RequiredLevelOfOperatorPresence_AwarenessNotDetected" 0 "NoReason_AllClear" ;
VAL_ 2619604734 ExitReasonCodeAuxValve03 31 "NotAvailable" 30 "Error" 16 "ValveLockedOut_TransportLock" 15 "HydraulicOilLevelLow" 9 "FunctionFault" 8 "OperatorControlFault" 5 "RemoteCommandTimeout" 4 "OperatorControlNotInValidPosition" 3 "OperatorOverrideOfFunction" 2 "ImplementReleasedControlOfFunction" 7 "FunctionNotCalibrated" 6 "RemoteCommandOutOfRange_Invalid" 1 "RequiredLevelOfOperatorPresence_AwarenessNotDetected" 0 "NoReason_AllClear" ;
VAL_ 2619604734 ExitReasonCodeAuxValve02 31 "NotAvailable" 30 "Error" 16 "ValveLockedOut_TransportLock" 15 "HydraulicOilLevelLow" 9 "FunctionFault" 8 "OperatorControlFault" 5 "RemoteCommandTimeout" 4 "OperatorControlNotInValidPosition" 3 "OperatorOverrideOfFunction" 2 "ImplementReleasedControlOfFunction" 7 "FunctionNotCalibrated" 6 "RemoteCommandOutOfRange_Invalid" 1 "RequiredLevelOfOperatorPresence_AwarenessNotDetected" 0 "NoReason_AllClear" ;
VAL_ 2619604734 AutomationStatusAuxValve04 13 "AutomationFault" 7 "ActiveLimitedLow" 6 "ActiveLimitedHigh" 5 "ActiveNotLimited" 0 "AutomationUnavailable" 1 "AutomationNotReady" 2 "AutomationReadyToEnable" 3 "AutomationEnabled" 4 "AutomationPending" 14 "NonRecoverableFault" 15 "NotAvailable" ;
VAL_ 2619604734 AutomationStatusAuxValve03 13 "AutomationFault" 7 "ActiveLimitedLow" 6 "ActiveLimitedHigh" 5 "ActiveNotLimited" 0 "AutomationUnavailable" 1 "AutomationNotReady" 2 "AutomationReadyToEnable" 3 "AutomationEnabled" 4 "AutomationPending" 14 "NonRecoverableFault" 15 "NotAvailable" ;
VAL_ 2619604734 AutomationStatusAuxValve02 13 "AutomationFault" 7 "ActiveLimitedLow" 6 "ActiveLimitedHigh" 5 "ActiveNotLimited" 0 "AutomationUnavailable" 1 "AutomationNotReady" 2 "AutomationReadyToEnable" 3 "AutomationEnabled" 4 "AutomationPending" 14 "NonRecoverableFault" 15 "NotAvailable" ;
VAL_ 2619604734 AutomationStatusAuxValve01 13 "AutomationFault" 7 "ActiveLimitedLow" 6 "ActiveLimitedHigh" 5 "ActiveNotLimited" 0 "AutomationUnavailable" 1 "AutomationNotReady" 2 "AutomationReadyToEnable" 3 "AutomationEnabled" 4 "AutomationPending" 14 "NonRecoverableFault" 15 "NotAvailable" ;
VAL_ 2619604734 AutomationStatusExternalGuidance 13 "AutomationFault" 7 "ActiveLimitedLow" 6 "ActiveLimitedHigh" 5 "ActiveNotLimited" 0 "AutomationUnavailable" 1 "AutomationNotReady" 2 "AutomationReadyToEnable" 3 "AutomationEnabled" 4 "AutomationPending" 14 "NonRecoverableFault" 15 "NotAvailable" ;
VAL_ 2619604734 AutomationStatusVehicleSpeed 13 "AutomationFault" 7 "ActiveLimitedLow" 6 "ActiveLimitedHigh" 5 "ActiveNotLimited" 0 "AutomationUnavailable" 1 "AutomationNotReady" 2 "AutomationReadyToEnable" 3 "AutomationEnabled" 4 "AutomationPending" 14 "NonRecoverableFault" 15 "NotAvailable" ;
VAL_ 2619604734 AutomationStatusRearHitch 13 "AutomationFault" 7 "ActiveLimitedLow" 6 "ActiveLimitedHigh" 5 "ActiveNotLimited" 0 "AutomationUnavailable" 1 "AutomationNotReady" 2 "AutomationReadyToEnable" 3 "AutomationEnabled" 4 "AutomationPending" 14 "NonRecoverableFault" 15 "NotAvailable" ;
VAL_ 2619604734 AutomationStatusFrontHitch 13 "AutomationFault" 7 "ActiveLimitedLow" 6 "ActiveLimitedHigh" 5 "ActiveNotLimited" 0 "AutomationUnavailable" 1 "AutomationNotReady" 2 "AutomationReadyToEnable" 3 "AutomationEnabled" 4 "AutomationPending" 14 "NonRecoverableFault" 15 "NotAvailable" ;
VAL_ 2619604734 AutomationStatusRearPTO 13 "AutomationFault" 7 "ActiveLimitedLow" 6 "ActiveLimitedHigh" 5 "ActiveNotLimited" 0 "AutomationUnavailable" 1 "AutomationNotReady" 2 "AutomationReadyToEnable" 3 "AutomationEnabled" 4 "AutomationPending" 14 "NonRecoverableFault" 15 "NotAvailable" ;
VAL_ 2619604734 AutomationStatusFrontPTO 13 "AutomationFault" 7 "ActiveLimitedLow" 6 "ActiveLimitedHigh" 5 "ActiveNotLimited" 0 "AutomationUnavailable" 1 "AutomationNotReady" 2 "AutomationReadyToEnable" 3 "AutomationEnabled" 4 "AutomationPending" 14 "NonRecoverableFault" 15 "NotAvailable" ;
VAL_ 2619604734 AutomationStatusAuxValve32 13 "AutomationFault" 7 "ActiveLimitedLow" 6 "ActiveLimitedHigh" 5 "ActiveNotLimited" 0 "AutomationUnavailable" 1 "AutomationNotReady" 2 "AutomationReadyToEnable" 3 "AutomationEnabled" 4 "AutomationPending" 14 "NonRecoverableFault" 15 "NotAvailable" ;
VAL_ 2619604734 AutomationStatusAuxValve31 13 "AutomationFault" 7 "ActiveLimitedLow" 6 "ActiveLimitedHigh" 5 "ActiveNotLimited" 0 "AutomationUnavailable" 1 "AutomationNotReady" 2 "AutomationReadyToEnable" 3 "AutomationEnabled" 4 "AutomationPending" 14 "NonRecoverableFault" 15 "NotAvailable" ;
VAL_ 2619604734 AutomationStatusAuxValve30 13 "AutomationFault" 7 "ActiveLimitedLow" 6 "ActiveLimitedHigh" 5 "ActiveNotLimited" 0 "AutomationUnavailable" 1 "AutomationNotReady" 2 "AutomationReadyToEnable" 3 "AutomationEnabled" 4 "AutomationPending" 14 "NonRecoverableFault" 15 "NotAvailable" ;
VAL_ 2619604734 AutomationStatusAuxValve29 13 "AutomationFault" 7 "ActiveLimitedLow" 6 "ActiveLimitedHigh" 5 "ActiveNotLimited" 0 "AutomationUnavailable" 1 "AutomationNotReady" 2 "AutomationReadyToEnable" 3 "AutomationEnabled" 4 "AutomationPending" 14 "NonRecoverableFault" 15 "NotAvailable" ;
VAL_ 2619604734 AutomationStatusAuxValve28 13 "AutomationFault" 7 "ActiveLimitedLow" 6 "ActiveLimitedHigh" 5 "ActiveNotLimited" 0 "AutomationUnavailable" 1 "AutomationNotReady" 2 "AutomationReadyToEnable" 3 "AutomationEnabled" 4 "AutomationPending" 14 "NonRecoverableFault" 15 "NotAvailable" ;
VAL_ 2619604734 AutomationStatusAuxValve27 13 "AutomationFault" 7 "ActiveLimitedLow" 6 "ActiveLimitedHigh" 5 "ActiveNotLimited" 0 "AutomationUnavailable" 1 "AutomationNotReady" 2 "AutomationReadyToEnable" 3 "AutomationEnabled" 4 "AutomationPending" 14 "NonRecoverableFault" 15 "NotAvailable" ;
VAL_ 2619604734 AutomationStatusAuxValve26 13 "AutomationFault" 7 "ActiveLimitedLow" 6 "ActiveLimitedHigh" 5 "ActiveNotLimited" 0 "AutomationUnavailable" 1 "AutomationNotReady" 2 "AutomationReadyToEnable" 3 "AutomationEnabled" 4 "AutomationPending" 14 "NonRecoverableFault" 15 "NotAvailable" ;
VAL_ 2619604734 AutomationStatusAuxValve25 13 "AutomationFault" 7 "ActiveLimitedLow" 6 "ActiveLimitedHigh" 5 "ActiveNotLimited" 0 "AutomationUnavailable" 1 "AutomationNotReady" 2 "AutomationReadyToEnable" 3 "AutomationEnabled" 4 "AutomationPending" 14 "NonRecoverableFault" 15 "NotAvailable" ;
VAL_ 2619604734 AutomationStatusAuxValve24 13 "AutomationFault" 7 "ActiveLimitedLow" 6 "ActiveLimitedHigh" 5 "ActiveNotLimited" 0 "AutomationUnavailable" 1 "AutomationNotReady" 2 "AutomationReadyToEnable" 3 "AutomationEnabled" 4 "AutomationPending" 14 "NonRecoverableFault" 15 "NotAvailable" ;
VAL_ 2619604734 AutomationStatusAuxValve23 13 "AutomationFault" 7 "ActiveLimitedLow" 6 "ActiveLimitedHigh" 5 "ActiveNotLimited" 0 "AutomationUnavailable" 1 "AutomationNotReady" 2 "AutomationReadyToEnable" 3 "AutomationEnabled" 4 "AutomationPending" 14 "NonRecoverableFault" 15 "NotAvailable" ;
VAL_ 2619604734 AutomationStatusAuxValve22 13 "AutomationFault" 7 "ActiveLimitedLow" 6 "ActiveLimitedHigh" 5 "ActiveNotLimited" 0 "AutomationUnavailable" 1 "AutomationNotReady" 2 "AutomationReadyToEnable" 3 "AutomationEnabled" 4 "AutomationPending" 14 "NonRecoverableFault" 15 "NotAvailable" ;
VAL_ 2619604734 AutomationStatusAuxValve21 13 "AutomationFault" 7 "ActiveLimitedLow" 6 "ActiveLimitedHigh" 5 "ActiveNotLimited" 0 "AutomationUnavailable" 1 "AutomationNotReady" 2 "AutomationReadyToEnable" 3 "AutomationEnabled" 4 "AutomationPending" 14 "NonRecoverableFault" 15 "NotAvailable" ;
VAL_ 2619604734 AutomationStatusAuxValve20 13 "AutomationFault" 7 "ActiveLimitedLow" 6 "ActiveLimitedHigh" 5 "ActiveNotLimited" 0 "AutomationUnavailable" 1 "AutomationNotReady" 2 "AutomationReadyToEnable" 3 "AutomationEnabled" 4 "AutomationPending" 14 "NonRecoverableFault" 15 "NotAvailable" ;
VAL_ 2619604734 AutomationStatusAuxValve19 13 "AutomationFault" 7 "ActiveLimitedLow" 6 "ActiveLimitedHigh" 5 "ActiveNotLimited" 0 "AutomationUnavailable" 1 "AutomationNotReady" 2 "AutomationReadyToEnable" 3 "AutomationEnabled" 4 "AutomationPending" 14 "NonRecoverableFault" 15 "NotAvailable" ;
VAL_ 2619604734 AutomationStatusAuxValve18 13 "AutomationFault" 7 "ActiveLimitedLow" 6 "ActiveLimitedHigh" 5 "ActiveNotLimited" 0 "AutomationUnavailable" 1 "AutomationNotReady" 2 "AutomationReadyToEnable" 3 "AutomationEnabled" 4 "AutomationPending" 14 "NonRecoverableFault" 15 "NotAvailable" ;
VAL_ 2619604734 AutomationStatusAuxValve17 13 "AutomationFault" 7 "ActiveLimitedLow" 6 "ActiveLimitedHigh" 5 "ActiveNotLimited" 0 "AutomationUnavailable" 1 "AutomationNotReady" 2 "AutomationReadyToEnable" 3 "AutomationEnabled" 4 "AutomationPending" 14 "NonRecoverableFault" 15 "NotAvailable" ;
VAL_ 2619604734 AutomationStatusAuxValve16 13 "AutomationFault" 7 "ActiveLimitedLow" 6 "ActiveLimitedHigh" 5 "ActiveNotLimited" 0 "AutomationUnavailable" 1 "AutomationNotReady" 2 "AutomationReadyToEnable" 3 "AutomationEnabled" 4 "AutomationPending" 14 "NonRecoverableFault" 15 "NotAvailable" ;
VAL_ 2619604734 AutomationStatusAuxValve15 13 "AutomationFault" 7 "ActiveLimitedLow" 6 "ActiveLimitedHigh" 5 "ActiveNotLimited" 0 "AutomationUnavailable" 1 "AutomationNotReady" 2 "AutomationReadyToEnable" 3 "AutomationEnabled" 4 "AutomationPending" 14 "NonRecoverableFault" 15 "NotAvailable" ;
VAL_ 2619604734 AutomationStatusAuxValve14 13 "AutomationFault" 7 "ActiveLimitedLow" 6 "ActiveLimitedHigh" 5 "ActiveNotLimited" 0 "AutomationUnavailable" 1 "AutomationNotReady" 2 "AutomationReadyToEnable" 3 "AutomationEnabled" 4 "AutomationPending" 14 "NonRecoverableFault" 15 "NotAvailable" ;
VAL_ 2619604734 AutomationStatusAuxValve13 13 "AutomationFault" 7 "ActiveLimitedLow" 6 "ActiveLimitedHigh" 5 "ActiveNotLimited" 0 "AutomationUnavailable" 1 "AutomationNotReady" 2 "AutomationReadyToEnable" 3 "AutomationEnabled" 4 "AutomationPending" 14 "NonRecoverableFault" 15 "NotAvailable" ;
VAL_ 2619604734 AutomationStatusAuxValve12 13 "AutomationFault" 7 "ActiveLimitedLow" 6 "ActiveLimitedHigh" 5 "ActiveNotLimited" 0 "AutomationUnavailable" 1 "AutomationNotReady" 2 "AutomationReadyToEnable" 3 "AutomationEnabled" 4 "AutomationPending" 14 "NonRecoverableFault" 15 "NotAvailable" ;
VAL_ 2619604734 AutomationStatusAuxValve11 13 "AutomationFault" 7 "ActiveLimitedLow" 6 "ActiveLimitedHigh" 5 "ActiveNotLimited" 0 "AutomationUnavailable" 1 "AutomationNotReady" 2 "AutomationReadyToEnable" 3 "AutomationEnabled" 4 "AutomationPending" 14 "NonRecoverableFault" 15 "NotAvailable" ;
VAL_ 2619604734 AutomationStatusAuxValve10 13 "AutomationFault" 7 "ActiveLimitedLow" 6 "ActiveLimitedHigh" 5 "ActiveNotLimited" 0 "AutomationUnavailable" 1 "AutomationNotReady" 2 "AutomationReadyToEnable" 3 "AutomationEnabled" 4 "AutomationPending" 14 "NonRecoverableFault" 15 "NotAvailable" ;
VAL_ 2619604734 AutomationStatusAuxValve09 13 "AutomationFault" 7 "ActiveLimitedLow" 6 "ActiveLimitedHigh" 5 "ActiveNotLimited" 0 "AutomationUnavailable" 1 "AutomationNotReady" 2 "AutomationReadyToEnable" 3 "AutomationEnabled" 4 "AutomationPending" 14 "NonRecoverableFault" 15 "NotAvailable" ;
VAL_ 2619604734 AutomationStatusAuxValve08 13 "AutomationFault" 7 "ActiveLimitedLow" 6 "ActiveLimitedHigh" 5 "ActiveNotLimited" 0 "AutomationUnavailable" 1 "AutomationNotReady" 2 "AutomationReadyToEnable" 3 "AutomationEnabled" 4 "AutomationPending" 14 "NonRecoverableFault" 15 "NotAvailable" ;
VAL_ 2619604734 AutomationStatusAuxValve07 13 "AutomationFault" 7 "ActiveLimitedLow" 6 "ActiveLimitedHigh" 5 "ActiveNotLimited" 0 "AutomationUnavailable" 1 "AutomationNotReady" 2 "AutomationReadyToEnable" 3 "AutomationEnabled" 4 "AutomationPending" 14 "NonRecoverableFault" 15 "NotAvailable" ;
VAL_ 2619604734 AutomationStatusAuxValve06 13 "AutomationFault" 7 "ActiveLimitedLow" 6 "ActiveLimitedHigh" 5 "ActiveNotLimited" 0 "AutomationUnavailable" 1 "AutomationNotReady" 2 "AutomationReadyToEnable" 3 "AutomationEnabled" 4 "AutomationPending" 14 "NonRecoverableFault" 15 "NotAvailable" ;
VAL_ 2619604734 AutomationStatusAuxValve05 13 "AutomationFault" 7 "ActiveLimitedLow" 6 "ActiveLimitedHigh" 5 "ActiveNotLimited" 0 "AutomationUnavailable" 1 "AutomationNotReady" 2 "AutomationReadyToEnable" 3 "AutomationEnabled" 4 "AutomationPending" 14 "NonRecoverableFault" 15 "NotAvailable" ;
VAL_ 2619604734 Curvature 65535 "NotAvailable" 65534 "Error" 32128 "Straight" ;
VAL_ 2619604734 ExitReasonCodeExternalGuidance 21 "HydraulicOilLevelTooLow" 20 "HydraulicOilTemperatureTooLow" 19 "VehicleTransmissionGearDoesntAllowRemoteCommands" 18 "VehicleSpeedTooLow" 17 "VehicleSpeedTooHigh" 16 "AlternateGuidanceSystemActive" 31 "NotAvailable" 30 "Error" 15 "ControlUnitInDiagnosticMode" 9 "FunctionFault" 8 "OperatorControlFault" 5 "RemoteCommandTimeout" 4 "OperatorControlNotInValidPosition" 3 "OperatorOverrideOfFunction" 2 "ImplementReleasedControlOfFunction" 7 "FunctionNotCalibrated" 6 "RemoteCommandOutOfRangeOrInvalid" 1 "RequiredLevelOfOperatorPresence_AwarenessNotDetected" 0 "NoReason_AllClear" ;
VAL_ 2619604734 VehicleSpeed 65535 "NotAvailable" 65534 "Error" ;
VAL_ 2619604734 ExitReasonCodeVehicleSpeed 31 "NotAvailable" 30 "Error" 15 "VehicleTransmissionGearDoesntAllowRemoteCommands " 9 "FunctionFault" 8 "OperatorControlFault" 5 "RemoteCommandTimeout" 4 "OperatorControlNotInValidPosition" 3 "OperatorOverrideOfFunction" 2 "ImplementReleasedControlOfFunction" 7 "FunctionNotCalibrated" 6 "RemoteCommandOutOfRangeOrInvalid" 1 "RequiredLevelOfOperatorPresence_AwarenessNotDetected" 0 "NoReason_AllClear" ;
VAL_ 2619604734 FrontHitchPosition 65535 "NotAvailable" 65534 "Error" 64259 "Raising" 64258 "Lowering" 64257 "Stop" 10000 "FullRaise" 0 "FullLower" 64256 "Float" ;
VAL_ 2619604734 ExitReasonCodeFrontHitch 16 "HitchLockedOut" 31 "NotAvailable" 30 "Error" 15 "HydraulicOilLevelLow" 9 "FunctionFault" 8 "OperatorControlFault" 5 "RemoteCommandTimeout" 4 "OperatorControlNotInValidPosition" 3 "OperatorOverrideOfFunction" 2 "ImplementReleasedControlOfFunction" 7 "FunctionNotCalibrated" 6 "RemoteCommandOutOfRangeOrInvalid" 1 "RequiredLevelOfOperatorPresence_AwarenessNotDetected" 0 "NoReason_AllClear" ;
VAL_ 2619604734 FrontPTOSpeed 65535 "NotAvailable" 65534 "Error" ;
VAL_ 2619604734 ExitReasonCodeFrontPTO 31 "NotAvailable" 30 "Error" 15 "InvalidPtoGear" 9 "FunctionFault" 8 "OperatorControlFault" 5 "RemoteCommandTimeout" 4 "OperatorControlNotInValidPosition" 3 "OperatorOverrideOfFunction" 2 "ImplementReleasedControlOfFunction" 7 "FunctionNotCalibrated" 6 "RemoteCommandOutOfRange_Invalid" 1 "RequiredLevelOfOperatorPresence_AwarenessNotDetected" 0 "NoReason_AllClear" ;
VAL_ 2619604734 FlowAuxValve01 64257 "Float" 64256 "ValveFullyOpened_Retract" 32128 "NoFlow_Block" 0 "ValveFullyOpened_Extend" ;
VAL_ 2619604734 ReflectedRequestCounter 15 "NotAvailable_DontCare " 14 "Reserved" ;
VAL_ 2619604734 ExitReasonCodeAuxValve01 31 "NotAvailable" 30 "Error" 16 "ValveLockedOut_TransportLock" 15 "HydraulicOilLevelLow" 9 "FunctionFault" 8 "OperatorControlFault" 5 "RemoteCommandTimeout" 4 "OperatorControlNotInValidPosition" 3 "OperatorOverrideOfFunction" 2 "ImplementReleasedControlOfFunction" 7 "FunctionNotCalibrated" 6 "RemoteCommandOutOfRange_Invalid" 1 "RequiredLevelOfOperatorPresence_AwarenessNotDetected" 0 "NoReason_AllClear" ;
VAL_ 2619604734 TIMSystemOperationState 15 "NotAvailable" 14 "Error" 3 "RequirementsStationaryFulfilled" 2 "RequirementsStandstillFulfilled" 1 "RequirementsNormalFulfilled" 0 "RequirementsNotFulfilled" ;
VAL_ 2619604734 TIMServerState 13 "AutomationFault" 5 "AutomationActive" 3 "AutomationEnabled" 15 "NotAvailable" 14 "Error" 1 "AutomationNotReady" 0 "AutomationUnavailable" ;
VAL_ 2619604734 TIMSystemState 15 "NotAvailable" 14 "Error" 5 "AutomationActive" 1 "NoAutomationActive" ;
VAL_ 2619604734 LeadTIMServerIndication 15 "NotAvailable" 14 "Error" 1 "IsLeadAndAutomationAllowed" 0 "IsLeadButAutomationNotAllowed" ;
VAL_ 2619604734 ServerHeartbeatCounter 255 "GracefulShutdown" 254 "ErrorConditionOnSender" 251 "ResetOfHeartbeatCounter" ;
VAL_ 2619604734 AssignmentResult_4 7 "NotAvailable" 6 "Error" 5 "AssignmentNotSuccessful" 1 "IsAssigned" 0 "IsNotAssigned" ;
VAL_ 2619604734 AssignmentResult_3 7 "NotAvailable" 6 "Error" 5 "AssignmentNotSuccessful" 1 "IsAssigned" 0 "IsNotAssigned" ;
VAL_ 2619604734 AssignmentResult_2 7 "NotAvailable" 6 "Error" 5 "AssignmentNotSuccessful" 1 "IsAssigned" 0 "IsNotAssigned" ;
VAL_ 2619604734 AssignmentErrorReason_4 31 "NotAvailable" 30 "AnyOtherError" 8 "ClientNotAuthenticated" 7 "NoMatchingFacility" 6 "ServerBusyWithAssignmentRequest" 5 "ClientNotCertifiedForFunction" 4 "ErrorInRequestMessage" 3 "UnknownRequestType" 2 "FunctionCurrentlyNotAvailable" 1 "FunctionNotSupportedByServer" 0 "AllClearNoReason" ;
VAL_ 2619604734 AssignmentErrorReason_3 31 "NotAvailable" 30 "AnyOtherError" 8 "ClientNotAuthenticated" 7 "NoMatchingFacility" 6 "ServerBusyWithAssignmentRequest" 5 "ClientNotCertifiedForFunction" 4 "ErrorInRequestMessage" 3 "UnknownRequestType" 2 "FunctionCurrentlyNotAvailable" 1 "FunctionNotSupportedByServer" 0 "AllClearNoReason" ;
VAL_ 2619604734 AssignmentErrorReason_2 31 "NotAvailable" 30 "AnyOtherError" 8 "ClientNotAuthenticated" 7 "NoMatchingFacility" 6 "ServerBusyWithAssignmentRequest" 5 "ClientNotCertifiedForFunction" 4 "ErrorInRequestMessage" 3 "UnknownRequestType" 2 "FunctionCurrentlyNotAvailable" 1 "FunctionNotSupportedByServer" 0 "AllClearNoReason" ;
VAL_ 2619604734 AssignmentErrorReason_1 31 "NotAvailable" 30 "AnyOtherError" 8 "ClientNotAuthenticated" 7 "NoMatchingFacility" 6 "ServerBusyWithAssignmentRequest" 5 "ClientNotCertifiedForFunction" 4 "ErrorInRequestMessage" 3 "UnknownRequestType" 2 "FunctionCurrentlyNotAvailable" 1 "FunctionNotSupportedByServer" 0 "AllClearNoReason" ;
VAL_ 2619604734 AssignmentResult_1 7 "NotAvailable" 6 "Error" 5 "AssignmentNotSuccessful" 1 "IsAssigned" 0 "IsNotAssigned" ;
VAL_ 2619604734 TIMFunctionId_4 72 "RearTopLinkage" 71 "FrontTopLinkage" 32 "AuxValve32" 70 "ExternalGuidance" 68 "VehicleSpeed" 67 "RearHitch" 66 "FrontHitch" 65 "RearPTO" 64 "FrontPTO" 31 "AuxValve31" 30 "AuxValve30" 29 "AuxValve29" 28 "AuxValve28" 27 "AuxValve27" 26 "AuxValve26" 25 "AuxValve25" 24 "AuxValve24" 23 "AuxValve23" 22 "AuxValve22" 21 "AuxValve21" 20 "AuxValve20" 19 "AuxValve19" 18 "AuxValve18" 17 "AuxValve17" 16 "AuxValve16" 15 "AuxValve15" 14 "AuxValve14" 13 "AuxValve13" 12 "AuxValve12" 11 "AuxValve11" 10 "AuxValve10" 9 "AuxValve9" 8 "AuxValve8" 7 "AuxValve7" 6 "AuxValve6" 5 "AuxValve5" 4 "AuxValve4" 3 "AuxValve3" 2 "AuxValve2" 1 "AuxValve1" ;
VAL_ 2619604734 TIMFunctionId_3 72 "RearTopLinkage" 71 "FrontTopLinkage" 32 "AuxValve32" 70 "ExternalGuidance" 68 "VehicleSpeed" 67 "RearHitch" 66 "FrontHitch" 65 "RearPTO" 64 "FrontPTO" 31 "AuxValve31" 30 "AuxValve30" 29 "AuxValve29" 28 "AuxValve28" 27 "AuxValve27" 26 "AuxValve26" 25 "AuxValve25" 24 "AuxValve24" 23 "AuxValve23" 22 "AuxValve22" 21 "AuxValve21" 20 "AuxValve20" 19 "AuxValve19" 18 "AuxValve18" 17 "AuxValve17" 16 "AuxValve16" 15 "AuxValve15" 14 "AuxValve14" 13 "AuxValve13" 12 "AuxValve12" 11 "AuxValve11" 10 "AuxValve10" 9 "AuxValve9" 8 "AuxValve8" 7 "AuxValve7" 6 "AuxValve6" 5 "AuxValve5" 4 "AuxValve4" 3 "AuxValve3" 2 "AuxValve2" 1 "AuxValve1" ;
VAL_ 2619604734 TIMFunctionId_2 72 "RearTopLinkage" 71 "FrontTopLinkage" 32 "AuxValve32" 70 "ExternalGuidance" 68 "VehicleSpeed" 67 "RearHitch" 66 "FrontHitch" 65 "RearPTO" 64 "FrontPTO" 31 "AuxValve31" 30 "AuxValve30" 29 "AuxValve29" 28 "AuxValve28" 27 "AuxValve27" 26 "AuxValve26" 25 "AuxValve25" 24 "AuxValve24" 23 "AuxValve23" 22 "AuxValve22" 21 "AuxValve21" 20 "AuxValve20" 19 "AuxValve19" 18 "AuxValve18" 17 "AuxValve17" 16 "AuxValve16" 15 "AuxValve15" 14 "AuxValve14" 13 "AuxValve13" 12 "AuxValve12" 11 "AuxValve11" 10 "AuxValve10" 9 "AuxValve9" 8 "AuxValve8" 7 "AuxValve7" 6 "AuxValve6" 5 "AuxValve5" 4 "AuxValve4" 3 "AuxValve3" 2 "AuxValve2" 1 "AuxValve1" ;
VAL_ 2619604734 TIMFunctionId_1 72 "RearTopLinkage" 71 "FrontTopLinkage" 32 "AuxValve32" 70 "ExternalGuidance" 68 "VehicleSpeed" 67 "RearHitch" 66 "FrontHitch" 65 "RearPTO" 64 "FrontPTO" 31 "AuxValve31" 30 "AuxValve30" 29 "AuxValve29" 28 "AuxValve28" 27 "AuxValve27" 26 "AuxValve26" 25 "AuxValve25" 24 "AuxValve24" 23 "AuxValve23" 22 "AuxValve22" 21 "AuxValve21" 20 "AuxValve20" 19 "AuxValve19" 18 "AuxValve18" 17 "AuxValve17" 16 "AuxValve16" 15 "AuxValve15" 14 "AuxValve14" 13 "AuxValve13" 12 "AuxValve12" 11 "AuxValve11" 10 "AuxValve10" 9 "AuxValve9" 8 "AuxValve8" 7 "AuxValve7" 6 "AuxValve6" 5 "AuxValve5" 4 "AuxValve4" 3 "AuxValve3" 2 "AuxValve2" 1 "AuxValve1" ;
VAL_ 2619604734 TIMConnectionVersion 255 "IncompatibleTIMServerAndClientVersions" ;
VAL_ 2619604734 ErrorCode 1 "IncompatibleTIMServerAndClientVersions" 0 "NoError" ;
VAL_ 2619604734 TIMMessageType 1 "TIMFunctionStatus" 0 "TIMFunctionRequest" ;
VAL_ 2360147710 GuidSysComExitReasonCode 0 "No reason/all clear " 1 "Operator presence not detected" 2 "Implement released control of function " 3 "Operator override of function" 4 "Operator control not in valid position" 5 "Remote command timeout" 6 "Remote command out of range/invalid" 7 "Function not calibrated" 8 "Operator control fault" 9 "Function fault" 20 "Hydraulic oil level too low " 21 "Hydraulic oil temperature too low" 22 "Vehicle transmission gear does not allow remote commands" 23 "Vehicle speed too low " 24 "Vehicle speed too high" 25 "Alternate guidance system active" 26 "Control unit in diagnostic mode" 62 "Error " 63 "Not available (parameter not supported)" ;
VAL_ 2360147710 GuidanceLimitStatus 0 "Not limited" 1 "Operator limited/controlled (request cannot be implemented) " 2 "Limited high (only lower command values result in a change) " 3 "Limited low (only higher command values result in a change)" 4 "Reserved" 5 "Reserved" 6 "Non-recoverable fault " 7 "Not available (parameter not supported) " ;
VAL_ 2360147710 RequestResetCommandStatus 3 "NotAvailable" 2 "Error" 1 "ResetRequired" 0 "ResetNotRequired" ;
VAL_ 2360147710 SteeringInputPositionStatus 3 "NotAvailable" 2 "Error" 1 "CorrectPosition" 0 "NotTheCorrectPosition" ;
VAL_ 2360147710 SteeringSystemReadiness 3 "NotAvailable" 2 "Error" 1 "SystemIsReady" 0 "SystemIsNotReady" ;
VAL_ 2360147710 MechanicalSystemLockout 3 "NotAvailable" 2 "Error" 1 "Active" 0 "NotActive" ;
VAL_ 2360213246 CurvatureCommandStatus 3 "NotAvailable" 2 "Error" 1 "IntendedToSteer" 0 "NotIntendedToSteer" ;
VAL_ 2563047166 FailSaveModeCmd 3 "DoNotCare" 1 "Float" 0 "Block" ;
VAL_ 2563047166 StateCmd 15 "Reserved" 3 "Float" 2 "Retract" 1 "Extend" 0 "Block" ;
VAL_ 2563112702 ValveLimitStatus 0 "Not limited" 1 "Operator Limited" 2 "Limited High" 3 "Limited Low" 4 "Reserved" 5 "Reserver" 6 "Non-recoverable Fault" 7 "Not available" ;
VAL_ 2563178238 ValveLimitStatus 0 "Not limited" 1 "Operator Limited" 2 "Limited High" 3 "Limited Low" 4 "Reserved" 5 "Reserver" 6 "Non-recoverable Fault" 7 "Not available" ;
VAL_ 2563178238 FailSafeMode 3 "NotAvailable" 2 "ErrorIndication" 1 "Float" 0 "Block" ;
VAL_ 2563178238 ValveState 15 "DoNotCare" 14 "ErrorIndication" 3 "Floating" 2 "Retract" 1 "Extend" 0 "Blocked" ;
VAL_ 2628452094 RF_ReportHiddenFiles 0 "DoNotReportHiddenFiles" 1 "ReportHiddenFiles" 255 "NotAvailable" ;
VAL_ 2628452094 SF_PositionMode 0 "From the beginning of the file" 1 "From the current pointer pos" 2 "From the end of the file" ;
VAL_ 2628452094 OF_FlagExclusiveAccess 0 "Open file for shared read access" 1 "Open file with exclusive access" ;
VAL_ 2628452094 OF_FlagAppend 0 "Open file for random access" 1 "Open file for appending data" ;
VAL_ 2628452094 SA_ATTR_Hidden 3 "Leave attribute 'hidden'" 0 "Set attribute 'hidden'" 1 "Clear attribute 'hidden'" ;
VAL_ 2628452094 OF_FlagCreateNew 0 "Open an existing file" 1 "Create new file if not existing" ;
VAL_ 2628452094 MF_MoveModeRecursive 0 "'recursive' mode is not set" 1 "'recursive' mode is set" ;
VAL_ 2628452094 DF_DeleteModeRecursive 0 "'recursive' mode is not set" 1 "'recursive' mode is set" ;
VAL_ 2628452094 MF_MoveModeForce 0 "'force' mode is not set" 1 "'force' mode is set" ;
VAL_ 2628452094 DF_DeleteModeForce 0 "'force' mode is not set" 1 "'force' mode is set" ;
VAL_ 2628452094 SA_ATTR_ReadOnly 3 "Leave attribute 'read-only'" 0 "Clear attribute 'read-only'" 1 "Set attribute 'read-only'" ;
VAL_ 2628452094 OF_FlagReadWrite 0 "Open file for reading only" 1 "Open file for writing only" 2 "Open file for reading & writing" 3 "Open directory for reading" ;
VAL_ 2628452094 MF_MoveModeCopy 0 "'copy' mode is not set" 1 "'copy' mode is set" ;
VAL_ 2628452094 DF_DeleteMode 0 "'copy' mode is not set" 1 "'copy' mode is set" ;
VAL_ 2628452094 VS_ReqVolumeToPrepareForRemoval 1 "RequestVolumeToPrepareForRemoval" ;
VAL_ 2628452094 VS_ReportVolumeUsedByClient 0 "ReportVolumeNotInUseByClient" 1 "ReportVolumeInUseByClient" ;
VAL_ 2628452094 CM_VersionNumber 0 "DIS" 1 "FDIS" 2 "FirstPublishedEditionOfIS" 3 "SecondPublishedEditionOfIS" 255 "CompliantToVersion2AndPrior" ;
VAL_ 2628452094 FSClientCommand 0 "ConnectionMaintenance" 16 "GetCurrentDirectoryRequest" 32 "OpenFileRequest" 33 "SeekFileRequest" 34 "ReadFileRequest" 35 "WriteFileRequest" 36 "CloseFileRequest" 48 "MoveFileRequest" 49 "DeleteFileRequest" 50 "GetFileAttributesRequest" 51 "SetFileAttributesRequest" 17 "ChangeCurrentDirectoryRequest" 52 "GetFileDateTimeRequest" 64 "VolumeInitializationRequest" 1 "GetFileServerProperties" 2 "VolumeStatusRequest" ;
VAL_ 2628517630 OF_ATTR_VolumeSupportsHidden 0 "No support of hidden attribute" 1 "Supports hidden attribute" ;
VAL_ 2628517630 OF_ATTR_VolumeIsCaseSensitive 0 "Is case-insensitive" 1 "Is case-sensitive" ;
VAL_ 2628517630 OF_ATTR_VolumeIsRemovable 0 "Is removable" 1 "Is not removable" ;
VAL_ 2628517630 OF_ATTR_SupportsLongFilenames 0 "Does not support long filename" 1 "Supports long filenames" ;
VAL_ 2628517630 OF_ATTR_IsDirectory 0 "Does not specifiy a directory" 1 "Specifes a directory" ;
VAL_ 2628517630 OF_ATTR_IsVolume 0 "Does not specifiy a volume" 1 "Specifies a volume" ;
VAL_ 2628517630 OF_ATTR_Hidden 0 "'Hidden' attribute is not set" 1 "'Hidden' attribute is set" ;
VAL_ 2628517630 OF_ATTR_ReadOnly 0 "'Read-only' attribute is not set" 1 "'Read-only' attribute is set" ;
VAL_ 2628517630 GA_ATTR_VolumeIsCaseSensitive 0 "Is case-insensitive" 1 "Is case-sensitive" ;
VAL_ 2628517630 VI_ATTR_VolumeRemovable 0 "Is removable" 1 "Is not removable" ;
VAL_ 2628517630 GA_ATTR_VolumeIsRemovable 0 "Is removable" 1 "Is not removable" ;
VAL_ 2628517630 VI_ATTR_SupportsLongFilenames 0 "Does not support long filename" 1 "Supports long filenames" ;
VAL_ 2628517630 GA_ATTR_SupportsLongFilenames 0 "Does not support long filename" 1 "Supports long filenames" ;
VAL_ 2628517630 GA_ATTR_IsDirectory 0 "Does not specifiy a directory" 1 "Specifes a directory" ;
VAL_ 2628517630 VI_ATTR_IsDirectory 0 "Does not specify a directory" 1 "Secifies a directory" ;
VAL_ 2628517630 VI_ATTR_IsVolume 0 "Does not specifiy a volume" 1 "Specifies a volume" ;
VAL_ 2628517630 GA_ATTR_IsVolume 0 "Does not specifiy a volume" 1 "Specifies a volume" ;
VAL_ 2628517630 VI_ATTR_VolumeSupportsHidden 0 "No support of hidden attribute" 1 "Supports hidden attribute" ;
VAL_ 2628517630 GA_ATTR_VolumeSupportsHidden 0 "No support of hidden attribute" 1 "Supports hidden attribute" ;
VAL_ 2628517630 VI_ATTR_Hidden 0 "'Hidden' attribute is not set" 1 "'Hidden' attribute is set" ;
VAL_ 2628517630 GA_ATTR_Hidden 0 "'Hidden' attribute is not set" 1 "'Hidden' attribute is set" ;
VAL_ 2628517630 VI_ATTR_ReadOnly 0 "'Read-only' attribute is not set" 1 "'Read-only' attribute is set" ;
VAL_ 2628517630 GA_ATTR_ReadOnly 0 "'Read-only' attribute is not set" 1 "'Read-only' attribute is set" ;
VAL_ 2628517630 GSP_SupportMultipleVolumes 0 "Beschreibung für den Wert '0'" ;
VAL_ 2628517630 FDT_ErrorCode 0 "Success" 1 "Access Denied" 3 "Too many files open" 4 "File, path or volume not found" 6 "Invalid given source name" 10 "Media is not present" 44 "Any other error" 43 "Out ot memory" 11 "Failure during a read operation" 13 " Volume possibly not initialized" ;
VAL_ 2628517630 RF_ErrorCode 45 "File pointer at end of file" 44 "Any other error" 42 "Invalid request length" 5 "Invalid handle" 0 "Success" 11 "Failure during read operation" 43 "Out of memory" 1 "Access denied" ;
VAL_ 2628517630 SF_ErrorCode 0 "Success" 5 "Invalid handle" 42 "Invalid request length" 44 "Any other error" 45 "File pointer at end of file" 11 "Failure during read operation" 43 "Out of memory" ;
VAL_ 2628517630 OF_ErrorCode 0 "Success" 1 "Access Denied" 2 "Invalid Access" 3 "Too many files open" 4 "File, path or volume not found" 6 "Invalid given source name" 8 "Volume out of free space" 10 "Media is not present" 44 "Any other error" 43 "Out of memory" 13 "Volume possibly not initialized" ;
VAL_ 2628517630 WF_ErrorCode 0 "Success" 1 "Access Denied" 5 "Invalid handle" 8 "Volume out of free space" 9 "Failure during a write operation" 42 "Invalid request length" 44 "Any other error" 43 "Out of memory" ;
VAL_ 2628517630 CF_ErrorCode 0 "Success" 1 "Access Denied" 5 "Invalid handle" 8 "Volume out of free space" 9 "Failure during a write operation" 44 "Any other error" 43 "Out ot memory" ;
VAL_ 2628517630 MF_ErrorCode 0 "Success" 1 "Access Denied" 3 "Too many files open" 6 "Invalid given source name" 7 "Invalid given destination name" 8 "Volume out of free space" 9 "Verify failure during a write op" 10 "Media is not present" 44 "Any other error" 43 "Out of memory" 4 "File, path or volume not found" 13 "Volume possibly not initialized" ;
VAL_ 2628517630 GA_ErrorCode 0 "Success" 1 "Access Denied" 3 "Too many files open" 4 "File, path or volume not found" 6 "Invalid given source name" 10 "Media is not present" 44 "Any other error" 43 "Out of memory" 11 "Failure during read operation" 13 "Volume possibly not initialized" ;
VAL_ 2628517630 SA_ErrorCode 0 "Success" 1 "Access Denied" 3 "Too many files open" 4 "File, path or volume not found" 6 "Invalid given source name" 8 "Volume out of free space" 9 "Failure during write operation" 10 "Media is not present" 44 "Any other error" 43 "Out of memory" 11 "Failure during read operation" 13 "Volume possibly not initialized" ;
VAL_ 2628517630 GCD_ErrorCode 0 "Success" 10 "Media is not present" 44 "Any other error" 43 "Out of Memory" 13 "Volume possibly not initialized" ;
VAL_ 2628517630 CCD_ErrorCode 0 "Success" 10 "Media is not present" 44 "Any other error" 43 "Out of memory" 13 "Volume possibly not initialized" 1 "Access denied" 2 "Invalid Access" 4 "File, path or volume not found" 7 "Invalid destination name given" ;
VAL_ 2628517630 DF_ErrorCode 0 "Success" 1 "Access Denied" 4 "File, path or volume not found" 6 "Invalid given source name" 10 "Media is not present" 44 "Any other error" 43 "Out of memory" 9 "Failure during write operation" 11 "Failure during read operation" 13 "Volume possibly not initialized" ;
VAL_ 2628517630 VI_ErrorCode 0 "Success" 1 "Access Denied" 4 "File, path or volume not found" 6 "Invalid given source name" 8 "Volume out of free space" 9 "Failure during write operation" 42 "Invalid request length" 44 "Any other error" 43 "Out of memory" 10 "Media is not present" 11 "Failure during read operation" 13 "Volume possibly not initialized" ;
VAL_ 2628517630 GSP_VersionNumber 0 "DIS" 1 "FDIS" 2 "FirstPublishedEditionOfIS" 3 "SecondPublishedEditionOfIS" 255 "CompliantToVersion2AndPrior" ;
VAL_ 2628517630 VS_VolumeStatus 0 "Present" 1 "InUse" 2 "PreparingForRemoval" 3 "Removed" ;
VAL_ 2628517630 FSServerCommand 0 "FileServerStatus" 16 "GetCurrentDirectoryResponse" 32 "OpenFileResponse" 33 "SeekFileResponse" 34 "ReadFileResponse" 35 "WriteFileResponse" 36 "CloseFileResponse" 48 "MoveFileResponse" 49 "DeleteFileResponse" 50 "GetFileAttributesResponse" 51 "SetFileAttributeResponse" 17 "ChangeCurrentDirectoryResponse" 52 "GetFileDateTimeResponse" 64 "VolumeInitializationResponse" 1 "GetFileServerPropertiesResponse" 2 "VolumeStatusResponse" ;
VAL_ 2364540158 EngStarterMode 15 "not available" 14 "error" 12 "starter inhibited  reason unknown" 9 "starter inhibited due to intake air shutoff valve being active" 8 "starter inhibited due to starter overtemp" 7 "starter inhibited due to active immobilizer" 6 "starter inhibited due to driveline engaged or other transmission inhibit" 5 "starter inhibited due to engine not ready for start preheating" 4 "starter inhibited due to engine already running" 3 "start finished starter not active after having been actively engaged after 50ms mode goes to 0000" 2 "starter active gear engaged" 1 "starter active gear not engaged" 0 "start not requested" 10 "starter inhibited due to active SCR inducement" 11 "Reserved" 13 "error legacy implementation only use 1110" ;
VAL_ 2364540158 ActlEngPrcntTorqueHighResolution 0 "0000" 1 "0125" 7 "0875" 8 "1111  not available" ;
VAL_ 2563309310 PGNumber 255 "NotAvailable" ;
VAL_ 2563309310 ControlByte 255 "EAbort" 20 "ERTS" 21 "ECTS" 22 "EDPO" 23 "EEoMACK" ;
VAL_ 2563309310 ConnectionAbortReason 15 "ECTS requested packets exceeds message size" 14 "Unexpected ECTS PGN (PGN in ECTS is bad)" 13 "Deprecated use 254 instead" 12 "Bad EDPO offset" 11 "EDPO number of packets is greater than CTS" 10 "Unexpected EDPO PGN (PGN in EDPO is bad)" 9 "Unexpected EDPO packet" 8 "Duplicate sequence number" 1 "Already in one or more connection-managed sessions" 2 "System resources were needed for another task" 3 "Timeout occurred" 4 "CTS messages received when data transfer is in progress" 5 "Maximum retransmit request limit reached" 6 "Unexpected data transfer packet" 7 "Bad sequence number" ;
VAL_ 2381841918 RefrenceStationType5 14 "Error" 1 "GLONASS" 0 "GPS" ;
VAL_ 2381841918 RefrenceStationType4 14 "Error" 1 "GLONASS" 0 "GPS" ;
VAL_ 2381841918 RefrenceStationType3 14 "Error" 1 "GLONASS" 0 "GPS" ;
VAL_ 2381841918 RefrenceStationType2 14 "Error" 1 "GLONASS" 0 "GPS" ;
VAL_ 2381841918 RefrenceStationType1 14 "Error" 1 "GLONASS" 0 "GPS" ;
VAL_ 2381841918 GNSSIntegrity 3 "Unsafe" 2 "Caution" 1 "Safe" 0 "No integrity checking" ;
VAL_ 2381841918 GNSSMethod 14 "Error" 8 "Simulate mode" 7 "Manual input" 6 "Estimated (DR) mode" 5 "RTK float" 4 "RTK fixed integer" 3 "Precise GNSS" 2 "DGNSS fix" 1 "GNSS fix" 0 "no GPS" ;
VAL_ 2381841918 TypeOfSystem 4 "GPS and SBAS and GLONASS" 3 "GPS and SBAS(WAAS)" 2 "GPS and GLONASS" 1 "GLONASS" 0 "GPS" ;
VAL_ 2566849534 ManufacturerSpecific8 255 "NotAvailable" ;
VAL_ 2566849534 ManufacturerSpecific7 255 "NotAvailable" ;
VAL_ 2566849534 ManufacturerSpecific6 255 "NotAvailable" ;
VAL_ 2566849534 ManufacturerSpecific5 255 "NotAvailable" ;
VAL_ 2566849534 ManufacturerSpecific4 255 "NotAvailable" ;
VAL_ 2566849534 ManufacturerSpecific3 255 "NotAvailable" ;
VAL_ 2566849534 ManufacturerSpecific2 255 "NotAvailable" ;
VAL_ 2566849534 ManufacturerSpecific1 255 "NotAvailable" ;
VAL_ 2566849278 ManufacturerSpecific8 255 "NotAvailable" ;
VAL_ 2566849278 ManufacturerSpecific7 255 "NotAvailable" ;
VAL_ 2566849278 ManufacturerSpecific6 255 "NotAvailable" ;
VAL_ 2566849278 ManufacturerSpecific5 255 "NotAvailable" ;
VAL_ 2566849278 ManufacturerSpecific4 255 "NotAvailable" ;
VAL_ 2566849278 ManufacturerSpecific3 255 "NotAvailable" ;
VAL_ 2566849278 ManufacturerSpecific2 255 "NotAvailable" ;
VAL_ 2566849278 ManufacturerSpecific1 255 "NotAvailable" ;
VAL_ 2566849022 ManufacturerSpecific8 255 "NotAvailable" ;
VAL_ 2566849022 ManufacturerSpecific7 255 "NotAvailable" ;
VAL_ 2566849022 ManufacturerSpecific6 255 "NotAvailable" ;
VAL_ 2566849022 ManufacturerSpecific5 255 "NotAvailable" ;
VAL_ 2566849022 ManufacturerSpecific4 255 "NotAvailable" ;
VAL_ 2566849022 ManufacturerSpecific3 255 "NotAvailable" ;
VAL_ 2566849022 ManufacturerSpecific2 255 "NotAvailable" ;
VAL_ 2566849022 ManufacturerSpecific1 255 "NotAvailable" ;
VAL_ 2566848766 ManufacturerSpecific8 255 "NotAvailable" ;
VAL_ 2566848766 ManufacturerSpecific7 255 "NotAvailable" ;
VAL_ 2566848766 ManufacturerSpecific6 255 "NotAvailable" ;
VAL_ 2566848766 ManufacturerSpecific5 255 "NotAvailable" ;
VAL_ 2566848766 ManufacturerSpecific4 255 "NotAvailable" ;
VAL_ 2566848766 ManufacturerSpecific3 255 "NotAvailable" ;
VAL_ 2566848766 ManufacturerSpecific2 255 "NotAvailable" ;
VAL_ 2566848766 ManufacturerSpecific1 255 "NotAvailable" ;
SG_MUL_VAL_ 2619670270 TIMMessageType GroupFunctionValue 1-32, 64-68, 70-70;
SG_MUL_VAL_ 2619604734 ReflectedRequestCounter GroupFunctionValue 1-32, 64-68, 70-70;
SG_MUL_VAL_ 2619604734 TIMMessageType GroupFunctionValue 1-32, 64-68, 70-70;
